VERSION ""

NS_ :

BS_:

BU_: ETH

BO_ 833 VCFRONT1_alertMatrix: 8 Vector__XXX
 SG_ VCFRONT1_matrixIndex M : 0|4@1+ (1,0) [0|0] "" Vector__XXX
 SG_ VCFRONT1_a001_WatchdogReset m0 : 4|1@1+ (1,0) [0|0] "" Vector__XXX
 SG_ VCFRONT1_a061_XCPConnected m1 : 4|1@1+ (1,0) [0|0] "" Vector__XXX
 SG_ VCFRONT1_a002_PowerLossReset m0 : 5|1@1+ (1,0) [0|0] "" Vector__XXX
 SG_ VCFRONT1_a062_XCPWasConnected m1 : 5|1@1+ (1,0) [0|0] "" Vector__XXX
 SG_ VCFRONT1_a122_ICR_MIA m2 : 5|1@1+ (1,0) [0|0] "" Vector__XXX
 SG_ VCFRONT1_a482_lvBridgeEFuseTrip m8 : 5|1@1+ (1,0) [0|0] "" Vector__XXX
 SG_ VCFRONT1_a003_SWAssertion m0 : 6|1@1+ (1,0) [0|0] "" Vector__XXX
 SG_ VCFRONT1_a063_SwitchFault m1 : 6|1@1+ (1,0) [0|0] "" Vector__XXX
 SG_ VCFRONT1_a423_rtosSleepFailed m7 : 6|1@1+ (1,0) [0|0] "" Vector__XXX
 SG_ VCFRONT1_a064_busSleepReqTimeout m1 : 7|1@1+ (1,0) [0|0] "" Vector__XXX
 SG_ VCFRONT1_a124_BB_MIA m2 : 7|1@1+ (1,0) [0|0] "" Vector__XXX
 SG_ VCFRONT1_a484_undervoltageSelfTestStuckOn m8 : 7|1@1+ (1,0) [0|0] "" Vector__XXX
 SG_ VCFRONT1_a005_CANTXError m0 : 8|1@1+ (1,0) [0|0] "" Vector__XXX
 SG_ VCFRONT1_a125_SCCM_MIA m2 : 8|1@1+ (1,0) [0|0] "" Vector__XXX
 SG_ VCFRONT1_a485_uvSelfTestLoadUnattemptedOnDbg m8 : 8|1@1+ (1,0) [0|0] "" Vector__XXX
 SG_ VCFRONT1_a006_CANTX_cyclicError m0 : 9|1@1+ (1,0) [0|0] "" Vector__XXX
 SG_ VCFRONT1_a126_EPAS3P_MIA m2 : 9|1@1+ (1,0) [0|0] "" Vector__XXX
 SG_ VCFRONT1_a486_undervoltageSelfTestBridgeSyncFailure m8 : 9|1@1+ (1,0) [0|0] "" Vector__XXX
 SG_ VCFRONT1_a127_iBoosterEFuseTrip m2 : 10|1@1+ (1,0) [0|0] "" Vector__XXX
 SG_ VCFRONT1_a128_vcrightEFuseTrip m2 : 11|1@1+ (1,0) [0|0] "" Vector__XXX
 SG_ VCFRONT1_a188_sleepFailed m3 : 11|1@1+ (1,0) [0|0] "" Vector__XXX
 SG_ VCFRONT1_a129_pcsEFuseTrip m2 : 12|1@1+ (1,0) [0|0] "" Vector__XXX
 SG_ VCFRONT1_a249_pcsOvClampTripped m4 : 12|1@1+ (1,0) [0|0] "" Vector__XXX
 SG_ VCFRONT1_a489_vnf1248SelfTestDebug m8 : 12|1@1+ (1,0) [0|0] "" Vector__XXX
 SG_ VCFRONT1_a130_autopilot2EFuseTrip m2 : 13|1@1+ (1,0) [0|0] "" Vector__XXX
 SG_ VCFRONT1_a250_pcsOvShutdownTripped m4 : 13|1@1+ (1,0) [0|0] "" Vector__XXX
 SG_ VCFRONT1_a490_vnf1248SelfTestFailure m8 : 13|1@1+ (1,0) [0|0] "" Vector__XXX
 SG_ VCFRONT1_a131_PCSCOMMON_MIA m2 : 14|1@1+ (1,0) [0|0] "" Vector__XXX
 SG_ VCFRONT1_a191_exitDriveDomainDown m3 : 14|1@1+ (1,0) [0|0] "" Vector__XXX
 SG_ VCFRONT1_a251_pcsOvShutdownSelfTestFailure m4 : 14|1@1+ (1,0) [0|0] "" Vector__XXX
 SG_ VCFRONT1_a491_vnf1248ConfigurationMismatch m8 : 14|1@1+ (1,0) [0|0] "" Vector__XXX
 SG_ VCFRONT1_a012_CPUReset m0 : 15|1@1+ (1,0) [0|0] "" Vector__XXX
 SG_ VCFRONT1_a132_epas2EFuseTrip m2 : 15|1@1+ (1,0) [0|0] "" Vector__XXX
 SG_ VCFRONT1_a252_pcsOvShutdownSelfTestStageFailure m4 : 15|1@1+ (1,0) [0|0] "" Vector__XXX
 SG_ VCFRONT1_a013_AlertManagerFault m0 : 16|1@1+ (1,0) [0|0] "" Vector__XXX
 SG_ VCFRONT1_a133_BRAKE_MIA m2 : 16|1@1+ (1,0) [0|0] "" Vector__XXX
 SG_ VCFRONT1_a253_pcsOvShutdownHighSideSelfTestDebug m4 : 16|1@1+ (1,0) [0|0] "" Vector__XXX
 SG_ VCFRONT1_a134_hvContactorsEFuseTrip m2 : 17|1@1+ (1,0) [0|0] "" Vector__XXX
 SG_ VCFRONT1_a015_NVMMError m0 : 18|1@1+ (1,0) [0|0] "" Vector__XXX
 SG_ VCFRONT1_a135_leftHeadlightEFuseTrip m2 : 18|1@1+ (1,0) [0|0] "" Vector__XXX
 SG_ VCFRONT1_a016_NVMMRecordError m0 : 19|1@1+ (1,0) [0|0] "" Vector__XXX
 SG_ VCFRONT1_a496_exitDriveWarningDomainDown m8 : 19|1@1+ (1,0) [0|0] "" Vector__XXX
 SG_ VCFRONT1_a017_NVMMStatusDbg m0 : 20|1@1+ (1,0) [0|0] "" Vector__XXX
 SG_ VCFRONT1_a077_VCBATT0_MIA m1 : 20|1@1+ (1,0) [0|0] "" Vector__XXX
 SG_ VCFRONT1_a617_APP_MIA m10 : 20|1@1+ (1,0) [0|0] "" Vector__XXX
 SG_ VCFRONT1_a018_HardFault m0 : 21|1@1+ (1,0) [0|0] "" Vector__XXX
 SG_ VCFRONT1_a078_VCBATT1_MIA m1 : 21|1@1+ (1,0) [0|0] "" Vector__XXX
 SG_ VCFRONT1_a019_BusFault m0 : 22|1@1+ (1,0) [0|0] "" Vector__XXX
 SG_ VCFRONT1_a079_VCBATT2_MIA m1 : 22|1@1+ (1,0) [0|0] "" Vector__XXX
 SG_ VCFRONT1_a080_VCFRONT0_MIA m1 : 23|1@1+ (1,0) [0|0] "" Vector__XXX
 SG_ VCFRONT1_a021_TaskSchedulerError m0 : 24|1@1+ (1,0) [0|0] "" Vector__XXX
 SG_ VCFRONT1_a081_VCFRONT1_MIA m1 : 24|1@1+ (1,0) [0|0] "" Vector__XXX
 SG_ VCFRONT1_a022_TaskInitError m0 : 25|1@1+ (1,0) [0|0] "" Vector__XXX
 SG_ VCFRONT1_a082_VCFRONT2_MIA m1 : 25|1@1+ (1,0) [0|0] "" Vector__XXX
 SG_ VCFRONT1_a262_vcrightVoltageMismatch m4 : 25|1@1+ (1,0) [0|0] "" Vector__XXX
 SG_ VCFRONT1_a263_pcsVoltageMismatch m4 : 26|1@1+ (1,0) [0|0] "" Vector__XXX
 SG_ VCFRONT1_a144_EPAS3S_MIA m2 : 27|1@1+ (1,0) [0|0] "" Vector__XXX
 SG_ VCFRONT1_a204_undervoltageLoadshedTriggered m3 : 27|1@1+ (1,0) [0|0] "" Vector__XXX
 SG_ VCFRONT1_a264_iBoosterVoltageMismatch m4 : 27|1@1+ (1,0) [0|0] "" Vector__XXX
 SG_ VCFRONT1_a205_overvoltageProtectionTriggered m3 : 28|1@1+ (1,0) [0|0] "" Vector__XXX
 SG_ VCFRONT1_a086_VCBATT_MIA m1 : 29|1@1+ (1,0) [0|0] "" Vector__XXX
 SG_ VCFRONT1_a266_EPAS2VoltageMismatch m4 : 29|1@1+ (1,0) [0|0] "" Vector__XXX
 SG_ VCFRONT1_a028_UsageFault m0 : 31|1@1+ (1,0) [0|0] "" Vector__XXX
 SG_ VCFRONT1_a029_CoreDump m0 : 32|1@1+ (1,0) [0|0] "" Vector__XXX
 SG_ VCFRONT1_a509_eFuseASICManagerStateMismatch m8 : 32|1@1+ (1,0) [0|0] "" Vector__XXX
 SG_ VCFRONT1_a030_ECULogUploadRequest m0 : 33|1@1+ (1,0) [0|0] "" Vector__XXX
 SG_ VCFRONT1_a090_APS_MIA m1 : 33|1@1+ (1,0) [0|0] "" Vector__XXX
 SG_ VCFRONT1_a031_UDSActive m0 : 34|1@1+ (1,0) [0|0] "" Vector__XXX
 SG_ VCFRONT1_a091_CMPD_MIA m1 : 34|1@1+ (1,0) [0|0] "" Vector__XXX
 SG_ VCFRONT1_a214_openCircuitDetected m3 : 37|1@1+ (1,0) [0|0] "" Vector__XXX
 SG_ VCFRONT1_a574_frontDriveInverterEFuseTrip m9 : 37|1@1+ (1,0) [0|0] "" Vector__XXX
 SG_ VCFRONT1_a036_UnknownIrq m0 : 39|1@1+ (1,0) [0|0] "" Vector__XXX
 SG_ VCFRONT1_a096_OCS1P_MIA m1 : 39|1@1+ (1,0) [0|0] "" Vector__XXX
 SG_ VCFRONT1_a216_powerCutoffImminent m3 : 39|1@1+ (1,0) [0|0] "" Vector__XXX
 SG_ VCFRONT1_a037_MemManageFault m0 : 40|1@1+ (1,0) [0|0] "" Vector__XXX
 SG_ VCFRONT1_a038_ProtFaultInfo m0 : 41|1@1+ (1,0) [0|0] "" Vector__XXX
 SG_ VCFRONT1_a098_DIR_MIA m1 : 41|1@1+ (1,0) [0|0] "" Vector__XXX
 SG_ VCFRONT1_a578_vbusFusedLoadShedEFuseTrip m9 : 41|1@1+ (1,0) [0|0] "" Vector__XXX
 SG_ VCFRONT1_a039_ProtFaultAddress m0 : 42|1@1+ (1,0) [0|0] "" Vector__XXX
 SG_ VCFRONT1_a040_Backtrace m0 : 43|1@1+ (1,0) [0|0] "" Vector__XXX
 SG_ VCFRONT1_a100_CANbus_MIA m1 : 43|1@1+ (1,0) [0|0] "" Vector__XXX
 SG_ VCFRONT1_a220_LVUnhealthy m3 : 43|1@1+ (1,0) [0|0] "" Vector__XXX
 SG_ VCFRONT1_a041_HighCPULoad m0 : 44|1@1+ (1,0) [0|0] "" Vector__XXX
 SG_ VCFRONT1_a581_harnessResistanceInfo m9 : 44|1@1+ (1,0) [0|0] "" Vector__XXX
 SG_ VCFRONT1_a042_HighStackUsage m0 : 45|1@1+ (1,0) [0|0] "" Vector__XXX
 SG_ VCFRONT1_a043_Task1msError m0 : 46|1@1+ (1,0) [0|0] "" Vector__XXX
 SG_ VCFRONT1_a103_CP_MIA m1 : 46|1@1+ (1,0) [0|0] "" Vector__XXX
 SG_ VCFRONT1_a223_bridgeOvervoltageSelfTestFailure m3 : 46|1@1+ (1,0) [0|0] "" Vector__XXX
 SG_ VCFRONT1_a044_Task10msError m0 : 47|1@1+ (1,0) [0|0] "" Vector__XXX
 SG_ VCFRONT1_a104_DAS_MIA m1 : 47|1@1+ (1,0) [0|0] "" Vector__XXX
 SG_ VCFRONT1_a164_eFuseLckoutMissing m2 : 47|1@1+ (1,0) [0|0] "" Vector__XXX
 SG_ VCFRONT1_a045_Task100msError m0 : 48|1@1+ (1,0) [0|0] "" Vector__XXX
 SG_ VCFRONT1_a105_TAS_MIA m1 : 48|1@1+ (1,0) [0|0] "" Vector__XXX
 SG_ VCFRONT1_a165_unxpctdEFuseLckout m2 : 48|1@1+ (1,0) [0|0] "" Vector__XXX
 SG_ VCFRONT1_a046_Task1000msError m0 : 49|1@1+ (1,0) [0|0] "" Vector__XXX
 SG_ VCFRONT1_a106_PCS_MIA m1 : 49|1@1+ (1,0) [0|0] "" Vector__XXX
 SG_ VCFRONT1_a107_BMS_MIA m1 : 50|1@1+ (1,0) [0|0] "" Vector__XXX
 SG_ VCFRONT1_a108_DIF_MIA m1 : 51|1@1+ (1,0) [0|0] "" Vector__XXX
 SG_ VCFRONT1_a229_LVHealthCompromised m3 : 52|1@1+ (1,0) [0|0] "" Vector__XXX
 SG_ VCFRONT1_a110_GTW_MIA m1 : 53|1@1+ (1,0) [0|0] "" Vector__XXX
 SG_ VCFRONT1_a590_vcrightPwrRationalityCurve m9 : 53|1@1+ (1,0) [0|0] "" Vector__XXX
 SG_ VCFRONT1_a111_EPBR_MIA m1 : 54|1@1+ (1,0) [0|0] "" Vector__XXX
 SG_ VCFRONT1_a591_vcrightFastBlowDetection m9 : 54|1@1+ (1,0) [0|0] "" Vector__XXX
 SG_ VCFRONT1_a112_EPBL_MIA m1 : 55|1@1+ (1,0) [0|0] "" Vector__XXX
 SG_ VCFRONT1_a113_UI_MIA m1 : 56|1@1+ (1,0) [0|0] "" Vector__XXX
 SG_ VCFRONT1_a114_ESP_MIA m1 : 57|1@1+ (1,0) [0|0] "" Vector__XXX
 SG_ VCFRONT1_a414_undervoltageSelfTestFailure m6 : 57|1@1+ (1,0) [0|0] "" Vector__XXX
 SG_ VCFRONT1_a115_VCSEC_MIA m1 : 58|1@1+ (1,0) [0|0] "" Vector__XXX
 SG_ VCFRONT1_a415_undervoltageSelfTestStuckOff m6 : 58|1@1+ (1,0) [0|0] "" Vector__XXX
 SG_ VCFRONT1_a475_vnf1248Fault m7 : 58|1@1+ (1,0) [0|0] "" Vector__XXX
 SG_ VCFRONT1_a116_VCRIGHT_MIA m1 : 59|1@1+ (1,0) [0|0] "" Vector__XXX
 SG_ VCFRONT1_a596_vcrightCurvePowerCutoff m9 : 59|1@1+ (1,0) [0|0] "" Vector__XXX
 SG_ VCFRONT1_a117_VCLEFT_MIA m1 : 60|1@1+ (1,0) [0|0] "" Vector__XXX
 SG_ VCFRONT1_a177_mcuAudioEFuseTrip m2 : 60|1@1+ (1,0) [0|0] "" Vector__XXX
 SG_ VCFRONT1_a597_vcrightFastBlowPowerCutoff m9 : 60|1@1+ (1,0) [0|0] "" Vector__XXX
 SG_ VCFRONT1_a058_inputRHighSyncDebug m0 : 61|1@1+ (1,0) [0|0] "" Vector__XXX
 SG_ VCFRONT1_a118_VCFRONT_MIA m1 : 61|1@1+ (1,0) [0|0] "" Vector__XXX
 SG_ VCFRONT1_a059_inputResistanceHigh m0 : 62|1@1+ (1,0) [0|0] "" Vector__XXX
 SG_ VCFRONT1_a119_SCCM_MIA m1 : 62|1@1+ (1,0) [0|0] "" Vector__XXX
 SG_ VCFRONT1_a060_engineeringBuild m0 : 63|1@1+ (1,0) [0|0] "" Vector__XXX
 SG_ VCFRONT1_a120_DI_DRIVE_MIA m1 : 63|1@1+ (1,0) [0|0] "" Vector__XXX

BO_ 834 VCFRONT2_alertMatrix: 8 Vector__XXX
 SG_ VCFRONT2_matrixIndex M : 0|4@1+ (1,0) [0|0] "" Vector__XXX
 SG_ VCFRONT2_a001_WatchdogReset m0 : 4|1@1+ (1,0) [0|0] "" Vector__XXX
 SG_ VCFRONT2_a061_XCPConnected m1 : 4|1@1+ (1,0) [0|0] "" Vector__XXX
 SG_ VCFRONT2_a301_wipersFactoryDisabled m5 : 4|1@1+ (1,0) [0|0] "" Vector__XXX
 SG_ VCFRONT2_a421_leftHeadlampUartCondition m7 : 4|1@1+ (1,0) [0|0] "" Vector__XXX
 SG_ VCFRONT2_a601_autopilotAirPurgeLimitReached m10 : 4|1@1+ (1,0) [0|0] "" Vector__XXX
 SG_ VCFRONT2_a661_mculessLeftHeadlampCurrentAlertDbg m11 : 4|1@1+ (1,0) [0|0] "" Vector__XXX
 SG_ VCFRONT2_a002_PowerLossReset m0 : 5|1@1+ (1,0) [0|0] "" Vector__XXX
 SG_ VCFRONT2_a062_XCPWasConnected m1 : 5|1@1+ (1,0) [0|0] "" Vector__XXX
 SG_ VCFRONT2_a122_ICR_MIA m2 : 5|1@1+ (1,0) [0|0] "" Vector__XXX
 SG_ VCFRONT2_a302_wiperCommError m5 : 5|1@1+ (1,0) [0|0] "" Vector__XXX
 SG_ VCFRONT2_a542_refrigerantReclaim m9 : 5|1@1+ (1,0) [0|0] "" Vector__XXX
 SG_ VCFRONT2_a003_SWAssertion m0 : 6|1@1+ (1,0) [0|0] "" Vector__XXX
 SG_ VCFRONT2_a063_SwitchFault m1 : 6|1@1+ (1,0) [0|0] "" Vector__XXX
 SG_ VCFRONT2_a123_VC_SECONDARY_LIGHTING_LEADER_MIA m2 : 6|1@1+ (1,0) [0|0] "" Vector__XXX
 SG_ VCFRONT2_a423_rtosSleepFailed m7 : 6|1@1+ (1,0) [0|0] "" Vector__XXX
 SG_ VCFRONT2_a543_compressorLowFlowDeliveryDetected m9 : 6|1@1+ (1,0) [0|0] "" Vector__XXX
 SG_ VCFRONT2_a663_leftHeadlampUartWaterMarkWarning m11 : 6|1@1+ (1,0) [0|0] "" Vector__XXX
 SG_ VCFRONT2_a064_busSleepReqTimeout m1 : 7|1@1+ (1,0) [0|0] "" Vector__XXX
 SG_ VCFRONT2_a124_BB_MIA m2 : 7|1@1+ (1,0) [0|0] "" Vector__XXX
 SG_ VCFRONT2_a184_cabinCoolingPerformanceAbnormal m3 : 7|1@1+ (1,0) [0|0] "" Vector__XXX
 SG_ VCFRONT2_a005_CANTXError m0 : 8|1@1+ (1,0) [0|0] "" Vector__XXX
 SG_ VCFRONT2_a125_SCCM_MIA m2 : 8|1@1+ (1,0) [0|0] "" Vector__XXX
 SG_ VCFRONT2_a365_burnInRoutineEntered m6 : 8|1@1+ (1,0) [0|0] "" Vector__XXX
 SG_ VCFRONT2_a665_leftHeadlampRetryInfo m11 : 8|1@1+ (1,0) [0|0] "" Vector__XXX
 SG_ VCFRONT2_a006_CANTX_cyclicError m0 : 9|1@1+ (1,0) [0|0] "" Vector__XXX
 SG_ VCFRONT2_a126_EPAS3P_MIA m2 : 9|1@1+ (1,0) [0|0] "" Vector__XXX
 SG_ VCFRONT2_a186_noDriveChgCableCon m3 : 9|1@1+ (1,0) [0|0] "" Vector__XXX
 SG_ VCFRONT2_a366_burnInRoutineExited m6 : 9|1@1+ (1,0) [0|0] "" Vector__XXX
 SG_ VCFRONT2_a546_leftLowOrHighBeamLightCondition m9 : 9|1@1+ (1,0) [0|0] "" Vector__XXX
 SG_ VCFRONT2_a606_chillerBattHeatingExit m10 : 9|1@1+ (1,0) [0|0] "" Vector__XXX
 SG_ VCFRONT2_a187_busesNotSleeping m3 : 10|1@1+ (1,0) [0|0] "" Vector__XXX
 SG_ VCFRONT2_a247_evapSolenoidFault m4 : 10|1@1+ (1,0) [0|0] "" Vector__XXX
 SG_ VCFRONT2_a367_dischargeRoutineEntered m6 : 10|1@1+ (1,0) [0|0] "" Vector__XXX
 SG_ VCFRONT2_a667_leftHeadlampRegionOrSideMismatch m11 : 10|1@1+ (1,0) [0|0] "" Vector__XXX
 SG_ VCFRONT2_a008_adaptiveHeadlightsUnavailableStalk m0 : 11|1@1+ (1,0) [0|0] "" Vector__XXX
 SG_ VCFRONT2_a188_sleepFailed m3 : 11|1@1+ (1,0) [0|0] "" Vector__XXX
 SG_ VCFRONT2_a368_dischargeRoutineExited m6 : 11|1@1+ (1,0) [0|0] "" Vector__XXX
 SG_ VCFRONT2_a009_LCCPurgeAttempted m0 : 12|1@1+ (1,0) [0|0] "" Vector__XXX
 SG_ VCFRONT2_a249_coolantValveBadMode m4 : 12|1@1+ (1,0) [0|0] "" Vector__XXX
 SG_ VCFRONT2_a369_reducedPowerDischarge m6 : 12|1@1+ (1,0) [0|0] "" Vector__XXX
 SG_ VCFRONT2_a489_ValveStuckFlagged m8 : 12|1@1+ (1,0) [0|0] "" Vector__XXX
 SG_ VCFRONT2_a669_thermalHVPowerBudgetActive m11 : 12|1@1+ (1,0) [0|0] "" Vector__XXX
 SG_ VCFRONT2_a250_headlampsNotAimed m4 : 13|1@1+ (1,0) [0|0] "" Vector__XXX
 SG_ VCFRONT2_a490_coolantPumpsNotIdentified m8 : 13|1@1+ (1,0) [0|0] "" Vector__XXX
 SG_ VCFRONT2_a610_driveEntryDelayed m10 : 13|1@1+ (1,0) [0|0] "" Vector__XXX
 SG_ VCFRONT2_a131_PCSCOMMON_MIA m2 : 14|1@1+ (1,0) [0|0] "" Vector__XXX
 SG_ VCFRONT2_a251_UIWakeupTrigger m4 : 14|1@1+ (1,0) [0|0] "" Vector__XXX
 SG_ VCFRONT2_a611_poorRadiatorHeatRejection m10 : 14|1@1+ (1,0) [0|0] "" Vector__XXX
 SG_ VCFRONT2_a012_CPUReset m0 : 15|1@1+ (1,0) [0|0] "" Vector__XXX
 SG_ VCFRONT2_a612_selfTestsBlockingDrive m10 : 15|1@1+ (1,0) [0|0] "" Vector__XXX
 SG_ VCFRONT2_a013_AlertManagerFault m0 : 16|1@1+ (1,0) [0|0] "" Vector__XXX
 SG_ VCFRONT2_a133_BRAKE_MIA m2 : 16|1@1+ (1,0) [0|0] "" Vector__XXX
 SG_ VCFRONT2_a254_pumpBatStopped m4 : 17|1@1+ (1,0) [0|0] "" Vector__XXX
 SG_ VCFRONT2_a374_lccInletSolenoidFault m6 : 17|1@1+ (1,0) [0|0] "" Vector__XXX
 SG_ VCFRONT2_a015_NVMMError m0 : 18|1@1+ (1,0) [0|0] "" Vector__XXX
 SG_ VCFRONT2_a135_coolantLevelLow m2 : 18|1@1+ (1,0) [0|0] "" Vector__XXX
 SG_ VCFRONT2_a195_drveBlckdVltgeTooHgh m3 : 18|1@1+ (1,0) [0|0] "" Vector__XXX
 SG_ VCFRONT2_a016_NVMMRecordError m0 : 19|1@1+ (1,0) [0|0] "" Vector__XXX
 SG_ VCFRONT2_a136_refrigDischTempSns m2 : 19|1@1+ (1,0) [0|0] "" Vector__XXX
 SG_ VCFRONT2_a017_NVMMStatusDbg m0 : 20|1@1+ (1,0) [0|0] "" Vector__XXX
 SG_ VCFRONT2_a077_VCBATT0_MIA m1 : 20|1@1+ (1,0) [0|0] "" Vector__XXX
 SG_ VCFRONT2_a137_refrigDischPresSns m2 : 20|1@1+ (1,0) [0|0] "" Vector__XXX
 SG_ VCFRONT2_a377_wiperParkFault m6 : 20|1@1+ (1,0) [0|0] "" Vector__XXX
 SG_ VCFRONT2_a617_APP_MIA m10 : 20|1@1+ (1,0) [0|0] "" Vector__XXX
 SG_ VCFRONT2_a018_HardFault m0 : 21|1@1+ (1,0) [0|0] "" Vector__XXX
 SG_ VCFRONT2_a078_VCBATT1_MIA m1 : 21|1@1+ (1,0) [0|0] "" Vector__XXX
 SG_ VCFRONT2_a138_refrigSuctTempSns m2 : 21|1@1+ (1,0) [0|0] "" Vector__XXX
 SG_ VCFRONT2_a378_wiperECUDebug m6 : 21|1@1+ (1,0) [0|0] "" Vector__XXX
 SG_ VCFRONT2_a618_cabinCoolingCapacityLimited m10 : 21|1@1+ (1,0) [0|0] "" Vector__XXX
 SG_ VCFRONT2_a019_BusFault m0 : 22|1@1+ (1,0) [0|0] "" Vector__XXX
 SG_ VCFRONT2_a079_VCBATT2_MIA m1 : 22|1@1+ (1,0) [0|0] "" Vector__XXX
 SG_ VCFRONT2_a139_refrigSuctPresSns m2 : 22|1@1+ (1,0) [0|0] "" Vector__XXX
 SG_ VCFRONT2_a499_loadShedPumpFlowRequest m8 : 22|1@1+ (1,0) [0|0] "" Vector__XXX
 SG_ VCFRONT2_a080_VCFRONT0_MIA m1 : 23|1@1+ (1,0) [0|0] "" Vector__XXX
 SG_ VCFRONT2_a140_coolantTempPtSns m2 : 23|1@1+ (1,0) [0|0] "" Vector__XXX
 SG_ VCFRONT2_a380_chillerExvWarning m6 : 23|1@1+ (1,0) [0|0] "" Vector__XXX
 SG_ VCFRONT2_a560_compressorHighSuperheat m9 : 23|1@1+ (1,0) [0|0] "" Vector__XXX
 SG_ VCFRONT2_a620_pumpAirLock m10 : 23|1@1+ (1,0) [0|0] "" Vector__XXX
 SG_ VCFRONT2_a021_TaskSchedulerError m0 : 24|1@1+ (1,0) [0|0] "" Vector__XXX
 SG_ VCFRONT2_a081_VCFRONT1_MIA m1 : 24|1@1+ (1,0) [0|0] "" Vector__XXX
 SG_ VCFRONT2_a141_coolantTempBatSns m2 : 24|1@1+ (1,0) [0|0] "" Vector__XXX
 SG_ VCFRONT2_a381_evaporatorExvWarning m6 : 24|1@1+ (1,0) [0|0] "" Vector__XXX
 SG_ VCFRONT2_a621_coolantAirPurgeIncomplete m10 : 24|1@1+ (1,0) [0|0] "" Vector__XXX
 SG_ VCFRONT2_a022_TaskInitError m0 : 25|1@1+ (1,0) [0|0] "" Vector__XXX
 SG_ VCFRONT2_a082_VCFRONT2_MIA m1 : 25|1@1+ (1,0) [0|0] "" Vector__XXX
 SG_ VCFRONT2_a142_exvMotorFault m2 : 25|1@1+ (1,0) [0|0] "" Vector__XXX
 SG_ VCFRONT2_a382_recircExvWarning m6 : 25|1@1+ (1,0) [0|0] "" Vector__XXX
 SG_ VCFRONT2_a622_pumpDetectsLowCoolantFlow m10 : 25|1@1+ (1,0) [0|0] "" Vector__XXX
 SG_ VCFRONT2_a143_powerLossDuringSleep m2 : 26|1@1+ (1,0) [0|0] "" Vector__XXX
 SG_ VCFRONT2_a383_lccExvWarning m6 : 26|1@1+ (1,0) [0|0] "" Vector__XXX
 SG_ VCFRONT2_a563_chargePortDoorOpenBlockedByBrake m9 : 26|1@1+ (1,0) [0|0] "" Vector__XXX
 SG_ VCFRONT2_a144_EPAS3S_MIA m2 : 27|1@1+ (1,0) [0|0] "" Vector__XXX
 SG_ VCFRONT2_a384_ccLeftExvWarning m6 : 27|1@1+ (1,0) [0|0] "" Vector__XXX
 SG_ VCFRONT2_a504_airInRefrigerantDetected m8 : 27|1@1+ (1,0) [0|0] "" Vector__XXX
 SG_ VCFRONT2_a564_leftHeadlampAimingDebug m9 : 27|1@1+ (1,0) [0|0] "" Vector__XXX
 SG_ VCFRONT2_a385_ccRightExvWarning m6 : 28|1@1+ (1,0) [0|0] "" Vector__XXX
 SG_ VCFRONT2_a565_userPresenceDisplayStateMismatch m9 : 28|1@1+ (1,0) [0|0] "" Vector__XXX
 SG_ VCFRONT2_a086_VCBATT_MIA m1 : 29|1@1+ (1,0) [0|0] "" Vector__XXX
 SG_ VCFRONT2_a386_exvMotorWarning m6 : 29|1@1+ (1,0) [0|0] "" Vector__XXX
 SG_ VCFRONT2_a446_cabinHVACUnavailableContext m7 : 29|1@1+ (1,0) [0|0] "" Vector__XXX
 SG_ VCFRONT2_a506_invalidRefrigerantSystemConfig m8 : 29|1@1+ (1,0) [0|0] "" Vector__XXX
 SG_ VCFRONT2_a566_leftFrontTurnLightFault m9 : 29|1@1+ (1,0) [0|0] "" Vector__XXX
 SG_ VCFRONT2_a447_cabinHVACUnavailable m7 : 30|1@1+ (1,0) [0|0] "" Vector__XXX
 SG_ VCFRONT2_a507_leftHeadlampAimingFault m8 : 30|1@1+ (1,0) [0|0] "" Vector__XXX
 SG_ VCFRONT2_a028_UsageFault m0 : 31|1@1+ (1,0) [0|0] "" Vector__XXX
 SG_ VCFRONT2_a568_leftDaytimeRunningLightFault m9 : 31|1@1+ (1,0) [0|0] "" Vector__XXX
 SG_ VCFRONT2_a029_CoreDump m0 : 32|1@1+ (1,0) [0|0] "" Vector__XXX
 SG_ VCFRONT2_a030_ECULogUploadRequest m0 : 33|1@1+ (1,0) [0|0] "" Vector__XXX
 SG_ VCFRONT2_a090_APS_MIA m1 : 33|1@1+ (1,0) [0|0] "" Vector__XXX
 SG_ VCFRONT2_a150_pumpBatLowRPMCBang m2 : 33|1@1+ (1,0) [0|0] "" Vector__XXX
 SG_ VCFRONT2_a210_coolantValveCalib m3 : 33|1@1+ (1,0) [0|0] "" Vector__XXX
 SG_ VCFRONT2_a570_headlampsAdaptedToLeftHandTraffic m9 : 33|1@1+ (1,0) [0|0] "" Vector__XXX
 SG_ VCFRONT2_a630_leftHeadlampFactoryFault m10 : 33|1@1+ (1,0) [0|0] "" Vector__XXX
 SG_ VCFRONT2_a031_UDSActive m0 : 34|1@1+ (1,0) [0|0] "" Vector__XXX
 SG_ VCFRONT2_a091_CMPD_MIA m1 : 34|1@1+ (1,0) [0|0] "" Vector__XXX
 SG_ VCFRONT2_a451_refrigerantNotCommissioned m7 : 34|1@1+ (1,0) [0|0] "" Vector__XXX
 SG_ VCFRONT2_a511_DCDCSaturationLoadShed m8 : 34|1@1+ (1,0) [0|0] "" Vector__XXX
 SG_ VCFRONT2_a571_headlampsAdaptedToRightHandTraffic m9 : 34|1@1+ (1,0) [0|0] "" Vector__XXX
 SG_ VCFRONT2_a452_dischargePresSensIntermittent m7 : 35|1@1+ (1,0) [0|0] "" Vector__XXX
 SG_ VCFRONT2_a572_hvacCompressorEFuseTrip m9 : 35|1@1+ (1,0) [0|0] "" Vector__XXX
 SG_ VCFRONT2_a153_userPresenceDisplayMismatchClrd m2 : 36|1@1+ (1,0) [0|0] "" Vector__XXX
 SG_ VCFRONT2_a273_wiperFrictionModelFault m4 : 36|1@1+ (1,0) [0|0] "" Vector__XXX
 SG_ VCFRONT2_a393_ambientTempNetworkSna m6 : 36|1@1+ (1,0) [0|0] "" Vector__XXX
 SG_ VCFRONT2_a453_dischargeTempSensIntermittent m7 : 36|1@1+ (1,0) [0|0] "" Vector__XXX
 SG_ VCFRONT2_a214_ptPumpCompromised m3 : 37|1@1+ (1,0) [0|0] "" Vector__XXX
 SG_ VCFRONT2_a394_pressureSensorCheckFault m6 : 37|1@1+ (1,0) [0|0] "" Vector__XXX
 SG_ VCFRONT2_a454_suctionPresSensIntermittent m7 : 37|1@1+ (1,0) [0|0] "" Vector__XXX
 SG_ VCFRONT2_a155_autopilotDriveNotAuthed m2 : 38|1@1+ (1,0) [0|0] "" Vector__XXX
 SG_ VCFRONT2_a215_ptPumpMIA m3 : 38|1@1+ (1,0) [0|0] "" Vector__XXX
 SG_ VCFRONT2_a395_pressureSensorCheckInconclusive m6 : 38|1@1+ (1,0) [0|0] "" Vector__XXX
 SG_ VCFRONT2_a455_suctionTempSensIntermittent m7 : 38|1@1+ (1,0) [0|0] "" Vector__XXX
 SG_ VCFRONT2_a036_UnknownIrq m0 : 39|1@1+ (1,0) [0|0] "" Vector__XXX
 SG_ VCFRONT2_a096_OCS1P_MIA m1 : 39|1@1+ (1,0) [0|0] "" Vector__XXX
 SG_ VCFRONT2_a396_coolantLevelLowUserFacing m6 : 39|1@1+ (1,0) [0|0] "" Vector__XXX
 SG_ VCFRONT2_a456_liquidPresSensIntermittent m7 : 39|1@1+ (1,0) [0|0] "" Vector__XXX
 SG_ VCFRONT2_a037_MemManageFault m0 : 40|1@1+ (1,0) [0|0] "" Vector__XXX
 SG_ VCFRONT2_a217_battPumpCompromised m3 : 40|1@1+ (1,0) [0|0] "" Vector__XXX
 SG_ VCFRONT2_a397_temperatureSensorCheckFault m6 : 40|1@1+ (1,0) [0|0] "" Vector__XXX
 SG_ VCFRONT2_a457_liquidTempSensIntermittent m7 : 40|1@1+ (1,0) [0|0] "" Vector__XXX
 SG_ VCFRONT2_a697_leftHeadlampNotAimed m11 : 40|1@1+ (1,0) [0|0] "" Vector__XXX
 SG_ VCFRONT2_a038_ProtFaultInfo m0 : 41|1@1+ (1,0) [0|0] "" Vector__XXX
 SG_ VCFRONT2_a098_DIR_MIA m1 : 41|1@1+ (1,0) [0|0] "" Vector__XXX
 SG_ VCFRONT2_a218_socMonitorDetectedThresholdSoc m3 : 41|1@1+ (1,0) [0|0] "" Vector__XXX
 SG_ VCFRONT2_a398_tempSensorCheckInconclusive m6 : 41|1@1+ (1,0) [0|0] "" Vector__XXX
 SG_ VCFRONT2_a458_grosslyLowRefrigerant m7 : 41|1@1+ (1,0) [0|0] "" Vector__XXX
 SG_ VCFRONT2_a578_vbusFusedLowCurrentFeedEFuseTrip m9 : 41|1@1+ (1,0) [0|0] "" Vector__XXX
 SG_ VCFRONT2_a039_ProtFaultAddress m0 : 42|1@1+ (1,0) [0|0] "" Vector__XXX
 SG_ VCFRONT2_a159_coolantValveFault m2 : 42|1@1+ (1,0) [0|0] "" Vector__XXX
 SG_ VCFRONT2_a279_refrigLiquidTempSns m4 : 42|1@1+ (1,0) [0|0] "" Vector__XXX
 SG_ VCFRONT2_a459_thermalFillAndDrive m7 : 42|1@1+ (1,0) [0|0] "" Vector__XXX
 SG_ VCFRONT2_a040_Backtrace m0 : 43|1@1+ (1,0) [0|0] "" Vector__XXX
 SG_ VCFRONT2_a100_CANbus_MIA m1 : 43|1@1+ (1,0) [0|0] "" Vector__XXX
 SG_ VCFRONT2_a160_compressorInhibited m2 : 43|1@1+ (1,0) [0|0] "" Vector__XXX
 SG_ VCFRONT2_a280_refrigLiquidPresSns m4 : 43|1@1+ (1,0) [0|0] "" Vector__XXX
 SG_ VCFRONT2_a460_hardIsentropicTdFailed m7 : 43|1@1+ (1,0) [0|0] "" Vector__XXX
 SG_ VCFRONT2_a041_HighCPULoad m0 : 44|1@1+ (1,0) [0|0] "" Vector__XXX
 SG_ VCFRONT2_a161_compressorSelfFault m2 : 44|1@1+ (1,0) [0|0] "" Vector__XXX
 SG_ VCFRONT2_a281_alcoholInterlockBlockingDrive m4 : 44|1@1+ (1,0) [0|0] "" Vector__XXX
 SG_ VCFRONT2_a042_HighStackUsage m0 : 45|1@1+ (1,0) [0|0] "" Vector__XXX
 SG_ VCFRONT2_a162_compressorInhibitedContext m2 : 45|1@1+ (1,0) [0|0] "" Vector__XXX
 SG_ VCFRONT2_a282_coolantLevelSensorFault m4 : 45|1@1+ (1,0) [0|0] "" Vector__XXX
 SG_ VCFRONT2_a043_Task1msError m0 : 46|1@1+ (1,0) [0|0] "" Vector__XXX
 SG_ VCFRONT2_a103_CP_MIA m1 : 46|1@1+ (1,0) [0|0] "" Vector__XXX
 SG_ VCFRONT2_a163_compressorDisabledFSR m2 : 46|1@1+ (1,0) [0|0] "" Vector__XXX
 SG_ VCFRONT2_a283_thmlFanLimitedByCurrent m4 : 46|1@1+ (1,0) [0|0] "" Vector__XXX
 SG_ VCFRONT2_a044_Task10msError m0 : 47|1@1+ (1,0) [0|0] "" Vector__XXX
 SG_ VCFRONT2_a104_DAS_MIA m1 : 47|1@1+ (1,0) [0|0] "" Vector__XXX
 SG_ VCFRONT2_a284_chillerExvFault m4 : 47|1@1+ (1,0) [0|0] "" Vector__XXX
 SG_ VCFRONT2_a464_highFlowIndexHighSubcoolFlagged m7 : 47|1@1+ (1,0) [0|0] "" Vector__XXX
 SG_ VCFRONT2_a045_Task100msError m0 : 48|1@1+ (1,0) [0|0] "" Vector__XXX
 SG_ VCFRONT2_a105_TAS_MIA m1 : 48|1@1+ (1,0) [0|0] "" Vector__XXX
 SG_ VCFRONT2_a225_driveBlckdByShowroom m3 : 48|1@1+ (1,0) [0|0] "" Vector__XXX
 SG_ VCFRONT2_a285_evaporatorExvFault m4 : 48|1@1+ (1,0) [0|0] "" Vector__XXX
 SG_ VCFRONT2_a465_lowFlowIndexHighSubcoolFlagged m7 : 48|1@1+ (1,0) [0|0] "" Vector__XXX
 SG_ VCFRONT2_a585_bothHeadlampsInternalError m9 : 48|1@1+ (1,0) [0|0] "" Vector__XXX
 SG_ VCFRONT2_a046_Task1000msError m0 : 49|1@1+ (1,0) [0|0] "" Vector__XXX
 SG_ VCFRONT2_a106_PCS_MIA m1 : 49|1@1+ (1,0) [0|0] "" Vector__XXX
 SG_ VCFRONT2_a226_battPumpMIA m3 : 49|1@1+ (1,0) [0|0] "" Vector__XXX
 SG_ VCFRONT2_a286_recircExvFault m4 : 49|1@1+ (1,0) [0|0] "" Vector__XXX
 SG_ VCFRONT2_a466_highFlowIndexLowSubcoolFlagged m7 : 49|1@1+ (1,0) [0|0] "" Vector__XXX
 SG_ VCFRONT2_a107_BMS_MIA m1 : 50|1@1+ (1,0) [0|0] "" Vector__XXX
 SG_ VCFRONT2_a167_leftHCMMIA m2 : 50|1@1+ (1,0) [0|0] "" Vector__XXX
 SG_ VCFRONT2_a287_lccExvFault m4 : 50|1@1+ (1,0) [0|0] "" Vector__XXX
 SG_ VCFRONT2_a467_lowPowerIndexFlagged m7 : 50|1@1+ (1,0) [0|0] "" Vector__XXX
 SG_ VCFRONT2_a108_DIF_MIA m1 : 51|1@1+ (1,0) [0|0] "" Vector__XXX
 SG_ VCFRONT2_a288_ccLeftExvFault m4 : 51|1@1+ (1,0) [0|0] "" Vector__XXX
 SG_ VCFRONT2_a468_highPowerIndexFlagged m7 : 51|1@1+ (1,0) [0|0] "" Vector__XXX
 SG_ VCFRONT2_a289_ccRightExvFault m4 : 52|1@1+ (1,0) [0|0] "" Vector__XXX
 SG_ VCFRONT2_a409_invalidConfiguration m6 : 52|1@1+ (1,0) [0|0] "" Vector__XXX
 SG_ VCFRONT2_a469_prvPopDetected m7 : 52|1@1+ (1,0) [0|0] "" Vector__XXX
 SG_ VCFRONT2_a110_GTW_MIA m1 : 53|1@1+ (1,0) [0|0] "" Vector__XXX
 SG_ VCFRONT2_a470_implausiblePdPlDetected m7 : 53|1@1+ (1,0) [0|0] "" Vector__XXX
 SG_ VCFRONT2_a111_EPBR_MIA m1 : 54|1@1+ (1,0) [0|0] "" Vector__XXX
 SG_ VCFRONT2_a171_driveBlckdByMsmtch m2 : 54|1@1+ (1,0) [0|0] "" Vector__XXX
 SG_ VCFRONT2_a471_hcm5Debug m7 : 54|1@1+ (1,0) [0|0] "" Vector__XXX
 SG_ VCFRONT2_a531_lowPowerIndexFlaggedUserFacing m8 : 54|1@1+ (1,0) [0|0] "" Vector__XXX
 SG_ VCFRONT2_a112_EPBL_MIA m1 : 55|1@1+ (1,0) [0|0] "" Vector__XXX
 SG_ VCFRONT2_a172_wsteHtBlckdByMsmtch m2 : 55|1@1+ (1,0) [0|0] "" Vector__XXX
 SG_ VCFRONT2_a232_lowSideControllerHighFdbk m3 : 55|1@1+ (1,0) [0|0] "" Vector__XXX
 SG_ VCFRONT2_a053_wiperCommErrorUser m0 : 56|1@1+ (1,0) [0|0] "" Vector__XXX
 SG_ VCFRONT2_a113_UI_MIA m1 : 56|1@1+ (1,0) [0|0] "" Vector__XXX
 SG_ VCFRONT2_a173_HVBlckdByMsmtch m2 : 56|1@1+ (1,0) [0|0] "" Vector__XXX
 SG_ VCFRONT2_a054_compressorLowFlowUserFacing m0 : 57|1@1+ (1,0) [0|0] "" Vector__XXX
 SG_ VCFRONT2_a114_ESP_MIA m1 : 57|1@1+ (1,0) [0|0] "" Vector__XXX
 SG_ VCFRONT2_a174_driveNotAuthed m2 : 57|1@1+ (1,0) [0|0] "" Vector__XXX
 SG_ VCFRONT2_a294_leftSideRepeaterLightFault m4 : 57|1@1+ (1,0) [0|0] "" Vector__XXX
 SG_ VCFRONT2_a474_leftHeadlampInternalError m7 : 57|1@1+ (1,0) [0|0] "" Vector__XXX
 SG_ VCFRONT2_a534_chillerExvCalibInitDebug m8 : 57|1@1+ (1,0) [0|0] "" Vector__XXX
 SG_ VCFRONT2_a115_VCSEC_MIA m1 : 58|1@1+ (1,0) [0|0] "" Vector__XXX
 SG_ VCFRONT2_a235_ptTempSnsIrrational m3 : 58|1@1+ (1,0) [0|0] "" Vector__XXX
 SG_ VCFRONT2_a355_coolantSysLockout m5 : 58|1@1+ (1,0) [0|0] "" Vector__XXX
 SG_ VCFRONT2_a535_evapExvCalibInitDebug m8 : 58|1@1+ (1,0) [0|0] "" Vector__XXX
 SG_ VCFRONT2_a116_VCRIGHT_MIA m1 : 59|1@1+ (1,0) [0|0] "" Vector__XXX
 SG_ VCFRONT2_a176_vehicleInSelfTest m2 : 59|1@1+ (1,0) [0|0] "" Vector__XXX
 SG_ VCFRONT2_a236_batTempSnsIrrational m3 : 59|1@1+ (1,0) [0|0] "" Vector__XXX
 SG_ VCFRONT2_a356_refrigSysLockout m5 : 59|1@1+ (1,0) [0|0] "" Vector__XXX
 SG_ VCFRONT2_a536_recircExvCalibInitDebug m8 : 59|1@1+ (1,0) [0|0] "" Vector__XXX
 SG_ VCFRONT2_a117_VCLEFT_MIA m1 : 60|1@1+ (1,0) [0|0] "" Vector__XXX
 SG_ VCFRONT2_a537_lccExvCalibInitDebug m8 : 60|1@1+ (1,0) [0|0] "" Vector__XXX
 SG_ VCFRONT2_a058_inputRHighSyncDebug m0 : 61|1@1+ (1,0) [0|0] "" Vector__XXX
 SG_ VCFRONT2_a118_VCFRONT_MIA m1 : 61|1@1+ (1,0) [0|0] "" Vector__XXX
 SG_ VCFRONT2_a178_compLiquidPumpOut m2 : 61|1@1+ (1,0) [0|0] "" Vector__XXX
 SG_ VCFRONT2_a298_radiatorLowAirFlowDetected m4 : 61|1@1+ (1,0) [0|0] "" Vector__XXX
 SG_ VCFRONT2_a538_cclExvCalibInitDebug m8 : 61|1@1+ (1,0) [0|0] "" Vector__XXX
 SG_ VCFRONT2_a059_inputResistanceHigh m0 : 62|1@1+ (1,0) [0|0] "" Vector__XXX
 SG_ VCFRONT2_a119_SCCM_MIA m1 : 62|1@1+ (1,0) [0|0] "" Vector__XXX
 SG_ VCFRONT2_a539_ccrExvCalibInitDebug m8 : 62|1@1+ (1,0) [0|0] "" Vector__XXX
 SG_ VCFRONT2_a060_engineeringBuild m0 : 63|1@1+ (1,0) [0|0] "" Vector__XXX
 SG_ VCFRONT2_a120_DI_DRIVE_MIA m1 : 63|1@1+ (1,0) [0|0] "" Vector__XXX
 SG_ VCFRONT2_a240_lowSideCompromised m3 : 63|1@1+ (1,0) [0|0] "" Vector__XXX
 SG_ VCFRONT2_a360_ungracefulAccPlusExit m5 : 63|1@1+ (1,0) [0|0] "" Vector__XXX
 SG_ VCFRONT2_a420_holidayParty m6 : 63|1@1+ (1,0) [0|0] "" Vector__XXX
 SG_ VCFRONT2_a540_radiatorSteamDetected m8 : 63|1@1+ (1,0) [0|0] "" Vector__XXX

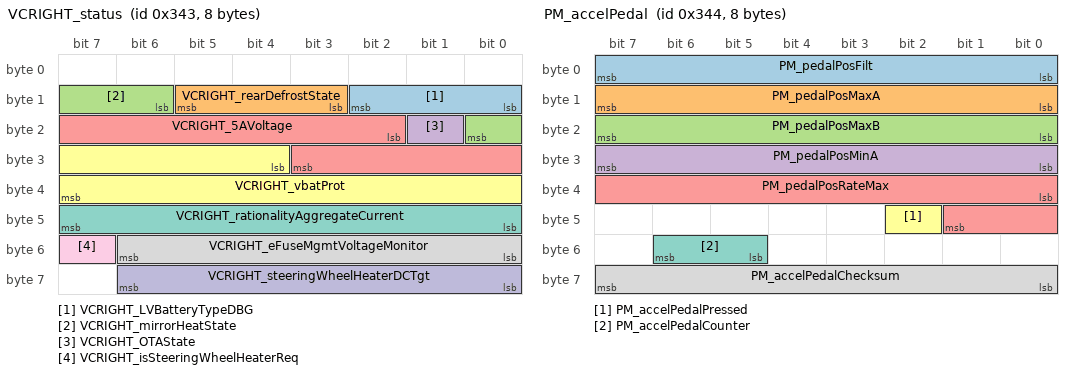
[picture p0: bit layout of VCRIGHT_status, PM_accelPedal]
BO_ 835 VCRIGHT_status: 8 Vector__XXX
 SG_ VCRIGHT_LVBatteryTypeDBG : 8|3@1+ (1,0) [0|0] "" Vector__XXX
 SG_ VCRIGHT_rearDefrostState : 11|3@1+ (1,0) [0|0] "" Vector__XXX
 SG_ VCRIGHT_mirrorHeatState : 14|3@1+ (1,0) [0|0] "" Vector__XXX
 SG_ VCRIGHT_OTAState : 17|1@1+ (1,0) [0|0] "" Vector__XXX
 SG_ VCRIGHT_5AVoltage : 18|10@1+ (0.005443676098,0) [0|0] "" Vector__XXX
 SG_ VCRIGHT_vbatProt : 28|12@1+ (0.005443676098,0) [0|0] "" Vector__XXX
 SG_ VCRIGHT_rationalityAggregateCurrent : 40|8@1+ (0.5,0) [0|0] "" Vector__XXX
 SG_ VCRIGHT_eFuseMgmtVoltageMonitor : 48|7@1+ (0.125,0) [0|0] "" Vector__XXX
 SG_ VCRIGHT_isSteeringWheelHeaterReq : 55|1@1+ (1,0) [0|0] "" Vector__XXX
 SG_ VCRIGHT_steeringWheelHeaterDCTgt : 56|7@1+ (0.01,0) [0|0] "" Vector__XXX

BO_ 836 PM_accelPedal: 8 Vector__XXX
 SG_ PM_pedalPosFilt : 0|8@1+ (0.4,0) [0|0] "" Vector__XXX
 SG_ PM_pedalPosMaxA : 8|8@1+ (0.4,0) [0|0] "" Vector__XXX
 SG_ PM_pedalPosMaxB : 16|8@1+ (0.4,0) [0|0] "" Vector__XXX
 SG_ PM_pedalPosMinA : 24|8@1+ (0.4,0) [0|0] "" Vector__XXX
 SG_ PM_pedalPosRateMax : 32|10@1+ (3,0) [0|0] "" Vector__XXX
 SG_ PM_accelPedalPressed : 42|1@1+ (1,0) [0|0] "" Vector__XXX
 SG_ PM_accelPedalCounter : 53|2@1+ (1,0) [0|0] "" Vector__XXX
 SG_ PM_accelPedalChecksum : 56|8@1+ (1,0) [0|0] "" Vector__XXX

BO_ 837 PTC_info: 8 Vector__XXX
 SG_ PTC_infoIndex M : 0|8@1+ (1,0) [0|0] "" Vector__XXX
 SG_ PTC_infoAppGitHash m17 : 8|56@1+ (1,0) [0|0] "" Vector__XXX
 SG_ PTC_infoBootGitHash m18 : 8|56@1+ (1,0) [0|0] "" Vector__XXX
 SG_ PTC_infoBootSvnRev m14 : 8|24@1+ (1,0) [0|0] "" Vector__XXX
 SG_ PTC_infoBootUdsProtoVersion m20 : 8|8@1+ (1,0) [0|0] "" Vector__XXX
 SG_ PTC_infoBuildType m10 : 8|3@1+ (1,0) [0|0] "" Vector__XXX
 SG_ PTC_infoPlatformType m13 : 8|8@1+ (1,0) [0|0] "" Vector__XXX
 SG_ PTC_infoBuildConfigId m10 : 16|16@1+ (1,0) [0|0] "" Vector__XXX
 SG_ PTC_infoPcbaId m11 : 16|8@1+ (1,0) [0|0] "" Vector__XXX
 SG_ PTC_infoAssemblyId m11 : 24|8@1+ (1,0) [0|0] "" Vector__XXX
 SG_ PTC_infoAppCrc m13 : 32|32@1+ (1,0) [0|0] "" Vector__XXX
 SG_ PTC_infoBootCrc m20 : 32|32@1+ (1,0) [0|0] "" Vector__XXX
 SG_ PTC_infoBootSvnUrlHash m14 : 32|32@1+ (1,0) [0|0] "" Vector__XXX
 SG_ PTC_infoHardwareId m10 : 32|16@1+ (1,0) [0|0] "" Vector__XXX
 SG_ PTC_infoUsageId m11 : 32|16@1+ (1,0) [0|0] "" Vector__XXX
 SG_ PTC_infoComponentId m10 : 48|16@1+ (1,0) [0|0] "" Vector__XXX
 SG_ PTC_infoSubUsageId m11 : 48|16@1+ (1,0) [0|0] "" Vector__XXX

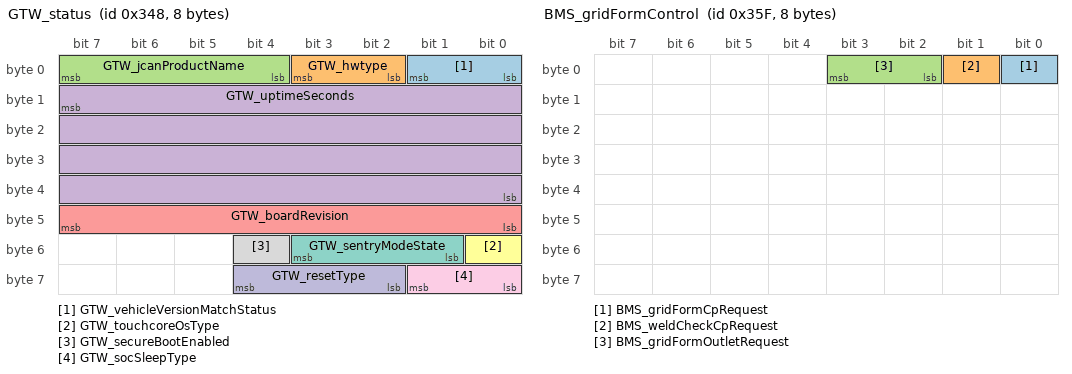
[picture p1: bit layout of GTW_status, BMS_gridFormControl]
BO_ 840 GTW_status: 8 Vector__XXX
 SG_ GTW_vehicleVersionMatchStatus : 0|2@1+ (1,0) [0|0] "" Vector__XXX
 SG_ GTW_hwtype : 2|2@1+ (1,0) [0|0] "" Vector__XXX
 SG_ GTW_jcanProductName : 4|4@1+ (1,0) [0|0] "" Vector__XXX
 SG_ GTW_uptimeSeconds : 15|32@0+ (1,0) [0|0] "" Vector__XXX
 SG_ GTW_boardRevision : 40|8@1+ (1,0) [0|0] "" Vector__XXX
 SG_ GTW_touchcoreOsType : 48|1@1+ (1,0) [0|0] "" Vector__XXX
 SG_ GTW_sentryModeState : 49|3@1+ (1,0) [0|0] "" Vector__XXX
 SG_ GTW_secureBootEnabled : 52|1@1+ (1,0) [0|0] "" Vector__XXX
 SG_ GTW_socSleepType : 56|2@1+ (1,0) [0|0] "" Vector__XXX
 SG_ GTW_resetType : 58|3@1+ (1,0) [0|0] "" Vector__XXX

BO_ 842 VCSEC_NFCDebug: 8 Vector__XXX
 SG_ VCSEC_NFCReaderIndexDebug M : 0|2@1+ (1,0) [0|0] "" Vector__XXX
 SG_ VCSEC_BPillarNFCCardCollisionL m0 : 3|1@1+ (1,0) [0|0] "" Vector__XXX
 SG_ VCSEC_BPillarNFCCardCollisionR m1 : 3|1@1+ (1,0) [0|0] "" Vector__XXX
 SG_ VCSEC_BPillarNFCPhaseL m3 : 3|8@1+ (1,0) [0|0] "" Vector__XXX
 SG_ VCSEC_CenterNFCCardCollision m2 : 3|1@1+ (1,0) [0|0] "" Vector__XXX
 SG_ VCSEC_BPillarNFCCardUIDSizeL m0 : 4|4@1+ (1,0) [0|0] "" Vector__XXX
 SG_ VCSEC_BPillarNFCCardUIDSizeR m1 : 4|4@1+ (1,0) [0|0] "" Vector__XXX
 SG_ VCSEC_CenterNFCCardUIDSize m2 : 4|4@1+ (1,0) [0|0] "" Vector__XXX
 SG_ VCSEC_BPillarNFCTrimSettingL m0 : 8|4@1+ (1,0) [0|0] "" Vector__XXX
 SG_ VCSEC_BPillarNFCTrimSettingR m1 : 8|4@1+ (1,0) [0|0] "" Vector__XXX
 SG_ VCSEC_CenterNFCTrimSetting m2 : 8|4@1+ (1,0) [0|0] "" Vector__XXX
 SG_ VCSEC_BPillarNFCPhaseR m3 : 11|8@1+ (1,0) [0|0] "" Vector__XXX
 SG_ VCSEC_BPillarNFCWakeUpCounterL m0 : 12|16@1+ (1,0) [0|0] "" Vector__XXX
 SG_ VCSEC_BPillarNFCWakeUpCounterR m1 : 12|16@1+ (1,0) [0|0] "" Vector__XXX
 SG_ VCSEC_CenterNFCCardATQa m2 : 12|16@1+ (1,0) [0|0] "" Vector__XXX
 SG_ VCSEC_CenterNFCPhase m3 : 19|8@1+ (1,0) [0|0] "" Vector__XXX
 SG_ VCSEC_BPillarNFCReaderStateL m0 : 28|2@1+ (1,0) [0|0] "" Vector__XXX
 SG_ VCSEC_BPillarNFCReaderStateR m1 : 28|2@1+ (1,0) [0|0] "" Vector__XXX
 SG_ VCSEC_CenterNFCReaderState m2 : 28|2@1+ (1,0) [0|0] "" Vector__XXX
 SG_ VCSEC_BPillarNFCAmplitudeL m0 : 36|8@1+ (1,0) [0|0] "" Vector__XXX
 SG_ VCSEC_BPillarNFCAmplitudeR m1 : 36|8@1+ (1,0) [0|0] "" Vector__XXX
 SG_ VCSEC_CenterNFCAmplitude m2 : 36|8@1+ (1,0) [0|0] "" Vector__XXX
 SG_ VCSEC_BPillarNFCDevLayerStateL m0 : 44|8@1+ (1,0) [0|0] "" Vector__XXX
 SG_ VCSEC_BPillarNFCDevLayerStateR m1 : 44|8@1+ (1,0) [0|0] "" Vector__XXX
 SG_ VCSEC_CenterNFCDevLayerState m2 : 44|8@1+ (1,0) [0|0] "" Vector__XXX
 SG_ VCSEC_BPillarNFCAntennaCalResultL m0 : 52|8@1+ (1,0) [0|0] "" Vector__XXX
 SG_ VCSEC_BPillarNFCAntennaCalResultR m1 : 52|8@1+ (1,0) [0|0] "" Vector__XXX
 SG_ VCSEC_CenterNFCAntennaCalResult m2 : 52|8@1+ (1,0) [0|0] "" Vector__XXX
 SG_ VCSEC_BPillarNFCStateReasonL m0 : 60|3@1+ (1,0) [0|0] "" Vector__XXX
 SG_ VCSEC_BPillarNFCStateReasonR m1 : 60|3@1+ (1,0) [0|0] "" Vector__XXX
 SG_ VCSEC_CenterNFCStateReason m2 : 60|4@1+ (1,0) [0|0] "" Vector__XXX

BO_ 850 BMS_energyStatus: 8 Vector__XXX
 SG_ BMS_energyStatusMultiplexer M : 0|2@1+ (1,0) [0|0] "" Vector__XXX
 SG_ BMS_energyRemainingDisplay m2 : 8|16@1+ (0.02,0) [0|0] "" Vector__XXX
 SG_ BMS_fullChargeComplete m1 : 15|1@1+ (1,0) [0|0] "" Vector__XXX
 SG_ BMS_energyBuffer m1 : 16|16@1+ (0.01,0) [0|0] "" Vector__XXX
 SG_ BMS_nominalFullPackEnergy m0 : 16|16@1+ (0.02,0) [0|0] "" Vector__XXX
 SG_ BMS_energyRemainingTDisplay m2 : 24|16@1+ (0.02,0) [0|0] "" Vector__XXX
 SG_ BMS_expectedEnergyRemaining m1 : 32|16@1+ (0.02,0) [0|0] "" Vector__XXX
 SG_ BMS_nominalEnergyRemaining m0 : 32|16@1+ (0.02,0) [0|0] "" Vector__XXX
 SG_ BMS_energyDisplayErrorBlendRate m2 : 40|12@1+ (0.01562881562881563,0) [0|0] "" Vector__XXX
 SG_ BMS_energyToChargeComplete m1 : 48|16@1+ (0.02,0) [0|0] "" Vector__XXX
 SG_ BMS_idealEnergyRemaining m0 : 48|16@1+ (0.02,0) [0|0] "" Vector__XXX
 SG_ BMS_userFacingSoe m2 : 52|11@1+ (0.05,0) [0|0] "" Vector__XXX

BO_ 851 UI_status: 8 Vector__XXX
 SG_ UI_touchActive : 0|1@1+ (1,0) [0|0] "" Vector__XXX
 SG_ UI_audioActive : 1|1@1+ (1,0) [0|0] "" Vector__XXX
 SG_ UI_bluetoothActive : 2|1@1+ (1,0) [0|0] "" Vector__XXX
 SG_ UI_cellActive : 3|1@1+ (1,0) [0|0] "" Vector__XXX
 SG_ UI_displayReady : 4|1@1+ (1,0) [0|0] "" Vector__XXX
 SG_ UI_displayOn : 5|1@1+ (1,0) [0|0] "" Vector__XXX
 SG_ UI_wifiActive : 6|1@1+ (1,0) [0|0] "" Vector__XXX
 SG_ UI_wifiConnected : 7|1@1+ (1,0) [0|0] "" Vector__XXX
 SG_ UI_systemActive : 8|1@1+ (1,0) [0|0] "" Vector__XXX
 SG_ UI_readyForDrive : 9|1@1+ (1,0) [0|0] "" Vector__XXX
 SG_ UI_cellConnected : 10|1@1+ (1,0) [0|0] "" Vector__XXX
 SG_ UI_vpnActive : 11|1@1+ (1,0) [0|0] "" Vector__XXX
 SG_ UI_autopilotTrial : 12|2@1+ (1,0) [0|0] "" Vector__XXX
 SG_ UI_factoryReset : 14|2@1+ (1,0) [0|0] "" Vector__XXX
 SG_ UI_gpsActive : 16|1@1+ (1,0) [0|0] "" Vector__XXX
 SG_ UI_screenshotActive : 17|1@1+ (1,0) [0|0] "" Vector__XXX
 SG_ UI_radioActive : 18|1@1+ (1,0) [0|0] "" Vector__XXX
 SG_ UI_cellNetworkTechnology : 19|4@1+ (1,0) [0|0] "" Vector__XXX
 SG_ UI_cellReceiverPower : 24|8@1+ (1,-128) [0|0] "" Vector__XXX
 SG_ UI_falseTouchCounter : 32|8@1+ (1,0) [0|0] "" Vector__XXX
 SG_ UI_developmentCar : 40|1@1+ (1,0) [0|0] "" Vector__XXX
 SG_ UI_cameraActive : 41|1@1+ (1,0) [0|0] "" Vector__XXX
 SG_ UI_cellSignalBars : 42|3@1+ (1,0) [0|0] "" Vector__XXX
 SG_ UI_trailerModeTelltale : 45|2@1+ (1,0) [0|0] "" Vector__XXX
 SG_ UI_pcbTemperature : 48|8@1- (1,40) [0|0] "" Vector__XXX
 SG_ UI_cpuTemperature : 56|8@1- (1,40) [0|0] "" Vector__XXX

BO_ 853 UI_vehicleControlThermal: 8 Vector__XXX
 SG_ UI_coolantFlowRequest : 0|5@1+ (1,0) [0|0] "" Vector__XXX
 SG_ UI_inletActiveCoolTarget : 5|7@1+ (1,0) [0|0] "" Vector__XXX
 SG_ UI_disableHVPTThermalLoads : 12|1@1+ (1,0) [0|0] "" Vector__XXX
 SG_ UI_enableCompLiquidPumpOut : 13|1@1+ (1,0) [0|0] "" Vector__XXX
 SG_ UI_enableCOP1HighSHOperation : 14|1@1+ (1,0) [0|0] "" Vector__XXX
 SG_ UI_enableIncreasedEvapRampRate : 15|1@1+ (1,0) [0|0] "" Vector__XXX
 SG_ UI_enableCOP1BatteryHeating : 16|1@1+ (1,0) [0|0] "" Vector__XXX
 SG_ UI_enableCOP1CabinHeatingBatteryHeating : 17|1@1+ (1,0) [0|0] "" Vector__XXX
 SG_ UI_enableLouverAutoDetection : 18|1@1+ (1,0) [0|0] "" Vector__XXX
 SG_ UI_enableUserFacingLowFlowDeliveryAlert : 19|1@1+ (1,0) [0|0] "" Vector__XXX
 SG_ UI_disableHvacCameraOnlyDefog : 20|1@1+ (1,0) [0|0] "" Vector__XXX
 SG_ UI_enableEXVFastCalibration : 21|1@1+ (1,0) [0|0] "" Vector__XXX
 SG_ UI_enableThermalDriverlessSelfTest : 22|1@1+ (1,0) [0|0] "" Vector__XXX
 SG_ UI_enableCoolantDasTarget : 23|1@1+ (1,0) [0|0] "" Vector__XXX
 SG_ UI_geofencedLiftgateHeight : 24|8@1+ (1,0) [0|0] "" Vector__XXX
 SG_ UI_convenienceFeatureLimit : 33|6@1+ (1,0) [0|0] "" Vector__XXX
 SG_ UI_allowConvenienceFeatures : 39|1@1+ (1,0) [0|0] "" Vector__XXX
 SG_ UI_enableConservativeBatteryHeating : 40|1@1+ (1,0) [0|0] "" Vector__XXX
 SG_ UI_enableDefaultApTempTarget : 41|1@1+ (1,0) [0|0] "" Vector__XXX
 SG_ UI_enableHVACCompressorWasteHeat : 42|1@1+ (1,0) [0|0] "" Vector__XXX
 SG_ UI_disablePhoneChargingPads : 43|1@1+ (1,0) [0|0] "" Vector__XXX
 SG_ UI_isAtTeslaFacility : 44|1@1+ (1,0) [0|0] "" Vector__XXX
 SG_ UI_enableThermalPowerBudget : 45|1@1+ (1,0) [0|0] "" Vector__XXX
 SG_ UI_enableAutopilotAirPurge : 47|1@1+ (1,0) [0|0] "" Vector__XXX

BO_ 854 DIF_alertMatrix1: 8 Vector__XXX
 SG_ DIF_a001_hwPhaseAgateDrive : 0|1@1+ (1,0) [0|0] "" Vector__XXX
 SG_ DIF_a002_hwPhaseBgateDrive : 1|1@1+ (1,0) [0|0] "" Vector__XXX
 SG_ DIF_a003_hwPhaseCgateDrive : 2|1@1+ (1,0) [0|0] "" Vector__XXX
 SG_ DIF_a004_hwPhaseApeak : 3|1@1+ (1,0) [0|0] "" Vector__XXX
 SG_ DIF_a005_hwPhaseBpeak : 4|1@1+ (1,0) [0|0] "" Vector__XXX
 SG_ DIF_a006_hwPhaseCpeak : 5|1@1+ (1,0) [0|0] "" Vector__XXX
 SG_ DIF_a007_statorAnomalyDetected : 6|1@1+ (1,0) [0|0] "" Vector__XXX
 SG_ DIF_a008_hwEncoderA : 7|1@1+ (1,0) [0|0] "" Vector__XXX
 SG_ DIF_a009_hwEncoderB : 8|1@1+ (1,0) [0|0] "" Vector__XXX
 SG_ DIF_a010_unintendedReset : 9|1@1+ (1,0) [0|0] "" Vector__XXX
 SG_ DIF_a011_swPowerStageNotReady : 10|1@1+ (1,0) [0|0] "" Vector__XXX
 SG_ DIF_a013_eccError : 12|1@1+ (1,0) [0|0] "" Vector__XXX
 SG_ DIF_a014_activeDamping : 13|1@1+ (1,0) [0|0] "" Vector__XXX
 SG_ DIF_a015_mechSafeStateAnomaly : 14|1@1+ (1,0) [0|0] "" Vector__XXX
 SG_ DIF_a016_safeStateApplied : 15|1@1+ (1,0) [0|0] "" Vector__XXX
 SG_ DIF_a017_hwPedalMonitor : 16|1@1+ (1,0) [0|0] "" Vector__XXX
 SG_ DIF_a018_hwLVSupplyUV : 17|1@1+ (1,0) [0|0] "" Vector__XXX
 SG_ DIF_a020_hwMotorEncoder : 19|1@1+ (1,0) [0|0] "" Vector__XXX
 SG_ DIF_a021_hwBusOV : 20|1@1+ (1,0) [0|0] "" Vector__XXX
 SG_ DIF_a022_hw5vSupplyUV : 21|1@1+ (1,0) [0|0] "" Vector__XXX
 SG_ DIF_a024_selfTest : 23|1@1+ (1,0) [0|0] "" Vector__XXX
 SG_ DIF_a025_phaseApeak : 24|1@1+ (1,0) [0|0] "" Vector__XXX
 SG_ DIF_a026_phaseBpeak : 25|1@1+ (1,0) [0|0] "" Vector__XXX
 SG_ DIF_a027_phaseCpeak : 26|1@1+ (1,0) [0|0] "" Vector__XXX
 SG_ DIF_a028_phaseArms : 27|1@1+ (1,0) [0|0] "" Vector__XXX
 SG_ DIF_a029_phaseBrms : 28|1@1+ (1,0) [0|0] "" Vector__XXX
 SG_ DIF_a030_phaseCrms : 29|1@1+ (1,0) [0|0] "" Vector__XXX
 SG_ DIF_a031_phaseAcurrentOffset : 30|1@1+ (1,0) [0|0] "" Vector__XXX
 SG_ DIF_a032_phaseBcurrentOffset : 31|1@1+ (1,0) [0|0] "" Vector__XXX
 SG_ DIF_a033_phaseAcurrentSensor : 32|1@1+ (1,0) [0|0] "" Vector__XXX
 SG_ DIF_a034_phaseBcurrentSensor : 33|1@1+ (1,0) [0|0] "" Vector__XXX
 SG_ DIF_a035_phaseCurrentBalance : 34|1@1+ (1,0) [0|0] "" Vector__XXX
 SG_ DIF_a036_busOV : 35|1@1+ (1,0) [0|0] "" Vector__XXX
 SG_ DIF_a037_busUV : 36|1@1+ (1,0) [0|0] "" Vector__XXX
 SG_ DIF_a038_busVsensor : 37|1@1+ (1,0) [0|0] "" Vector__XXX
 SG_ DIF_a040_difMIA : 39|1@1+ (1,0) [0|0] "" Vector__XXX
 SG_ DIF_a041_sdcMIA : 40|1@1+ (1,0) [0|0] "" Vector__XXX
 SG_ DIF_a042_inletSensor : 41|1@1+ (1,0) [0|0] "" Vector__XXX
 SG_ DIF_a043_outletOT : 42|1@1+ (1,0) [0|0] "" Vector__XXX
 SG_ DIF_a044_outletUT : 43|1@1+ (1,0) [0|0] "" Vector__XXX
 SG_ DIF_a045_outletSensor : 44|1@1+ (1,0) [0|0] "" Vector__XXX
 SG_ DIF_a046_statorOT : 45|1@1+ (1,0) [0|0] "" Vector__XXX
 SG_ DIF_a047_statorSensor1 : 46|1@1+ (1,0) [0|0] "" Vector__XXX
 SG_ DIF_a048_statorSensor2 : 47|1@1+ (1,0) [0|0] "" Vector__XXX
 SG_ DIF_a049_statorSensorDiff : 48|1@1+ (1,0) [0|0] "" Vector__XXX
 SG_ DIF_a050_noStatorSensor : 49|1@1+ (1,0) [0|0] "" Vector__XXX
 SG_ DIF_a052_dirMIA : 51|1@1+ (1,0) [0|0] "" Vector__XXX
 SG_ DIF_a053_unexpectedLatchState : 52|1@1+ (1,0) [0|0] "" Vector__XXX
 SG_ DIF_a054_driveInverterOT : 53|1@1+ (1,0) [0|0] "" Vector__XXX
 SG_ DIF_a055_trqCrossCheck : 54|1@1+ (1,0) [0|0] "" Vector__XXX
 SG_ DIF_a056_ambientOT : 55|1@1+ (1,0) [0|0] "" Vector__XXX
 SG_ DIF_a057_ambientUT : 56|1@1+ (1,0) [0|0] "" Vector__XXX
 SG_ DIF_a058_ambientSensor : 57|1@1+ (1,0) [0|0] "" Vector__XXX
 SG_ DIF_a059_heatsinkOT : 58|1@1+ (1,0) [0|0] "" Vector__XXX
 SG_ DIF_a060_heatsinkUT : 59|1@1+ (1,0) [0|0] "" Vector__XXX
 SG_ DIF_a061_heatsinkSensor : 60|1@1+ (1,0) [0|0] "" Vector__XXX
 SG_ DIF_a062_systemLimpMode : 61|1@1+ (1,0) [0|0] "" Vector__XXX
 SG_ DIF_a064_torqueIntervention : 63|1@1+ (1,0) [0|0] "" Vector__XXX

BO_ 855 DIF_alertMatrix2: 8 Vector__XXX
 SG_ DIF_a065_canHardwareBusB : 0|1@1+ (1,0) [0|0] "" Vector__XXX
 SG_ DIF_a066_canDataBusB : 1|1@1+ (1,0) [0|0] "" Vector__XXX
 SG_ DIF_a067_canOverrunBusB : 2|1@1+ (1,0) [0|0] "" Vector__XXX
 SG_ DIF_a069_rotorTempLimit : 4|1@1+ (1,0) [0|0] "" Vector__XXX
 SG_ DIF_a070_udsTransactionInitiated : 5|1@1+ (1,0) [0|0] "" Vector__XXX
 SG_ DIF_a071_busDisconnected : 6|1@1+ (1,0) [0|0] "" Vector__XXX
 SG_ DIF_a072_gateDriveFaultCounter : 7|1@1+ (1,0) [0|0] "" Vector__XXX
 SG_ DIF_a073_motorSpeed : 8|1@1+ (1,0) [0|0] "" Vector__XXX
 SG_ DIF_a074_motorEncoder : 9|1@1+ (1,0) [0|0] "" Vector__XXX
 SG_ DIF_a075_motorSpeedMismatch : 10|1@1+ (1,0) [0|0] "" Vector__XXX
 SG_ DIF_a076_lvSupplyOV : 11|1@1+ (1,0) [0|0] "" Vector__XXX
 SG_ DIF_a077_lvSupplyUV : 12|1@1+ (1,0) [0|0] "" Vector__XXX
 SG_ DIF_a078_adcRefLow : 13|1@1+ (1,0) [0|0] "" Vector__XXX
 SG_ DIF_a079_adcRefHigh : 14|1@1+ (1,0) [0|0] "" Vector__XXX
 SG_ DIF_a084_eccTestData0 : 19|1@1+ (1,0) [0|0] "" Vector__XXX
 SG_ DIF_a086_activeDischargeOn : 21|1@1+ (1,0) [0|0] "" Vector__XXX
 SG_ DIF_a087_gtwMIA : 22|1@1+ (1,0) [0|0] "" Vector__XXX
 SG_ DIF_a088_uiMIA : 23|1@1+ (1,0) [0|0] "" Vector__XXX
 SG_ DIF_a090_pmMIA : 25|1@1+ (1,0) [0|0] "" Vector__XXX
 SG_ DIF_a091_espMIA : 26|1@1+ (1,0) [0|0] "" Vector__XXX
 SG_ DIF_a092_bmsMIA : 27|1@1+ (1,0) [0|0] "" Vector__XXX
 SG_ DIF_a093_canHardwareBusA : 28|1@1+ (1,0) [0|0] "" Vector__XXX
 SG_ DIF_a094_canDataBusA : 29|1@1+ (1,0) [0|0] "" Vector__XXX
 SG_ DIF_a095_canOverrunBusA : 30|1@1+ (1,0) [0|0] "" Vector__XXX
 SG_ DIF_a096_memoryError : 31|1@1+ (1,0) [0|0] "" Vector__XXX
 SG_ DIF_a097_eepromError : 32|1@1+ (1,0) [0|0] "" Vector__XXX
 SG_ DIF_a098_intTimeTooLong : 33|1@1+ (1,0) [0|0] "" Vector__XXX
 SG_ DIF_a099_threadOverrun : 34|1@1+ (1,0) [0|0] "" Vector__XXX
 SG_ DIF_a100_assertion : 35|1@1+ (1,0) [0|0] "" Vector__XXX
 SG_ DIF_a101_eccTestData1 : 36|1@1+ (1,0) [0|0] "" Vector__XXX
 SG_ DIF_a103_lowFlow : 38|1@1+ (1,0) [0|0] "" Vector__XXX
 SG_ DIF_a107_fpgaError : 42|1@1+ (1,0) [0|0] "" Vector__XXX
 SG_ DIF_a108_stateTrans : 43|1@1+ (1,0) [0|0] "" Vector__XXX
 SG_ DIF_a110_brakeMIA : 45|1@1+ (1,0) [0|0] "" Vector__XXX
 SG_ DIF_a111_badPhaseSensorCalib : 46|1@1+ (1,0) [0|0] "" Vector__XXX
 SG_ DIF_a112_noPhaseCurrent : 47|1@1+ (1,0) [0|0] "" Vector__XXX
 SG_ DIF_a113_noFuncHeatsinkSensor : 48|1@1+ (1,0) [0|0] "" Vector__XXX
 SG_ DIF_a117_diMIA : 52|1@1+ (1,0) [0|0] "" Vector__XXX
 SG_ DIF_a119_hvpMIA : 54|1@1+ (1,0) [0|0] "" Vector__XXX
 SG_ DIF_a120_hvlinkMIA : 55|1@1+ (1,0) [0|0] "" Vector__XXX
 SG_ DIF_a121_motorControlRegulation : 56|1@1+ (1,0) [0|0] "" Vector__XXX
 SG_ DIF_a122_highStackUsage : 57|1@1+ (1,0) [0|0] "" Vector__XXX
 SG_ DIF_a123_lossMotorControl : 58|1@1+ (1,0) [0|0] "" Vector__XXX
 SG_ DIF_a126_limpMode : 61|1@1+ (1,0) [0|0] "" Vector__XXX
 SG_ DIF_a127_gracefulPowerOff : 62|1@1+ (1,0) [0|0] "" Vector__XXX
 SG_ DIF_a128_fpgaVersionMismatch : 63|1@1+ (1,0) [0|0] "" Vector__XXX

BO_ 857 VCSEC_DeviceStatus: 8 Vector__XXX
 SG_ VCSEC_DeviceStatusIndex M : 0|7@1+ (1,0) [0|0] "" Vector__XXX
 SG_ VCSEC_Device0AuthResponseTime m0 : 7|7@1+ (50,0) [0|0] "" Vector__XXX
 SG_ VCSEC_Device0AwakeTime m1 : 7|27@1+ (1,0) [0|0] "" Vector__XXX
 SG_ VCSEC_Device10AuthResponseTime m60 : 7|7@1+ (50,0) [0|0] "" Vector__XXX
 SG_ VCSEC_Device10AwakeTime m61 : 7|27@1+ (1,0) [0|0] "" Vector__XXX
 SG_ VCSEC_Device11AuthResponseTime m66 : 7|7@1+ (50,0) [0|0] "" Vector__XXX
 SG_ VCSEC_Device11AwakeTime m67 : 7|27@1+ (1,0) [0|0] "" Vector__XXX
 SG_ VCSEC_Device12AuthResponseTime m72 : 7|7@1+ (50,0) [0|0] "" Vector__XXX
 SG_ VCSEC_Device12AwakeTime m73 : 7|27@1+ (1,0) [0|0] "" Vector__XXX
 SG_ VCSEC_Device13AuthResponseTime m78 : 7|7@1+ (50,0) [0|0] "" Vector__XXX
 SG_ VCSEC_Device13AwakeTime m79 : 7|27@1+ (1,0) [0|0] "" Vector__XXX
 SG_ VCSEC_Device14AuthResponseTime m84 : 7|7@1+ (50,0) [0|0] "" Vector__XXX
 SG_ VCSEC_Device14AwakeTime m85 : 7|27@1+ (1,0) [0|0] "" Vector__XXX
 SG_ VCSEC_Device15AuthResponseTime m90 : 7|7@1+ (50,0) [0|0] "" Vector__XXX
 SG_ VCSEC_Device15AwakeTime m91 : 7|27@1+ (1,0) [0|0] "" Vector__XXX
 SG_ VCSEC_Device16AuthResponseTime m96 : 7|7@1+ (50,0) [0|0] "" Vector__XXX
 SG_ VCSEC_Device16AwakeTime m97 : 7|27@1+ (1,0) [0|0] "" Vector__XXX
 SG_ VCSEC_Device17AuthResponseTime m102 : 7|7@1+ (50,0) [0|0] "" Vector__XXX
 SG_ VCSEC_Device17AwakeTime m103 : 7|27@1+ (1,0) [0|0] "" Vector__XXX
 SG_ VCSEC_Device18AuthResponseTime m108 : 7|7@1+ (50,0) [0|0] "" Vector__XXX
 SG_ VCSEC_Device18AwakeTime m109 : 7|27@1+ (1,0) [0|0] "" Vector__XXX
 SG_ VCSEC_Device19AuthResponseTime m114 : 7|7@1+ (50,0) [0|0] "" Vector__XXX
 SG_ VCSEC_Device19AwakeTime m115 : 7|27@1+ (1,0) [0|0] "" Vector__XXX
 SG_ VCSEC_Device1AuthResponseTime m6 : 7|7@1+ (50,0) [0|0] "" Vector__XXX
 SG_ VCSEC_Device1AwakeTime m7 : 7|27@1+ (1,0) [0|0] "" Vector__XXX
 SG_ VCSEC_Device2AuthResponseTime m12 : 7|7@1+ (50,0) [0|0] "" Vector__XXX
 SG_ VCSEC_Device2AwakeTime m13 : 7|27@1+ (1,0) [0|0] "" Vector__XXX
 SG_ VCSEC_Device3AuthResponseTime m18 : 7|7@1+ (50,0) [0|0] "" Vector__XXX
 SG_ VCSEC_Device3AwakeTime m19 : 7|27@1+ (1,0) [0|0] "" Vector__XXX
 SG_ VCSEC_Device4AuthResponseTime m24 : 7|7@1+ (50,0) [0|0] "" Vector__XXX
 SG_ VCSEC_Device4AwakeTime m25 : 7|27@1+ (1,0) [0|0] "" Vector__XXX
 SG_ VCSEC_Device5AuthResponseTime m30 : 7|7@1+ (50,0) [0|0] "" Vector__XXX
 SG_ VCSEC_Device5AwakeTime m31 : 7|27@1+ (1,0) [0|0] "" Vector__XXX
 SG_ VCSEC_Device6AuthResponseTime m36 : 7|7@1+ (50,0) [0|0] "" Vector__XXX
 SG_ VCSEC_Device6AwakeTime m37 : 7|27@1+ (1,0) [0|0] "" Vector__XXX
 SG_ VCSEC_Device7AuthResponseTime m42 : 7|7@1+ (50,0) [0|0] "" Vector__XXX
 SG_ VCSEC_Device7AwakeTime m43 : 7|27@1+ (1,0) [0|0] "" Vector__XXX
 SG_ VCSEC_Device8AuthResponseTime m48 : 7|7@1+ (50,0) [0|0] "" Vector__XXX
 SG_ VCSEC_Device8AwakeTime m49 : 7|27@1+ (1,0) [0|0] "" Vector__XXX
 SG_ VCSEC_Device9AuthResponseTime m54 : 7|7@1+ (50,0) [0|0] "" Vector__XXX
 SG_ VCSEC_Device9AwakeTime m55 : 7|27@1+ (1,0) [0|0] "" Vector__XXX
 SG_ VCSEC_Device0Bonded m2 : 8|1@1+ (1,0) [0|0] "" Vector__XXX
 SG_ VCSEC_Device0ManufacturerHashBits m5 : 8|24@1+ (1,0) [0|0] "" Vector__XXX
 SG_ VCSEC_Device0ModelHash m4 : 8|56@1+ (1,0) [0|0] "" Vector__XXX
 SG_ VCSEC_Device10Bonded m62 : 8|1@1+ (1,0) [0|0] "" Vector__XXX
 SG_ VCSEC_Device10ManufacturerHashBits m65 : 8|24@1+ (1,0) [0|0] "" Vector__XXX
 SG_ VCSEC_Device10ModelHash m64 : 8|56@1+ (1,0) [0|0] "" Vector__XXX
 SG_ VCSEC_Device11Bonded m68 : 8|1@1+ (1,0) [0|0] "" Vector__XXX
 SG_ VCSEC_Device11ManufacturerHashBits m71 : 8|24@1+ (1,0) [0|0] "" Vector__XXX
 SG_ VCSEC_Device11ModelHash m70 : 8|56@1+ (1,0) [0|0] "" Vector__XXX
 SG_ VCSEC_Device12Bonded m74 : 8|1@1+ (1,0) [0|0] "" Vector__XXX
 SG_ VCSEC_Device12ManufacturerHashBits m77 : 8|24@1+ (1,0) [0|0] "" Vector__XXX
 SG_ VCSEC_Device12ModelHash m76 : 8|56@1+ (1,0) [0|0] "" Vector__XXX
 SG_ VCSEC_Device13Bonded m80 : 8|1@1+ (1,0) [0|0] "" Vector__XXX
 SG_ VCSEC_Device13ManufacturerHashBits m83 : 8|24@1+ (1,0) [0|0] "" Vector__XXX
 SG_ VCSEC_Device13ModelHash m82 : 8|56@1+ (1,0) [0|0] "" Vector__XXX
 SG_ VCSEC_Device14Bonded m86 : 8|1@1+ (1,0) [0|0] "" Vector__XXX
 SG_ VCSEC_Device14ManufacturerHashBits m89 : 8|24@1+ (1,0) [0|0] "" Vector__XXX
 SG_ VCSEC_Device14ModelHash m88 : 8|56@1+ (1,0) [0|0] "" Vector__XXX
 SG_ VCSEC_Device15Bonded m92 : 8|1@1+ (1,0) [0|0] "" Vector__XXX
 SG_ VCSEC_Device15ManufacturerHashBits m95 : 8|24@1+ (1,0) [0|0] "" Vector__XXX
 SG_ VCSEC_Device15ModelHash m94 : 8|56@1+ (1,0) [0|0] "" Vector__XXX
 SG_ VCSEC_Device16Bonded m98 : 8|1@1+ (1,0) [0|0] "" Vector__XXX
 SG_ VCSEC_Device16ManufacturerHashBits m101 : 8|24@1+ (1,0) [0|0] "" Vector__XXX
 SG_ VCSEC_Device16ModelHash m100 : 8|56@1+ (1,0) [0|0] "" Vector__XXX
 SG_ VCSEC_Device17Bonded m104 : 8|1@1+ (1,0) [0|0] "" Vector__XXX
 SG_ VCSEC_Device17ManufacturerHashBits m107 : 8|24@1+ (1,0) [0|0] "" Vector__XXX
 SG_ VCSEC_Device17ModelHash m106 : 8|56@1+ (1,0) [0|0] "" Vector__XXX
 SG_ VCSEC_Device18Bonded m110 : 8|1@1+ (1,0) [0|0] "" Vector__XXX
 SG_ VCSEC_Device18ManufacturerHashBits m113 : 8|24@1+ (1,0) [0|0] "" Vector__XXX
 SG_ VCSEC_Device18ModelHash m112 : 8|56@1+ (1,0) [0|0] "" Vector__XXX
 SG_ VCSEC_Device19Bonded m116 : 8|1@1+ (1,0) [0|0] "" Vector__XXX
 SG_ VCSEC_Device19ManufacturerHashBits m119 : 8|24@1+ (1,0) [0|0] "" Vector__XXX
 SG_ VCSEC_Device19ModelHash m118 : 8|56@1+ (1,0) [0|0] "" Vector__XXX
 SG_ VCSEC_Device1Bonded m8 : 8|1@1+ (1,0) [0|0] "" Vector__XXX
 SG_ VCSEC_Device1ManufacturerHashBits m11 : 8|24@1+ (1,0) [0|0] "" Vector__XXX
 SG_ VCSEC_Device1ModelHash m10 : 8|56@1+ (1,0) [0|0] "" Vector__XXX
 SG_ VCSEC_Device2Bonded m14 : 8|1@1+ (1,0) [0|0] "" Vector__XXX
 SG_ VCSEC_Device2ManufacturerHashBits m17 : 8|24@1+ (1,0) [0|0] "" Vector__XXX
 SG_ VCSEC_Device2ModelHash m16 : 8|56@1+ (1,0) [0|0] "" Vector__XXX
 SG_ VCSEC_Device3Bonded m20 : 8|1@1+ (1,0) [0|0] "" Vector__XXX
 SG_ VCSEC_Device3ManufacturerHashBits m23 : 8|24@1+ (1,0) [0|0] "" Vector__XXX
 SG_ VCSEC_Device3ModelHash m22 : 8|56@1+ (1,0) [0|0] "" Vector__XXX
 SG_ VCSEC_Device4Bonded m26 : 8|1@1+ (1,0) [0|0] "" Vector__XXX
 SG_ VCSEC_Device4ManufacturerHashBits m29 : 8|24@1+ (1,0) [0|0] "" Vector__XXX
 SG_ VCSEC_Device4ModelHash m28 : 8|56@1+ (1,0) [0|0] "" Vector__XXX
 SG_ VCSEC_Device5Bonded m32 : 8|1@1+ (1,0) [0|0] "" Vector__XXX
 SG_ VCSEC_Device5ManufacturerHashBits m35 : 8|24@1+ (1,0) [0|0] "" Vector__XXX
 SG_ VCSEC_Device5ModelHash m34 : 8|56@1+ (1,0) [0|0] "" Vector__XXX
 SG_ VCSEC_Device6Bonded m38 : 8|1@1+ (1,0) [0|0] "" Vector__XXX
 SG_ VCSEC_Device6ManufacturerHashBits m41 : 8|24@1+ (1,0) [0|0] "" Vector__XXX
 SG_ VCSEC_Device6ModelHash m40 : 8|56@1+ (1,0) [0|0] "" Vector__XXX
 SG_ VCSEC_Device7Bonded m44 : 8|1@1+ (1,0) [0|0] "" Vector__XXX
 SG_ VCSEC_Device7ManufacturerHashBits m47 : 8|24@1+ (1,0) [0|0] "" Vector__XXX
 SG_ VCSEC_Device7ModelHash m46 : 8|56@1+ (1,0) [0|0] "" Vector__XXX
 SG_ VCSEC_Device8Bonded m50 : 8|1@1+ (1,0) [0|0] "" Vector__XXX
 SG_ VCSEC_Device8ManufacturerHashBits m53 : 8|24@1+ (1,0) [0|0] "" Vector__XXX
 SG_ VCSEC_Device8ModelHash m52 : 8|56@1+ (1,0) [0|0] "" Vector__XXX
 SG_ VCSEC_Device9Bonded m56 : 8|1@1+ (1,0) [0|0] "" Vector__XXX
 SG_ VCSEC_Device9ManufacturerHashBits m59 : 8|24@1+ (1,0) [0|0] "" Vector__XXX
 SG_ VCSEC_Device9ModelHash m58 : 8|56@1+ (1,0) [0|0] "" Vector__XXX
 SG_ VCSEC_Device0Role m2 : 9|4@1+ (1,0) [0|0] "" Vector__XXX
 SG_ VCSEC_Device10Role m62 : 9|4@1+ (1,0) [0|0] "" Vector__XXX
 SG_ VCSEC_Device11Role m68 : 9|4@1+ (1,0) [0|0] "" Vector__XXX
 SG_ VCSEC_Device12Role m74 : 9|4@1+ (1,0) [0|0] "" Vector__XXX
 SG_ VCSEC_Device13Role m80 : 9|4@1+ (1,0) [0|0] "" Vector__XXX
 SG_ VCSEC_Device14Role m86 : 9|4@1+ (1,0) [0|0] "" Vector__XXX
 SG_ VCSEC_Device15Role m92 : 9|4@1+ (1,0) [0|0] "" Vector__XXX
 SG_ VCSEC_Device16Role m98 : 9|4@1+ (1,0) [0|0] "" Vector__XXX
 SG_ VCSEC_Device17Role m104 : 9|4@1+ (1,0) [0|0] "" Vector__XXX
 SG_ VCSEC_Device18Role m110 : 9|4@1+ (1,0) [0|0] "" Vector__XXX
 SG_ VCSEC_Device19Role m116 : 9|4@1+ (1,0) [0|0] "" Vector__XXX
 SG_ VCSEC_Device1Role m8 : 9|4@1+ (1,0) [0|0] "" Vector__XXX
 SG_ VCSEC_Device2Role m14 : 9|4@1+ (1,0) [0|0] "" Vector__XXX
 SG_ VCSEC_Device3Role m20 : 9|4@1+ (1,0) [0|0] "" Vector__XXX
 SG_ VCSEC_Device4Role m26 : 9|4@1+ (1,0) [0|0] "" Vector__XXX
 SG_ VCSEC_Device5Role m32 : 9|4@1+ (1,0) [0|0] "" Vector__XXX
 SG_ VCSEC_Device6Role m38 : 9|4@1+ (1,0) [0|0] "" Vector__XXX
 SG_ VCSEC_Device7Role m44 : 9|4@1+ (1,0) [0|0] "" Vector__XXX
 SG_ VCSEC_Device8Role m50 : 9|4@1+ (1,0) [0|0] "" Vector__XXX
 SG_ VCSEC_Device9Role m56 : 9|4@1+ (1,0) [0|0] "" Vector__XXX
 SG_ VCSEC_Device0Impermanent m0 : 14|1@1+ (1,0) [0|0] "" Vector__XXX
 SG_ VCSEC_Device10Impermanent m60 : 14|1@1+ (1,0) [0|0] "" Vector__XXX
 SG_ VCSEC_Device11Impermanent m66 : 14|1@1+ (1,0) [0|0] "" Vector__XXX
 SG_ VCSEC_Device12Impermanent m72 : 14|1@1+ (1,0) [0|0] "" Vector__XXX
 SG_ VCSEC_Device13Impermanent m78 : 14|1@1+ (1,0) [0|0] "" Vector__XXX
 SG_ VCSEC_Device14Impermanent m84 : 14|1@1+ (1,0) [0|0] "" Vector__XXX
 SG_ VCSEC_Device15Impermanent m90 : 14|1@1+ (1,0) [0|0] "" Vector__XXX
 SG_ VCSEC_Device16Impermanent m96 : 14|1@1+ (1,0) [0|0] "" Vector__XXX
 SG_ VCSEC_Device17Impermanent m102 : 14|1@1+ (1,0) [0|0] "" Vector__XXX
 SG_ VCSEC_Device18Impermanent m108 : 14|1@1+ (1,0) [0|0] "" Vector__XXX
 SG_ VCSEC_Device19Impermanent m114 : 14|1@1+ (1,0) [0|0] "" Vector__XXX
 SG_ VCSEC_Device1Impermanent m6 : 14|1@1+ (1,0) [0|0] "" Vector__XXX
 SG_ VCSEC_Device2Impermanent m12 : 14|1@1+ (1,0) [0|0] "" Vector__XXX
 SG_ VCSEC_Device3Impermanent m18 : 14|1@1+ (1,0) [0|0] "" Vector__XXX
 SG_ VCSEC_Device4Impermanent m24 : 14|1@1+ (1,0) [0|0] "" Vector__XXX
 SG_ VCSEC_Device5Impermanent m30 : 14|1@1+ (1,0) [0|0] "" Vector__XXX
 SG_ VCSEC_Device6Impermanent m36 : 14|1@1+ (1,0) [0|0] "" Vector__XXX
 SG_ VCSEC_Device7Impermanent m42 : 14|1@1+ (1,0) [0|0] "" Vector__XXX
 SG_ VCSEC_Device8Impermanent m48 : 14|1@1+ (1,0) [0|0] "" Vector__XXX
 SG_ VCSEC_Device9Impermanent m54 : 14|1@1+ (1,0) [0|0] "" Vector__XXX
 SG_ VCSEC_Device0SELockedDown m0 : 15|1@1+ (1,0) [0|0] "" Vector__XXX
 SG_ VCSEC_Device10SELockedDown m60 : 15|1@1+ (1,0) [0|0] "" Vector__XXX
 SG_ VCSEC_Device11SELockedDown m66 : 15|1@1+ (1,0) [0|0] "" Vector__XXX
 SG_ VCSEC_Device12SELockedDown m72 : 15|1@1+ (1,0) [0|0] "" Vector__XXX
 SG_ VCSEC_Device13SELockedDown m78 : 15|1@1+ (1,0) [0|0] "" Vector__XXX
 SG_ VCSEC_Device14SELockedDown m84 : 15|1@1+ (1,0) [0|0] "" Vector__XXX
 SG_ VCSEC_Device15SELockedDown m90 : 15|1@1+ (1,0) [0|0] "" Vector__XXX
 SG_ VCSEC_Device16SELockedDown m96 : 15|1@1+ (1,0) [0|0] "" Vector__XXX
 SG_ VCSEC_Device17SELockedDown m102 : 15|1@1+ (1,0) [0|0] "" Vector__XXX
 SG_ VCSEC_Device18SELockedDown m108 : 15|1@1+ (1,0) [0|0] "" Vector__XXX
 SG_ VCSEC_Device19SELockedDown m114 : 15|1@1+ (1,0) [0|0] "" Vector__XXX
 SG_ VCSEC_Device1SELockedDown m6 : 15|1@1+ (1,0) [0|0] "" Vector__XXX
 SG_ VCSEC_Device2SELockedDown m12 : 15|1@1+ (1,0) [0|0] "" Vector__XXX
 SG_ VCSEC_Device3SELockedDown m18 : 15|1@1+ (1,0) [0|0] "" Vector__XXX
 SG_ VCSEC_Device4SELockedDown m24 : 15|1@1+ (1,0) [0|0] "" Vector__XXX
 SG_ VCSEC_Device5SELockedDown m30 : 15|1@1+ (1,0) [0|0] "" Vector__XXX
 SG_ VCSEC_Device6SELockedDown m36 : 15|1@1+ (1,0) [0|0] "" Vector__XXX
 SG_ VCSEC_Device7SELockedDown m42 : 15|1@1+ (1,0) [0|0] "" Vector__XXX
 SG_ VCSEC_Device8SELockedDown m48 : 15|1@1+ (1,0) [0|0] "" Vector__XXX
 SG_ VCSEC_Device9SELockedDown m54 : 15|1@1+ (1,0) [0|0] "" Vector__XXX
 SG_ VCSEC_Device0Version m0 : 16|16@1+ (1,0) [0|0] "" Vector__XXX
 SG_ VCSEC_Device0WhitelistActiveTime m2 : 16|16@1+ (1,0) [0|0] "" Vector__XXX
 SG_ VCSEC_Device10Version m60 : 16|16@1+ (1,0) [0|0] "" Vector__XXX
 SG_ VCSEC_Device10WhitelistActiveTime m62 : 16|16@1+ (1,0) [0|0] "" Vector__XXX
 SG_ VCSEC_Device11Version m66 : 16|16@1+ (1,0) [0|0] "" Vector__XXX
 SG_ VCSEC_Device11WhitelistActiveTime m68 : 16|16@1+ (1,0) [0|0] "" Vector__XXX
 SG_ VCSEC_Device12Version m72 : 16|16@1+ (1,0) [0|0] "" Vector__XXX
 SG_ VCSEC_Device12WhitelistActiveTime m74 : 16|16@1+ (1,0) [0|0] "" Vector__XXX
 SG_ VCSEC_Device13Version m78 : 16|16@1+ (1,0) [0|0] "" Vector__XXX
 SG_ VCSEC_Device13WhitelistActiveTime m80 : 16|16@1+ (1,0) [0|0] "" Vector__XXX
 SG_ VCSEC_Device14Version m84 : 16|16@1+ (1,0) [0|0] "" Vector__XXX
 SG_ VCSEC_Device14WhitelistActiveTime m86 : 16|16@1+ (1,0) [0|0] "" Vector__XXX
 SG_ VCSEC_Device15Version m90 : 16|16@1+ (1,0) [0|0] "" Vector__XXX
 SG_ VCSEC_Device15WhitelistActiveTime m92 : 16|16@1+ (1,0) [0|0] "" Vector__XXX
 SG_ VCSEC_Device16Version m96 : 16|16@1+ (1,0) [0|0] "" Vector__XXX
 SG_ VCSEC_Device16WhitelistActiveTime m98 : 16|16@1+ (1,0) [0|0] "" Vector__XXX
 SG_ VCSEC_Device17Version m102 : 16|16@1+ (1,0) [0|0] "" Vector__XXX
 SG_ VCSEC_Device17WhitelistActiveTime m104 : 16|16@1+ (1,0) [0|0] "" Vector__XXX
 SG_ VCSEC_Device18Version m108 : 16|16@1+ (1,0) [0|0] "" Vector__XXX
 SG_ VCSEC_Device18WhitelistActiveTime m110 : 16|16@1+ (1,0) [0|0] "" Vector__XXX
 SG_ VCSEC_Device19Version m114 : 16|16@1+ (1,0) [0|0] "" Vector__XXX
 SG_ VCSEC_Device19WhitelistActiveTime m116 : 16|16@1+ (1,0) [0|0] "" Vector__XXX
 SG_ VCSEC_Device1Version m6 : 16|16@1+ (1,0) [0|0] "" Vector__XXX
 SG_ VCSEC_Device1WhitelistActiveTime m8 : 16|16@1+ (1,0) [0|0] "" Vector__XXX
 SG_ VCSEC_Device2Version m12 : 16|16@1+ (1,0) [0|0] "" Vector__XXX
 SG_ VCSEC_Device2WhitelistActiveTime m14 : 16|16@1+ (1,0) [0|0] "" Vector__XXX
 SG_ VCSEC_Device3Version m18 : 16|16@1+ (1,0) [0|0] "" Vector__XXX
 SG_ VCSEC_Device3WhitelistActiveTime m20 : 16|16@1+ (1,0) [0|0] "" Vector__XXX
 SG_ VCSEC_Device4Version m24 : 16|16@1+ (1,0) [0|0] "" Vector__XXX
 SG_ VCSEC_Device4WhitelistActiveTime m26 : 16|16@1+ (1,0) [0|0] "" Vector__XXX
 SG_ VCSEC_Device5Version m30 : 16|16@1+ (1,0) [0|0] "" Vector__XXX
 SG_ VCSEC_Device5WhitelistActiveTime m32 : 16|16@1+ (1,0) [0|0] "" Vector__XXX
 SG_ VCSEC_Device6Version m36 : 16|16@1+ (1,0) [0|0] "" Vector__XXX
 SG_ VCSEC_Device6WhitelistActiveTime m38 : 16|16@1+ (1,0) [0|0] "" Vector__XXX
 SG_ VCSEC_Device7Version m42 : 16|16@1+ (1,0) [0|0] "" Vector__XXX
 SG_ VCSEC_Device7WhitelistActiveTime m44 : 16|16@1+ (1,0) [0|0] "" Vector__XXX
 SG_ VCSEC_Device8Version m48 : 16|16@1+ (1,0) [0|0] "" Vector__XXX
 SG_ VCSEC_Device8WhitelistActiveTime m50 : 16|16@1+ (1,0) [0|0] "" Vector__XXX
 SG_ VCSEC_Device9Version m54 : 16|16@1+ (1,0) [0|0] "" Vector__XXX
 SG_ VCSEC_Device9WhitelistActiveTime m56 : 16|16@1+ (1,0) [0|0] "" Vector__XXX
 SG_ VCSEC_Device0BuildNumberHashBits m5 : 32|32@1+ (1,0) [0|0] "" Vector__XXX
 SG_ VCSEC_Device0Permissions m3 : 32|32@1+ (1,0) [0|0] "" Vector__XXX
 SG_ VCSEC_Device0SHA1 m2 : 32|32@1+ (1,0) [0|0] "" Vector__XXX
 SG_ VCSEC_Device0WLEntry m0 : 32|5@1+ (1,0) [0|0] "" Vector__XXX
 SG_ VCSEC_Device10BuildNumberHashBits m65 : 32|32@1+ (1,0) [0|0] "" Vector__XXX
 SG_ VCSEC_Device10Permissions m63 : 32|32@1+ (1,0) [0|0] "" Vector__XXX
 SG_ VCSEC_Device10SHA1 m62 : 32|32@1+ (1,0) [0|0] "" Vector__XXX
 SG_ VCSEC_Device10WLEntry m60 : 32|5@1+ (1,0) [0|0] "" Vector__XXX
 SG_ VCSEC_Device11BuildNumberHashBits m71 : 32|32@1+ (1,0) [0|0] "" Vector__XXX
 SG_ VCSEC_Device11Permissions m69 : 32|32@1+ (1,0) [0|0] "" Vector__XXX
 SG_ VCSEC_Device11SHA1 m68 : 32|32@1+ (1,0) [0|0] "" Vector__XXX
 SG_ VCSEC_Device11WLEntry m66 : 32|5@1+ (1,0) [0|0] "" Vector__XXX
 SG_ VCSEC_Device12BuildNumberHashBits m77 : 32|32@1+ (1,0) [0|0] "" Vector__XXX
 SG_ VCSEC_Device12Permissions m75 : 32|32@1+ (1,0) [0|0] "" Vector__XXX
 SG_ VCSEC_Device12SHA1 m74 : 32|32@1+ (1,0) [0|0] "" Vector__XXX
 SG_ VCSEC_Device12WLEntry m72 : 32|5@1+ (1,0) [0|0] "" Vector__XXX
 SG_ VCSEC_Device13BuildNumberHashBits m83 : 32|32@1+ (1,0) [0|0] "" Vector__XXX
 SG_ VCSEC_Device13Permissions m81 : 32|32@1+ (1,0) [0|0] "" Vector__XXX
 SG_ VCSEC_Device13SHA1 m80 : 32|32@1+ (1,0) [0|0] "" Vector__XXX
 SG_ VCSEC_Device13WLEntry m78 : 32|5@1+ (1,0) [0|0] "" Vector__XXX
 SG_ VCSEC_Device14BuildNumberHashBits m89 : 32|32@1+ (1,0) [0|0] "" Vector__XXX
 SG_ VCSEC_Device14Permissions m87 : 32|32@1+ (1,0) [0|0] "" Vector__XXX
 SG_ VCSEC_Device14SHA1 m86 : 32|32@1+ (1,0) [0|0] "" Vector__XXX
 SG_ VCSEC_Device14WLEntry m84 : 32|5@1+ (1,0) [0|0] "" Vector__XXX
 SG_ VCSEC_Device15BuildNumberHashBits m95 : 32|32@1+ (1,0) [0|0] "" Vector__XXX
 SG_ VCSEC_Device15Permissions m93 : 32|32@1+ (1,0) [0|0] "" Vector__XXX
 SG_ VCSEC_Device15SHA1 m92 : 32|32@1+ (1,0) [0|0] "" Vector__XXX
 SG_ VCSEC_Device15WLEntry m90 : 32|5@1+ (1,0) [0|0] "" Vector__XXX
 SG_ VCSEC_Device16BuildNumberHashBits m101 : 32|32@1+ (1,0) [0|0] "" Vector__XXX
 SG_ VCSEC_Device16Permissions m99 : 32|32@1+ (1,0) [0|0] "" Vector__XXX
 SG_ VCSEC_Device16SHA1 m98 : 32|32@1+ (1,0) [0|0] "" Vector__XXX
 SG_ VCSEC_Device16WLEntry m96 : 32|5@1+ (1,0) [0|0] "" Vector__XXX
 SG_ VCSEC_Device17BuildNumberHashBits m107 : 32|32@1+ (1,0) [0|0] "" Vector__XXX
 SG_ VCSEC_Device17Permissions m105 : 32|32@1+ (1,0) [0|0] "" Vector__XXX
 SG_ VCSEC_Device17SHA1 m104 : 32|32@1+ (1,0) [0|0] "" Vector__XXX
 SG_ VCSEC_Device17WLEntry m102 : 32|5@1+ (1,0) [0|0] "" Vector__XXX
 SG_ VCSEC_Device18BuildNumberHashBits m113 : 32|32@1+ (1,0) [0|0] "" Vector__XXX
 SG_ VCSEC_Device18Permissions m111 : 32|32@1+ (1,0) [0|0] "" Vector__XXX
 SG_ VCSEC_Device18SHA1 m110 : 32|32@1+ (1,0) [0|0] "" Vector__XXX
 SG_ VCSEC_Device18WLEntry m108 : 32|5@1+ (1,0) [0|0] "" Vector__XXX
 SG_ VCSEC_Device19BuildNumberHashBits m119 : 32|32@1+ (1,0) [0|0] "" Vector__XXX
 SG_ VCSEC_Device19Permissions m117 : 32|32@1+ (1,0) [0|0] "" Vector__XXX
 SG_ VCSEC_Device19SHA1 m116 : 32|32@1+ (1,0) [0|0] "" Vector__XXX
 SG_ VCSEC_Device19WLEntry m114 : 32|5@1+ (1,0) [0|0] "" Vector__XXX
 SG_ VCSEC_Device1BuildNumberHashBits m11 : 32|32@1+ (1,0) [0|0] "" Vector__XXX
 SG_ VCSEC_Device1Permissions m9 : 32|32@1+ (1,0) [0|0] "" Vector__XXX
 SG_ VCSEC_Device1SHA1 m8 : 32|32@1+ (1,0) [0|0] "" Vector__XXX
 SG_ VCSEC_Device1WLEntry m6 : 32|5@1+ (1,0) [0|0] "" Vector__XXX
 SG_ VCSEC_Device2BuildNumberHashBits m17 : 32|32@1+ (1,0) [0|0] "" Vector__XXX
 SG_ VCSEC_Device2Permissions m15 : 32|32@1+ (1,0) [0|0] "" Vector__XXX
 SG_ VCSEC_Device2SHA1 m14 : 32|32@1+ (1,0) [0|0] "" Vector__XXX
 SG_ VCSEC_Device2WLEntry m12 : 32|5@1+ (1,0) [0|0] "" Vector__XXX
 SG_ VCSEC_Device3BuildNumberHashBits m23 : 32|32@1+ (1,0) [0|0] "" Vector__XXX
 SG_ VCSEC_Device3Permissions m21 : 32|32@1+ (1,0) [0|0] "" Vector__XXX
 SG_ VCSEC_Device3SHA1 m20 : 32|32@1+ (1,0) [0|0] "" Vector__XXX
 SG_ VCSEC_Device3WLEntry m18 : 32|5@1+ (1,0) [0|0] "" Vector__XXX
 SG_ VCSEC_Device4BuildNumberHashBits m29 : 32|32@1+ (1,0) [0|0] "" Vector__XXX
 SG_ VCSEC_Device4Permissions m27 : 32|32@1+ (1,0) [0|0] "" Vector__XXX
 SG_ VCSEC_Device4SHA1 m26 : 32|32@1+ (1,0) [0|0] "" Vector__XXX
 SG_ VCSEC_Device4WLEntry m24 : 32|5@1+ (1,0) [0|0] "" Vector__XXX
 SG_ VCSEC_Device5BuildNumberHashBits m35 : 32|32@1+ (1,0) [0|0] "" Vector__XXX
 SG_ VCSEC_Device5Permissions m33 : 32|32@1+ (1,0) [0|0] "" Vector__XXX
 SG_ VCSEC_Device5SHA1 m32 : 32|32@1+ (1,0) [0|0] "" Vector__XXX
 SG_ VCSEC_Device5WLEntry m30 : 32|5@1+ (1,0) [0|0] "" Vector__XXX
 SG_ VCSEC_Device6BuildNumberHashBits m41 : 32|32@1+ (1,0) [0|0] "" Vector__XXX
 SG_ VCSEC_Device6Permissions m39 : 32|32@1+ (1,0) [0|0] "" Vector__XXX
 SG_ VCSEC_Device6SHA1 m38 : 32|32@1+ (1,0) [0|0] "" Vector__XXX
 SG_ VCSEC_Device6WLEntry m36 : 32|5@1+ (1,0) [0|0] "" Vector__XXX
 SG_ VCSEC_Device7BuildNumberHashBits m47 : 32|32@1+ (1,0) [0|0] "" Vector__XXX
 SG_ VCSEC_Device7Permissions m45 : 32|32@1+ (1,0) [0|0] "" Vector__XXX
 SG_ VCSEC_Device7SHA1 m44 : 32|32@1+ (1,0) [0|0] "" Vector__XXX
 SG_ VCSEC_Device7WLEntry m42 : 32|5@1+ (1,0) [0|0] "" Vector__XXX
 SG_ VCSEC_Device8BuildNumberHashBits m53 : 32|32@1+ (1,0) [0|0] "" Vector__XXX
 SG_ VCSEC_Device8Permissions m51 : 32|32@1+ (1,0) [0|0] "" Vector__XXX
 SG_ VCSEC_Device8SHA1 m50 : 32|32@1+ (1,0) [0|0] "" Vector__XXX
 SG_ VCSEC_Device8WLEntry m48 : 32|5@1+ (1,0) [0|0] "" Vector__XXX
 SG_ VCSEC_Device9BuildNumberHashBits m59 : 32|32@1+ (1,0) [0|0] "" Vector__XXX
 SG_ VCSEC_Device9Permissions m57 : 32|32@1+ (1,0) [0|0] "" Vector__XXX
 SG_ VCSEC_Device9SHA1 m56 : 32|32@1+ (1,0) [0|0] "" Vector__XXX
 SG_ VCSEC_Device9WLEntry m54 : 32|5@1+ (1,0) [0|0] "" Vector__XXX
 SG_ VCSEC_Device0CpuTime m1 : 34|30@1+ (1,0) [0|0] "" Vector__XXX
 SG_ VCSEC_Device10CpuTime m61 : 34|30@1+ (1,0) [0|0] "" Vector__XXX
 SG_ VCSEC_Device11CpuTime m67 : 34|30@1+ (1,0) [0|0] "" Vector__XXX
 SG_ VCSEC_Device12CpuTime m73 : 34|30@1+ (1,0) [0|0] "" Vector__XXX
 SG_ VCSEC_Device13CpuTime m79 : 34|30@1+ (1,0) [0|0] "" Vector__XXX
 SG_ VCSEC_Device14CpuTime m85 : 34|30@1+ (1,0) [0|0] "" Vector__XXX
 SG_ VCSEC_Device15CpuTime m91 : 34|30@1+ (1,0) [0|0] "" Vector__XXX
 SG_ VCSEC_Device16CpuTime m97 : 34|30@1+ (1,0) [0|0] "" Vector__XXX
 SG_ VCSEC_Device17CpuTime m103 : 34|30@1+ (1,0) [0|0] "" Vector__XXX
 SG_ VCSEC_Device18CpuTime m109 : 34|30@1+ (1,0) [0|0] "" Vector__XXX
 SG_ VCSEC_Device19CpuTime m115 : 34|30@1+ (1,0) [0|0] "" Vector__XXX
 SG_ VCSEC_Device1CpuTime m7 : 34|30@1+ (1,0) [0|0] "" Vector__XXX
 SG_ VCSEC_Device2CpuTime m13 : 34|30@1+ (1,0) [0|0] "" Vector__XXX
 SG_ VCSEC_Device3CpuTime m19 : 34|30@1+ (1,0) [0|0] "" Vector__XXX
 SG_ VCSEC_Device4CpuTime m25 : 34|30@1+ (1,0) [0|0] "" Vector__XXX
 SG_ VCSEC_Device5CpuTime m31 : 34|30@1+ (1,0) [0|0] "" Vector__XXX
 SG_ VCSEC_Device6CpuTime m37 : 34|30@1+ (1,0) [0|0] "" Vector__XXX
 SG_ VCSEC_Device7CpuTime m43 : 34|30@1+ (1,0) [0|0] "" Vector__XXX
 SG_ VCSEC_Device8CpuTime m49 : 34|30@1+ (1,0) [0|0] "" Vector__XXX
 SG_ VCSEC_Device9CpuTime m55 : 34|30@1+ (1,0) [0|0] "" Vector__XXX
 SG_ VCSEC_Device0OSVersion m0 : 37|12@1+ (1,0) [0|0] "" Vector__XXX
 SG_ VCSEC_Device10OSVersion m60 : 37|12@1+ (1,0) [0|0] "" Vector__XXX
 SG_ VCSEC_Device11OSVersion m66 : 37|12@1+ (1,0) [0|0] "" Vector__XXX
 SG_ VCSEC_Device12OSVersion m72 : 37|12@1+ (1,0) [0|0] "" Vector__XXX
 SG_ VCSEC_Device13OSVersion m78 : 37|12@1+ (1,0) [0|0] "" Vector__XXX
 SG_ VCSEC_Device14OSVersion m84 : 37|12@1+ (1,0) [0|0] "" Vector__XXX
 SG_ VCSEC_Device15OSVersion m90 : 37|12@1+ (1,0) [0|0] "" Vector__XXX
 SG_ VCSEC_Device16OSVersion m96 : 37|12@1+ (1,0) [0|0] "" Vector__XXX
 SG_ VCSEC_Device17OSVersion m102 : 37|12@1+ (1,0) [0|0] "" Vector__XXX
 SG_ VCSEC_Device18OSVersion m108 : 37|12@1+ (1,0) [0|0] "" Vector__XXX
 SG_ VCSEC_Device19OSVersion m114 : 37|12@1+ (1,0) [0|0] "" Vector__XXX
 SG_ VCSEC_Device1OSVersion m6 : 37|12@1+ (1,0) [0|0] "" Vector__XXX
 SG_ VCSEC_Device2OSVersion m12 : 37|12@1+ (1,0) [0|0] "" Vector__XXX
 SG_ VCSEC_Device3OSVersion m18 : 37|12@1+ (1,0) [0|0] "" Vector__XXX
 SG_ VCSEC_Device4OSVersion m24 : 37|12@1+ (1,0) [0|0] "" Vector__XXX
 SG_ VCSEC_Device5OSVersion m30 : 37|12@1+ (1,0) [0|0] "" Vector__XXX
 SG_ VCSEC_Device6OSVersion m36 : 37|12@1+ (1,0) [0|0] "" Vector__XXX
 SG_ VCSEC_Device7OSVersion m42 : 37|12@1+ (1,0) [0|0] "" Vector__XXX
 SG_ VCSEC_Device8OSVersion m48 : 37|12@1+ (1,0) [0|0] "" Vector__XXX
 SG_ VCSEC_Device9OSVersion m54 : 37|12@1+ (1,0) [0|0] "" Vector__XXX
 SG_ VCSEC_Device0BatteryLevel m0 : 49|8@1+ (0.015625,0) [0|0] "" Vector__XXX
 SG_ VCSEC_Device10BatteryLevel m60 : 49|8@1+ (0.015625,0) [0|0] "" Vector__XXX
 SG_ VCSEC_Device11BatteryLevel m66 : 49|8@1+ (0.015625,0) [0|0] "" Vector__XXX
 SG_ VCSEC_Device12BatteryLevel m72 : 49|8@1+ (0.015625,0) [0|0] "" Vector__XXX
 SG_ VCSEC_Device13BatteryLevel m78 : 49|8@1+ (0.015625,0) [0|0] "" Vector__XXX
 SG_ VCSEC_Device14BatteryLevel m84 : 49|8@1+ (0.015625,0) [0|0] "" Vector__XXX
 SG_ VCSEC_Device15BatteryLevel m90 : 49|8@1+ (0.015625,0) [0|0] "" Vector__XXX
 SG_ VCSEC_Device16BatteryLevel m96 : 49|8@1+ (0.015625,0) [0|0] "" Vector__XXX
 SG_ VCSEC_Device17BatteryLevel m102 : 49|8@1+ (0.015625,0) [0|0] "" Vector__XXX
 SG_ VCSEC_Device18BatteryLevel m108 : 49|8@1+ (0.015625,0) [0|0] "" Vector__XXX
 SG_ VCSEC_Device19BatteryLevel m114 : 49|8@1+ (0.015625,0) [0|0] "" Vector__XXX
 SG_ VCSEC_Device1BatteryLevel m6 : 49|8@1+ (0.015625,0) [0|0] "" Vector__XXX
 SG_ VCSEC_Device2BatteryLevel m12 : 49|8@1+ (0.015625,0) [0|0] "" Vector__XXX
 SG_ VCSEC_Device3BatteryLevel m18 : 49|8@1+ (0.015625,0) [0|0] "" Vector__XXX
 SG_ VCSEC_Device4BatteryLevel m24 : 49|8@1+ (0.015625,0) [0|0] "" Vector__XXX
 SG_ VCSEC_Device5BatteryLevel m30 : 49|8@1+ (0.015625,0) [0|0] "" Vector__XXX
 SG_ VCSEC_Device6BatteryLevel m36 : 49|8@1+ (0.015625,0) [0|0] "" Vector__XXX
 SG_ VCSEC_Device7BatteryLevel m42 : 49|8@1+ (0.015625,0) [0|0] "" Vector__XXX
 SG_ VCSEC_Device8BatteryLevel m48 : 49|8@1+ (0.015625,0) [0|0] "" Vector__XXX
 SG_ VCSEC_Device9BatteryLevel m54 : 49|8@1+ (0.015625,0) [0|0] "" Vector__XXX
 SG_ VCSEC_Device0Formfactor m0 : 57|5@1+ (1,0) [0|0] "" Vector__XXX
 SG_ VCSEC_Device10Formfactor m60 : 57|5@1+ (1,0) [0|0] "" Vector__XXX
 SG_ VCSEC_Device11Formfactor m66 : 57|5@1+ (1,0) [0|0] "" Vector__XXX
 SG_ VCSEC_Device12Formfactor m72 : 57|5@1+ (1,0) [0|0] "" Vector__XXX
 SG_ VCSEC_Device13Formfactor m78 : 57|5@1+ (1,0) [0|0] "" Vector__XXX
 SG_ VCSEC_Device14Formfactor m84 : 57|5@1+ (1,0) [0|0] "" Vector__XXX
 SG_ VCSEC_Device15Formfactor m90 : 57|5@1+ (1,0) [0|0] "" Vector__XXX
 SG_ VCSEC_Device16Formfactor m96 : 57|5@1+ (1,0) [0|0] "" Vector__XXX
 SG_ VCSEC_Device17Formfactor m102 : 57|5@1+ (1,0) [0|0] "" Vector__XXX
 SG_ VCSEC_Device18Formfactor m108 : 57|5@1+ (1,0) [0|0] "" Vector__XXX
 SG_ VCSEC_Device19Formfactor m114 : 57|5@1+ (1,0) [0|0] "" Vector__XXX
 SG_ VCSEC_Device1Formfactor m6 : 57|5@1+ (1,0) [0|0] "" Vector__XXX
 SG_ VCSEC_Device2Formfactor m12 : 57|5@1+ (1,0) [0|0] "" Vector__XXX
 SG_ VCSEC_Device3Formfactor m18 : 57|5@1+ (1,0) [0|0] "" Vector__XXX
 SG_ VCSEC_Device4Formfactor m24 : 57|5@1+ (1,0) [0|0] "" Vector__XXX
 SG_ VCSEC_Device5Formfactor m30 : 57|5@1+ (1,0) [0|0] "" Vector__XXX
 SG_ VCSEC_Device6Formfactor m36 : 57|5@1+ (1,0) [0|0] "" Vector__XXX
 SG_ VCSEC_Device7Formfactor m42 : 57|5@1+ (1,0) [0|0] "" Vector__XXX
 SG_ VCSEC_Device8Formfactor m48 : 57|5@1+ (1,0) [0|0] "" Vector__XXX
 SG_ VCSEC_Device9Formfactor m54 : 57|5@1+ (1,0) [0|0] "" Vector__XXX
 SG_ VCSEC_Device0BlacklistStatus m0 : 62|1@1+ (1,0) [0|0] "" Vector__XXX
 SG_ VCSEC_Device10BlacklistStatus m60 : 62|1@1+ (1,0) [0|0] "" Vector__XXX
 SG_ VCSEC_Device11BlacklistStatus m66 : 62|1@1+ (1,0) [0|0] "" Vector__XXX
 SG_ VCSEC_Device12BlacklistStatus m72 : 62|1@1+ (1,0) [0|0] "" Vector__XXX
 SG_ VCSEC_Device13BlacklistStatus m78 : 62|1@1+ (1,0) [0|0] "" Vector__XXX
 SG_ VCSEC_Device14BlacklistStatus m84 : 62|1@1+ (1,0) [0|0] "" Vector__XXX
 SG_ VCSEC_Device15BlacklistStatus m90 : 62|1@1+ (1,0) [0|0] "" Vector__XXX
 SG_ VCSEC_Device16BlacklistStatus m96 : 62|1@1+ (1,0) [0|0] "" Vector__XXX
 SG_ VCSEC_Device17BlacklistStatus m102 : 62|1@1+ (1,0) [0|0] "" Vector__XXX
 SG_ VCSEC_Device18BlacklistStatus m108 : 62|1@1+ (1,0) [0|0] "" Vector__XXX
 SG_ VCSEC_Device19BlacklistStatus m114 : 62|1@1+ (1,0) [0|0] "" Vector__XXX
 SG_ VCSEC_Device1BlacklistStatus m6 : 62|1@1+ (1,0) [0|0] "" Vector__XXX
 SG_ VCSEC_Device2BlacklistStatus m12 : 62|1@1+ (1,0) [0|0] "" Vector__XXX
 SG_ VCSEC_Device3BlacklistStatus m18 : 62|1@1+ (1,0) [0|0] "" Vector__XXX
 SG_ VCSEC_Device4BlacklistStatus m24 : 62|1@1+ (1,0) [0|0] "" Vector__XXX
 SG_ VCSEC_Device5BlacklistStatus m30 : 62|1@1+ (1,0) [0|0] "" Vector__XXX
 SG_ VCSEC_Device6BlacklistStatus m36 : 62|1@1+ (1,0) [0|0] "" Vector__XXX
 SG_ VCSEC_Device7BlacklistStatus m42 : 62|1@1+ (1,0) [0|0] "" Vector__XXX
 SG_ VCSEC_Device8BlacklistStatus m48 : 62|1@1+ (1,0) [0|0] "" Vector__XXX
 SG_ VCSEC_Device9BlacklistStatus m54 : 62|1@1+ (1,0) [0|0] "" Vector__XXX
 SG_ VCSEC_Device0Stationary m0 : 63|1@1+ (1,0) [0|0] "" Vector__XXX
 SG_ VCSEC_Device10Stationary m60 : 63|1@1+ (1,0) [0|0] "" Vector__XXX
 SG_ VCSEC_Device11Stationary m66 : 63|1@1+ (1,0) [0|0] "" Vector__XXX
 SG_ VCSEC_Device12Stationary m72 : 63|1@1+ (1,0) [0|0] "" Vector__XXX
 SG_ VCSEC_Device13Stationary m78 : 63|1@1+ (1,0) [0|0] "" Vector__XXX
 SG_ VCSEC_Device14Stationary m84 : 63|1@1+ (1,0) [0|0] "" Vector__XXX
 SG_ VCSEC_Device15Stationary m90 : 63|1@1+ (1,0) [0|0] "" Vector__XXX
 SG_ VCSEC_Device16Stationary m96 : 63|1@1+ (1,0) [0|0] "" Vector__XXX
 SG_ VCSEC_Device17Stationary m102 : 63|1@1+ (1,0) [0|0] "" Vector__XXX
 SG_ VCSEC_Device18Stationary m108 : 63|1@1+ (1,0) [0|0] "" Vector__XXX
 SG_ VCSEC_Device19Stationary m114 : 63|1@1+ (1,0) [0|0] "" Vector__XXX
 SG_ VCSEC_Device1Stationary m6 : 63|1@1+ (1,0) [0|0] "" Vector__XXX
 SG_ VCSEC_Device2Stationary m12 : 63|1@1+ (1,0) [0|0] "" Vector__XXX
 SG_ VCSEC_Device3Stationary m18 : 63|1@1+ (1,0) [0|0] "" Vector__XXX
 SG_ VCSEC_Device4Stationary m24 : 63|1@1+ (1,0) [0|0] "" Vector__XXX
 SG_ VCSEC_Device5Stationary m30 : 63|1@1+ (1,0) [0|0] "" Vector__XXX
 SG_ VCSEC_Device6Stationary m36 : 63|1@1+ (1,0) [0|0] "" Vector__XXX
 SG_ VCSEC_Device7Stationary m42 : 63|1@1+ (1,0) [0|0] "" Vector__XXX
 SG_ VCSEC_Device8Stationary m48 : 63|1@1+ (1,0) [0|0] "" Vector__XXX
 SG_ VCSEC_Device9Stationary m54 : 63|1@1+ (1,0) [0|0] "" Vector__XXX

BO_ 858 DIF_alertMatrix3: 8 Vector__XXX
 SG_ DIF_a133_capacitorOT : 4|1@1+ (1,0) [0|0] "" Vector__XXX
 SG_ DIF_a134_wheelSpeedIrrational : 5|1@1+ (1,0) [0|0] "" Vector__XXX
 SG_ DIF_a136_spiError : 7|1@1+ (1,0) [0|0] "" Vector__XXX
 SG_ DIF_a142_highLashAngle : 13|1@1+ (1,0) [0|0] "" Vector__XXX
 SG_ DIF_a144_configMismatch : 15|1@1+ (1,0) [0|0] "" Vector__XXX
 SG_ DIF_a147_highTorqueWearLimit : 18|1@1+ (1,0) [0|0] "" Vector__XXX
 SG_ DIF_a148_burnInCycleEnded : 19|1@1+ (1,0) [0|0] "" Vector__XXX
 SG_ DIF_a149_oilPumpFailure : 20|1@1+ (1,0) [0|0] "" Vector__XXX
 SG_ DIF_a150_busVD : 21|1@1+ (1,0) [0|0] "" Vector__XXX
 SG_ DIF_a151_shockTorqueLimiter : 22|1@1+ (1,0) [0|0] "" Vector__XXX
 SG_ DIF_a152_linError : 23|1@1+ (1,0) [0|0] "" Vector__XXX
 SG_ DIF_a153_oilPumpDiagnostics : 24|1@1+ (1,0) [0|0] "" Vector__XXX
 SG_ DIF_a154_resolver : 25|1@1+ (1,0) [0|0] "" Vector__XXX
 SG_ DIF_a155_vcfrontMIA : 26|1@1+ (1,0) [0|0] "" Vector__XXX
 SG_ DIF_a156_currentObserver : 27|1@1+ (1,0) [0|0] "" Vector__XXX
 SG_ DIF_a157_rcmMIA : 28|1@1+ (1,0) [0|0] "" Vector__XXX
 SG_ DIF_a158_ibstMIA : 29|1@1+ (1,0) [0|0] "" Vector__XXX
 SG_ DIF_a160_busVoltageAnomaly : 31|1@1+ (1,0) [0|0] "" Vector__XXX
 SG_ DIF_a161_epas3pMIA : 32|1@1+ (1,0) [0|0] "" Vector__XXX
 SG_ DIF_a162_endOfLifetimeBurnIn : 33|1@1+ (1,0) [0|0] "" Vector__XXX
 SG_ DIF_a172_statorOilTempOT : 43|1@1+ (1,0) [0|0] "" Vector__XXX
 SG_ DIF_a173_ascFdbkDiagnostic : 44|1@1+ (1,0) [0|0] "" Vector__XXX
 SG_ DIF_a174_unitMayNotRestart : 45|1@1+ (1,0) [0|0] "" Vector__XXX
 SG_ DIF_a176_safetyICFault : 47|1@1+ (1,0) [0|0] "" Vector__XXX
 SG_ DIF_a177_fluxReferenceCorrected : 48|1@1+ (1,0) [0|0] "" Vector__XXX

BO_ 859 DIF_alertMatrix4: 8 Vector__XXX
 SG_ DIF_a202_excessHeatUnavailable : 9|1@1+ (1,0) [0|0] "" Vector__XXX
 SG_ DIF_a225_tmpEstPlausibility : 32|1@1+ (1,0) [0|0] "" Vector__XXX
 SG_ DIF_a229_busVsensorOverCAN : 36|1@1+ (1,0) [0|0] "" Vector__XXX
 SG_ DIF_a233_diMsgMissed : 40|1@1+ (1,0) [0|0] "" Vector__XXX
 SG_ DIF_a234_pcsMIA : 41|1@1+ (1,0) [0|0] "" Vector__XXX
 SG_ DIF_a236_tasMIA : 43|1@1+ (1,0) [0|0] "" Vector__XXX
 SG_ DIF_a240_clearFusesRoutine : 47|1@1+ (1,0) [0|0] "" Vector__XXX
 SG_ DIF_a241_systemThermallyLimited : 48|1@1+ (1,0) [0|0] "" Vector__XXX
 SG_ DIF_a242_spinDownLearning : 49|1@1+ (1,0) [0|0] "" Vector__XXX
 SG_ DIF_a243_ecuLogAvailable : 50|1@1+ (1,0) [0|0] "" Vector__XXX
 SG_ DIF_a244_mechSafeStateApplied : 51|1@1+ (1,0) [0|0] "" Vector__XXX
 SG_ DIF_a245_mechSafeStatePreWarn : 52|1@1+ (1,0) [0|0] "" Vector__XXX
 SG_ DIF_a246_recoveryAtSpeedError : 53|1@1+ (1,0) [0|0] "" Vector__XXX
 SG_ DIF_a247_rotorOffsetError : 54|1@1+ (1,0) [0|0] "" Vector__XXX
 SG_ DIF_a249_highStatorTempFromResist : 56|1@1+ (1,0) [0|0] "" Vector__XXX
 SG_ DIF_a250_preregulatorRail : 57|1@1+ (1,0) [0|0] "" Vector__XXX
 SG_ DIF_a251_oilPumpService : 58|1@1+ (1,0) [0|0] "" Vector__XXX
 SG_ DIF_a252_currentCoreFallback : 59|1@1+ (1,0) [0|0] "" Vector__XXX
 SG_ DIF_a253_lvBoostedRail : 60|1@1+ (1,0) [0|0] "" Vector__XXX
 SG_ DIF_a254_activeDischargeRail : 61|1@1+ (1,0) [0|0] "" Vector__XXX
 SG_ DIF_a255_currentGainFallback : 62|1@1+ (1,0) [0|0] "" Vector__XXX

BO_ 863 BMS_gridFormControl: 8 Vector__XXX
 SG_ BMS_gridFormCpRequest : 0|1@1+ (1,0) [0|0] "" Vector__XXX
 SG_ BMS_weldCheckCpRequest : 1|1@1+ (1,0) [0|0] "" Vector__XXX
 SG_ BMS_gridFormOutletRequest : 2|2@1+ (1,0) [0|0] "" Vector__XXX

BO_ 864 VCLEFT_alertMatrix: 8 Vector__XXX
 SG_ VCLEFT_matrixIndex M : 0|4@1+ (1,0) [0|0] "" Vector__XXX
 SG_ VCLEFT_a001_WatchdogReset m0 : 4|1@1+ (1,0) [0|0] "" Vector__XXX
 SG_ VCLEFT_a061_XCPConnected m1 : 4|1@1+ (1,0) [0|0] "" Vector__XXX
 SG_ VCLEFT_a181_rearDoorLatchRehome m3 : 4|1@1+ (1,0) [0|0] "" Vector__XXX
 SG_ VCLEFT_a241_seatHeatMIAFront m4 : 4|1@1+ (1,0) [0|0] "" Vector__XXX
 SG_ VCLEFT_a301_swcOverVoltage m5 : 4|1@1+ (1,0) [0|0] "" Vector__XXX
 SG_ VCLEFT_a361_stationaryThresholdsIncorrect m6 : 4|1@1+ (1,0) [0|0] "" Vector__XXX
 SG_ VCLEFT_a481_vnf1048SelfTestFailure m8 : 4|1@1+ (1,0) [0|0] "" Vector__XXX
 SG_ VCLEFT_a002_PowerLossReset m0 : 5|1@1+ (1,0) [0|0] "" Vector__XXX
 SG_ VCLEFT_a062_XCPWasConnected m1 : 5|1@1+ (1,0) [0|0] "" Vector__XXX
 SG_ VCLEFT_a122_ICR_MIA m2 : 5|1@1+ (1,0) [0|0] "" Vector__XXX
 SG_ VCLEFT_a182_emergencyLatchRel m3 : 5|1@1+ (1,0) [0|0] "" Vector__XXX
 SG_ VCLEFT_a242_seatHeatIRearL m4 : 5|1@1+ (1,0) [0|0] "" Vector__XXX
 SG_ VCLEFT_a302_blowerGeneralFault m5 : 5|1@1+ (1,0) [0|0] "" Vector__XXX
 SG_ VCLEFT_a362_movingThresholdsIncorrect m6 : 5|1@1+ (1,0) [0|0] "" Vector__XXX
 SG_ VCLEFT_a482_NCV77XXFault m8 : 5|1@1+ (1,0) [0|0] "" Vector__XXX
 SG_ VCLEFT_a003_SWAssertion m0 : 6|1@1+ (1,0) [0|0] "" Vector__XXX
 SG_ VCLEFT_a063_SwitchFault m1 : 6|1@1+ (1,0) [0|0] "" Vector__XXX
 SG_ VCLEFT_a123_AID_MIA m2 : 6|1@1+ (1,0) [0|0] "" Vector__XXX
 SG_ VCLEFT_a183_doorStateFactoryTest m3 : 6|1@1+ (1,0) [0|0] "" Vector__XXX
 SG_ VCLEFT_a243_seatHeatShortRearL m4 : 6|1@1+ (1,0) [0|0] "" Vector__XXX
 SG_ VCLEFT_a303_eFuseMgmtWindowLift m5 : 6|1@1+ (1,0) [0|0] "" Vector__XXX
 SG_ VCLEFT_a363_liftgateOpenAngleSetReq m6 : 6|1@1+ (1,0) [0|0] "" Vector__XXX
 SG_ VCLEFT_a483_leftTurnLightFaultUser m8 : 6|1@1+ (1,0) [0|0] "" Vector__XXX
 SG_ VCLEFT_a064_busSleepReqTimeout m1 : 7|1@1+ (1,0) [0|0] "" Vector__XXX
 SG_ VCLEFT_a244_seatHeatMIARearL m4 : 7|1@1+ (1,0) [0|0] "" Vector__XXX
 SG_ VCLEFT_a304_frontIntHandleUnexpectedVoltage m5 : 7|1@1+ (1,0) [0|0] "" Vector__XXX
 SG_ VCLEFT_a484_leftBrakeLightFaultUser m8 : 7|1@1+ (1,0) [0|0] "" Vector__XXX
 SG_ VCLEFT_a005_CANTXError m0 : 8|1@1+ (1,0) [0|0] "" Vector__XXX
 SG_ VCLEFT_a065_emiosIsrRateLimitedDbg m1 : 8|1@1+ (1,0) [0|0] "" Vector__XXX
 SG_ VCLEFT_a185_summonAborted m3 : 8|1@1+ (1,0) [0|0] "" Vector__XXX
 SG_ VCLEFT_a245_seatHeatIRearC m4 : 8|1@1+ (1,0) [0|0] "" Vector__XXX
 SG_ VCLEFT_a305_rearIntHandleUnexpectedVoltage m5 : 8|1@1+ (1,0) [0|0] "" Vector__XXX
 SG_ VCLEFT_a365_pitchUnlatchDisabled m6 : 8|1@1+ (1,0) [0|0] "" Vector__XXX
 SG_ VCLEFT_a545_LVBatteryTypeUnknown m9 : 8|1@1+ (1,0) [0|0] "" Vector__XXX
 SG_ VCLEFT_a006_CANTX_cyclicError m0 : 9|1@1+ (1,0) [0|0] "" Vector__XXX
 SG_ VCLEFT_a066_emiosIsrShortPeriodDetectedDbg m1 : 9|1@1+ (1,0) [0|0] "" Vector__XXX
 SG_ VCLEFT_a186_latchReleaseFailedF m3 : 9|1@1+ (1,0) [0|0] "" Vector__XXX
 SG_ VCLEFT_a246_seatHeatShortRearC m4 : 9|1@1+ (1,0) [0|0] "" Vector__XXX
 SG_ VCLEFT_a306_handleDisconnectedF m5 : 9|1@1+ (1,0) [0|0] "" Vector__XXX
 SG_ VCLEFT_a426_seatAbuseMotorWarn m7 : 9|1@1+ (1,0) [0|0] "" Vector__XXX
 SG_ VCLEFT_a546_mirrorFoldTypeChanged m9 : 9|1@1+ (1,0) [0|0] "" Vector__XXX
 SG_ VCLEFT_a187_latchReleaseFailedR m3 : 10|1@1+ (1,0) [0|0] "" Vector__XXX
 SG_ VCLEFT_a247_seatHeatMIARearC m4 : 10|1@1+ (1,0) [0|0] "" Vector__XXX
 SG_ VCLEFT_a307_handleDisconnectedR m5 : 10|1@1+ (1,0) [0|0] "" Vector__XXX
 SG_ VCLEFT_a427_seatAbuseMotorStop m7 : 10|1@1+ (1,0) [0|0] "" Vector__XXX
 SG_ VCLEFT_a188_latchUnableToRearmF m3 : 11|1@1+ (1,0) [0|0] "" Vector__XXX
 SG_ VCLEFT_a248_seatHeatIRearR m4 : 11|1@1+ (1,0) [0|0] "" Vector__XXX
 SG_ VCLEFT_a308_sirenMIA m5 : 11|1@1+ (1,0) [0|0] "" Vector__XXX
 SG_ VCLEFT_a428_seatAbuseBufferWarn m7 : 11|1@1+ (1,0) [0|0] "" Vector__XXX
 SG_ VCLEFT_a129_blowerICLatchFault m2 : 12|1@1+ (1,0) [0|0] "" Vector__XXX
 SG_ VCLEFT_a189_latchUnableToRearmR m3 : 12|1@1+ (1,0) [0|0] "" Vector__XXX
 SG_ VCLEFT_a249_seatHeatShortRearR m4 : 12|1@1+ (1,0) [0|0] "" Vector__XXX
 SG_ VCLEFT_a309_brakeSwitchFaulted m5 : 12|1@1+ (1,0) [0|0] "" Vector__XXX
 SG_ VCLEFT_a429_seatAbuseBufferFull m7 : 12|1@1+ (1,0) [0|0] "" Vector__XXX
 SG_ VCLEFT_a010_ExtSupplyVoltError m0 : 13|1@1+ (1,0) [0|0] "" Vector__XXX
 SG_ VCLEFT_a130_blowerICWarning m2 : 13|1@1+ (1,0) [0|0] "" Vector__XXX
 SG_ VCLEFT_a190_eFuseMgmtVbatFused m3 : 13|1@1+ (1,0) [0|0] "" Vector__XXX
 SG_ VCLEFT_a250_seatHeatMIARearR m4 : 13|1@1+ (1,0) [0|0] "" Vector__XXX
 SG_ VCLEFT_a310_mirrorFoldStall m5 : 13|1@1+ (1,0) [0|0] "" Vector__XXX
 SG_ VCLEFT_a370_seat2RowPitchUnlatched m6 : 13|1@1+ (1,0) [0|0] "" Vector__XXX
 SG_ VCLEFT_a490_vehicleOccupiedOnOTAStart m8 : 13|1@1+ (1,0) [0|0] "" Vector__XXX
 SG_ VCLEFT_a550_ambientTempDelta m9 : 13|1@1+ (1,0) [0|0] "" Vector__XXX
 SG_ VCLEFT_a131_blowerICTransFault m2 : 14|1@1+ (1,0) [0|0] "" Vector__XXX
 SG_ VCLEFT_a191_TLCOvercurrent m3 : 14|1@1+ (1,0) [0|0] "" Vector__XXX
 SG_ VCLEFT_a251_seatUncalTrack m4 : 14|1@1+ (1,0) [0|0] "" Vector__XXX
 SG_ VCLEFT_a311_leftBrakeLightFault m5 : 14|1@1+ (1,0) [0|0] "" Vector__XXX
 SG_ VCLEFT_a371_seat2RowTrackUnlatched m6 : 14|1@1+ (1,0) [0|0] "" Vector__XXX
 SG_ VCLEFT_a551_interiorDoorRequestInhibited m9 : 14|1@1+ (1,0) [0|0] "" Vector__XXX
 SG_ VCLEFT_a012_CPUReset m0 : 15|1@1+ (1,0) [0|0] "" Vector__XXX
 SG_ VCLEFT_a132_blowerSoftStall m2 : 15|1@1+ (1,0) [0|0] "" Vector__XXX
 SG_ VCLEFT_a192_blowerGeneralFault m3 : 15|1@1+ (1,0) [0|0] "" Vector__XXX
 SG_ VCLEFT_a252_seatUncalBack m4 : 15|1@1+ (1,0) [0|0] "" Vector__XXX
 SG_ VCLEFT_a312_leftTailLightFault m5 : 15|1@1+ (1,0) [0|0] "" Vector__XXX
 SG_ VCLEFT_a372_seat2RowBackrestUnlatched m6 : 15|1@1+ (1,0) [0|0] "" Vector__XXX
 SG_ VCLEFT_a013_AlertManagerFault m0 : 16|1@1+ (1,0) [0|0] "" Vector__XXX
 SG_ VCLEFT_a133_blowerLowRPMCBang m2 : 16|1@1+ (1,0) [0|0] "" Vector__XXX
 SG_ VCLEFT_a193_blowerMIA m3 : 16|1@1+ (1,0) [0|0] "" Vector__XXX
 SG_ VCLEFT_a253_seatUncalTilt m4 : 16|1@1+ (1,0) [0|0] "" Vector__XXX
 SG_ VCLEFT_a313_leftFootwellLightFault m5 : 16|1@1+ (1,0) [0|0] "" Vector__XXX
 SG_ VCLEFT_a373_windowSwOpenReqInDogMode m6 : 16|1@1+ (1,0) [0|0] "" Vector__XXX
 SG_ VCLEFT_a134_SteerColUpDownUnCal m2 : 17|1@1+ (1,0) [0|0] "" Vector__XXX
 SG_ VCLEFT_a254_seatUncalLift m4 : 17|1@1+ (1,0) [0|0] "" Vector__XXX
 SG_ VCLEFT_a314_leftMapPocketLightFault m5 : 17|1@1+ (1,0) [0|0] "" Vector__XXX
 SG_ VCLEFT_a374_trailerLightFaultModelY m6 : 17|1@1+ (1,0) [0|0] "" Vector__XXX
 SG_ VCLEFT_a015_NVMMError m0 : 18|1@1+ (1,0) [0|0] "" Vector__XXX
 SG_ VCLEFT_a135_SteerColInOutUnCal m2 : 18|1@1+ (1,0) [0|0] "" Vector__XXX
 SG_ VCLEFT_a315_leftInteriorTrunkLightFault m5 : 18|1@1+ (1,0) [0|0] "" Vector__XXX
 SG_ VCLEFT_a375_windowPinchOverrideNudge m6 : 18|1@1+ (1,0) [0|0] "" Vector__XXX
 SG_ VCLEFT_a016_NVMMRecordError m0 : 19|1@1+ (1,0) [0|0] "" Vector__XXX
 SG_ VCLEFT_a136_brakeSwitchMismatch m2 : 19|1@1+ (1,0) [0|0] "" Vector__XXX
 SG_ VCLEFT_a196_VEHCANOverterminate m3 : 19|1@1+ (1,0) [0|0] "" Vector__XXX
 SG_ VCLEFT_a316_mirrorPrematureFoldStall m5 : 19|1@1+ (1,0) [0|0] "" Vector__XXX
 SG_ VCLEFT_a376_seat2RowBridgeCurrentExceeded m6 : 19|1@1+ (1,0) [0|0] "" Vector__XXX
 SG_ VCLEFT_a017_NVMMStatusDbg m0 : 20|1@1+ (1,0) [0|0] "" Vector__XXX
 SG_ VCLEFT_a137_VCSECPowerCycled m2 : 20|1@1+ (1,0) [0|0] "" Vector__XXX
 SG_ VCLEFT_a197_VEHCANUndertrminate m3 : 20|1@1+ (1,0) [0|0] "" Vector__XXX
 SG_ VCLEFT_a317_epbmLimpModeEnabled m5 : 20|1@1+ (1,0) [0|0] "" Vector__XXX
 SG_ VCLEFT_a617_APP_MIA m10 : 20|1@1+ (1,0) [0|0] "" Vector__XXX
 SG_ VCLEFT_a138_consoleDoorAssist m2 : 21|1@1+ (1,0) [0|0] "" Vector__XXX
 SG_ VCLEFT_a318_trailerIncorrectConfig m5 : 21|1@1+ (1,0) [0|0] "" Vector__XXX
 SG_ VCLEFT_a139_BLERearPowerCycled m2 : 22|1@1+ (1,0) [0|0] "" Vector__XXX
 SG_ VCLEFT_a259_latchDisarmDelayF m4 : 22|1@1+ (1,0) [0|0] "" Vector__XXX
 SG_ VCLEFT_a499_epbmInvalidateCdp m8 : 22|1@1+ (1,0) [0|0] "" Vector__XXX
 SG_ VCLEFT_a140_BLELeftPowerCycled m2 : 23|1@1+ (1,0) [0|0] "" Vector__XXX
 SG_ VCLEFT_a200_motorPhantomEncoder m3 : 23|1@1+ (1,0) [0|0] "" Vector__XXX
 SG_ VCLEFT_a260_latchDisarmDelayR m4 : 23|1@1+ (1,0) [0|0] "" Vector__XXX
 SG_ VCLEFT_a320_windowReportCrackedAtTrimClear m5 : 23|1@1+ (1,0) [0|0] "" Vector__XXX
 SG_ VCLEFT_a380_steerColThermalLimited m6 : 23|1@1+ (1,0) [0|0] "" Vector__XXX
 SG_ VCLEFT_a500_eFuseASICStateMismatch m8 : 23|1@1+ (1,0) [0|0] "" Vector__XXX
 SG_ VCLEFT_a021_TaskSchedulerError m0 : 24|1@1+ (1,0) [0|0] "" Vector__XXX
 SG_ VCLEFT_a141_12VAuxPowerTrip m2 : 24|1@1+ (1,0) [0|0] "" Vector__XXX
 SG_ VCLEFT_a201_motorDutyEncDisabl m3 : 24|1@1+ (1,0) [0|0] "" Vector__XXX
 SG_ VCLEFT_a261_emergencyLatchRelRear m4 : 24|1@1+ (1,0) [0|0] "" Vector__XXX
 SG_ VCLEFT_a321_windowRezeroedDebugF m5 : 24|1@1+ (1,0) [0|0] "" Vector__XXX
 SG_ VCLEFT_a381_pitchEstimation1 m6 : 24|1@1+ (1,0) [0|0] "" Vector__XXX
 SG_ VCLEFT_a501_vnf1048ConfigurationMismatch m8 : 24|1@1+ (1,0) [0|0] "" Vector__XXX
 SG_ VCLEFT_a022_TaskInitError m0 : 25|1@1+ (1,0) [0|0] "" Vector__XXX
 SG_ VCLEFT_a082_VCRIGHT_IPC_MIA m1 : 25|1@1+ (1,0) [0|0] "" Vector__XXX
 SG_ VCLEFT_a202_epbmUnderIStatic m3 : 25|1@1+ (1,0) [0|0] "" Vector__XXX
 SG_ VCLEFT_a322_windowRezeroedDebugR m5 : 25|1@1+ (1,0) [0|0] "" Vector__XXX
 SG_ VCLEFT_a382_pitchEstimation2 m6 : 25|1@1+ (1,0) [0|0] "" Vector__XXX
 SG_ VCLEFT_a083_VCLEFT_IPC_MIA m1 : 26|1@1+ (1,0) [0|0] "" Vector__XXX
 SG_ VCLEFT_a143_mirrorManuallyFolded m2 : 26|1@1+ (1,0) [0|0] "" Vector__XXX
 SG_ VCLEFT_a203_epbmOverIStatic m3 : 26|1@1+ (1,0) [0|0] "" Vector__XXX
 SG_ VCLEFT_a263_seatTrackStallDebug m4 : 26|1@1+ (1,0) [0|0] "" Vector__XXX
 SG_ VCLEFT_a323_mirrorCalibrated m5 : 26|1@1+ (1,0) [0|0] "" Vector__XXX
 SG_ VCLEFT_a383_steerColInOutMotorStallCurrent m6 : 26|1@1+ (1,0) [0|0] "" Vector__XXX
 SG_ VCLEFT_a084_TPMS_MIA m1 : 27|1@1+ (1,0) [0|0] "" Vector__XXX
 SG_ VCLEFT_a204_epbmUnderIDyn m3 : 27|1@1+ (1,0) [0|0] "" Vector__XXX
 SG_ VCLEFT_a264_seatBackStallDebug m4 : 27|1@1+ (1,0) [0|0] "" Vector__XXX
 SG_ VCLEFT_a324_mirrorHeatFault m5 : 27|1@1+ (1,0) [0|0] "" Vector__XXX
 SG_ VCLEFT_a384_steerColUpDownMotorStallCurrent m6 : 27|1@1+ (1,0) [0|0] "" Vector__XXX
 SG_ VCLEFT_a444_drv8703Fault m7 : 27|1@1+ (1,0) [0|0] "" Vector__XXX
 SG_ VCLEFT_a085_CCCM_MIA m1 : 28|1@1+ (1,0) [0|0] "" Vector__XXX
 SG_ VCLEFT_a145_brakeSwitchStuck m2 : 28|1@1+ (1,0) [0|0] "" Vector__XXX
 SG_ VCLEFT_a205_epbmOverIDyn m3 : 28|1@1+ (1,0) [0|0] "" Vector__XXX
 SG_ VCLEFT_a265_seatTiltStallDebug m4 : 28|1@1+ (1,0) [0|0] "" Vector__XXX
 SG_ VCLEFT_a325_hghtSnsrUnplgdFL m5 : 28|1@1+ (1,0) [0|0] "" Vector__XXX
 SG_ VCLEFT_a385_steerColInOutMotorUnderCurrent m6 : 28|1@1+ (1,0) [0|0] "" Vector__XXX
 SG_ VCLEFT_a445_drv8703SpiFaultDBG m7 : 28|1@1+ (1,0) [0|0] "" Vector__XXX
 SG_ VCLEFT_a086_VCBATT_MIA m1 : 29|1@1+ (1,0) [0|0] "" Vector__XXX
 SG_ VCLEFT_a206_epbWrongDirection m3 : 29|1@1+ (1,0) [0|0] "" Vector__XXX
 SG_ VCLEFT_a266_seatLiftStallDebug m4 : 29|1@1+ (1,0) [0|0] "" Vector__XXX
 SG_ VCLEFT_a326_hghtSnsrUnplgdRL m5 : 29|1@1+ (1,0) [0|0] "" Vector__XXX
 SG_ VCLEFT_a386_steerColUpDownMotorUnderCurrent m6 : 29|1@1+ (1,0) [0|0] "" Vector__XXX
 SG_ VCLEFT_a446_trailerAuxReversePower m7 : 29|1@1+ (1,0) [0|0] "" Vector__XXX
 SG_ VCLEFT_a087_DIREL_MIA m1 : 30|1@1+ (1,0) [0|0] "" Vector__XXX
 SG_ VCLEFT_a207_epbmEnableWrong m3 : 30|1@1+ (1,0) [0|0] "" Vector__XXX
 SG_ VCLEFT_a267_seatTrackHCEncStlDbg m4 : 30|1@1+ (1,0) [0|0] "" Vector__XXX
 SG_ VCLEFT_a327_hghtSnsrFaultFL m5 : 30|1@1+ (1,0) [0|0] "" Vector__XXX
 SG_ VCLEFT_a387_steerColInOutMotorEncoderStalled m6 : 30|1@1+ (1,0) [0|0] "" Vector__XXX
 SG_ VCLEFT_a447_steeringColInOutEndstopCal m7 : 30|1@1+ (1,0) [0|0] "" Vector__XXX
 SG_ VCLEFT_a088_DIRER_MIA m1 : 31|1@1+ (1,0) [0|0] "" Vector__XXX
 SG_ VCLEFT_a208_epbFaulted m3 : 31|1@1+ (1,0) [0|0] "" Vector__XXX
 SG_ VCLEFT_a268_seatBackHCEncStlDbg m4 : 31|1@1+ (1,0) [0|0] "" Vector__XXX
 SG_ VCLEFT_a328_hghtSnsrFaultRL m5 : 31|1@1+ (1,0) [0|0] "" Vector__XXX
 SG_ VCLEFT_a388_steerColUpDownMotorEncoderStalled m6 : 31|1@1+ (1,0) [0|0] "" Vector__XXX
 SG_ VCLEFT_a448_steeringColUpDownEndstopCal m7 : 31|1@1+ (1,0) [0|0] "" Vector__XXX
 SG_ VCLEFT_a029_CoreDump m0 : 32|1@1+ (1,0) [0|0] "" Vector__XXX
 SG_ VCLEFT_a089_IBST_MIA m1 : 32|1@1+ (1,0) [0|0] "" Vector__XXX
 SG_ VCLEFT_a209_epbStateMisTime m3 : 32|1@1+ (1,0) [0|0] "" Vector__XXX
 SG_ VCLEFT_a269_seatTiltHCEncStlDbg m4 : 32|1@1+ (1,0) [0|0] "" Vector__XXX
 SG_ VCLEFT_a329_noRideHeightCalib m5 : 32|1@1+ (1,0) [0|0] "" Vector__XXX
 SG_ VCLEFT_a389_steerColInOutEncoderOutOfRange m6 : 32|1@1+ (1,0) [0|0] "" Vector__XXX
 SG_ VCLEFT_a030_ECULogUploadRequest m0 : 33|1@1+ (1,0) [0|0] "" Vector__XXX
 SG_ VCLEFT_a090_APS_MIA m1 : 33|1@1+ (1,0) [0|0] "" Vector__XXX
 SG_ VCLEFT_a150_windowPinchFront m2 : 33|1@1+ (1,0) [0|0] "" Vector__XXX
 SG_ VCLEFT_a210_epbStateTime m3 : 33|1@1+ (1,0) [0|0] "" Vector__XXX
 SG_ VCLEFT_a270_seatLiftHCEncStlDbg m4 : 33|1@1+ (1,0) [0|0] "" Vector__XXX
 SG_ VCLEFT_a330_shortDropFailedF m5 : 33|1@1+ (1,0) [0|0] "" Vector__XXX
 SG_ VCLEFT_a390_steerColUpDownEncoderOutOfRange m6 : 33|1@1+ (1,0) [0|0] "" Vector__XXX
 SG_ VCLEFT_a570_seatHeatDisabledF m9 : 33|1@1+ (1,0) [0|0] "" Vector__XXX
 SG_ VCLEFT_a031_UDSActive m0 : 34|1@1+ (1,0) [0|0] "" Vector__XXX
 SG_ VCLEFT_a091_CMPD_MIA m1 : 34|1@1+ (1,0) [0|0] "" Vector__XXX
 SG_ VCLEFT_a151_windowPinchRear m2 : 34|1@1+ (1,0) [0|0] "" Vector__XXX
 SG_ VCLEFT_a211_epbmUnderIStaticNew m3 : 34|1@1+ (1,0) [0|0] "" Vector__XXX
 SG_ VCLEFT_a331_shortDropFailedR m5 : 34|1@1+ (1,0) [0|0] "" Vector__XXX
 SG_ VCLEFT_a391_pitchEstimationImplausible m6 : 34|1@1+ (1,0) [0|0] "" Vector__XXX
 SG_ VCLEFT_a451_wirelessChargerMIA m7 : 34|1@1+ (1,0) [0|0] "" Vector__XXX
 SG_ VCLEFT_a571_seatHeatDisabledRearL m9 : 34|1@1+ (1,0) [0|0] "" Vector__XXX
 SG_ VCLEFT_a092_VCSEATD_MIA m1 : 35|1@1+ (1,0) [0|0] "" Vector__XXX
 SG_ VCLEFT_a152_windowUncalFront m2 : 35|1@1+ (1,0) [0|0] "" Vector__XXX
 SG_ VCLEFT_a212_epbmOverIStaticNew m3 : 35|1@1+ (1,0) [0|0] "" Vector__XXX
 SG_ VCLEFT_a272_vhclPwrStateMsmtch m4 : 35|1@1+ (1,0) [0|0] "" Vector__XXX
 SG_ VCLEFT_a332_intrusionSensorMIA m5 : 35|1@1+ (1,0) [0|0] "" Vector__XXX
 SG_ VCLEFT_a392_pitchEstimationGPSImprovedReinit m6 : 35|1@1+ (1,0) [0|0] "" Vector__XXX
 SG_ VCLEFT_a572_seatHeatDisabledRearC m9 : 35|1@1+ (1,0) [0|0] "" Vector__XXX
 SG_ VCLEFT_a093_VCSEATP_MIA m1 : 36|1@1+ (1,0) [0|0] "" Vector__XXX
 SG_ VCLEFT_a153_windowUncalRear m2 : 36|1@1+ (1,0) [0|0] "" Vector__XXX
 SG_ VCLEFT_a213_epbmUnderIDynNew m3 : 36|1@1+ (1,0) [0|0] "" Vector__XXX
 SG_ VCLEFT_a273_handleStuckActiveF m4 : 36|1@1+ (1,0) [0|0] "" Vector__XXX
 SG_ VCLEFT_a333_overheadConsoleMIA m5 : 36|1@1+ (1,0) [0|0] "" Vector__XXX
 SG_ VCLEFT_a393_pitchEstimationNoGPSFusion m6 : 36|1@1+ (1,0) [0|0] "" Vector__XXX
 SG_ VCLEFT_a453_liftgatePinchDetected m7 : 36|1@1+ (1,0) [0|0] "" Vector__XXX
 SG_ VCLEFT_a573_seatHeatDisabledRearR m9 : 36|1@1+ (1,0) [0|0] "" Vector__XXX
 SG_ VCLEFT_a094_EPAS3P_MIA m1 : 37|1@1+ (1,0) [0|0] "" Vector__XXX
 SG_ VCLEFT_a154_windowThermalFront m2 : 37|1@1+ (1,0) [0|0] "" Vector__XXX
 SG_ VCLEFT_a214_epbmOverIDynNew m3 : 37|1@1+ (1,0) [0|0] "" Vector__XXX
 SG_ VCLEFT_a274_handleStuckActiveR m4 : 37|1@1+ (1,0) [0|0] "" Vector__XXX
 SG_ VCLEFT_a334_overheadConsoleInternalFault m5 : 37|1@1+ (1,0) [0|0] "" Vector__XXX
 SG_ VCLEFT_a454_wirelessChargerFault m7 : 37|1@1+ (1,0) [0|0] "" Vector__XXX
 SG_ VCLEFT_a095_CHG_MIA m1 : 38|1@1+ (1,0) [0|0] "" Vector__XXX
 SG_ VCLEFT_a155_windowThermalRear m2 : 38|1@1+ (1,0) [0|0] "" Vector__XXX
 SG_ VCLEFT_a215_currentDesyncWarning m3 : 38|1@1+ (1,0) [0|0] "" Vector__XXX
 SG_ VCLEFT_a275_leftTurnLightFault m4 : 38|1@1+ (1,0) [0|0] "" Vector__XXX
 SG_ VCLEFT_a335_intrusionSensorInternalFault m5 : 38|1@1+ (1,0) [0|0] "" Vector__XXX
 SG_ VCLEFT_a455_liftgateUnexpectedShutfaceSwPressed m7 : 38|1@1+ (1,0) [0|0] "" Vector__XXX
 SG_ VCLEFT_a096_OCS1P_MIA m1 : 39|1@1+ (1,0) [0|0] "" Vector__XXX
 SG_ VCLEFT_a156_windowNoInputFront m2 : 39|1@1+ (1,0) [0|0] "" Vector__XXX
 SG_ VCLEFT_a216_SPI_MIA_debugData1 m3 : 39|1@1+ (1,0) [0|0] "" Vector__XXX
 SG_ VCLEFT_a276_mirrorDebug m4 : 39|1@1+ (1,0) [0|0] "" Vector__XXX
 SG_ VCLEFT_a336_windowDropRevThermalF m5 : 39|1@1+ (1,0) [0|0] "" Vector__XXX
 SG_ VCLEFT_a097_CMP_MIA m1 : 40|1@1+ (1,0) [0|0] "" Vector__XXX
 SG_ VCLEFT_a157_windowNoInputRear m2 : 40|1@1+ (1,0) [0|0] "" Vector__XXX
 SG_ VCLEFT_a217_SPI_MIA_debugData2 m3 : 40|1@1+ (1,0) [0|0] "" Vector__XXX
 SG_ VCLEFT_a277_BLELeftUnderVoltage m4 : 40|1@1+ (1,0) [0|0] "" Vector__XXX
 SG_ VCLEFT_a337_windowDropRevThermalR m5 : 40|1@1+ (1,0) [0|0] "" Vector__XXX
 SG_ VCLEFT_a098_DIR_MIA m1 : 41|1@1+ (1,0) [0|0] "" Vector__XXX
 SG_ VCLEFT_a158_windowPinchOverideF m2 : 41|1@1+ (1,0) [0|0] "" Vector__XXX
 SG_ VCLEFT_a218_motorDriverFault m3 : 41|1@1+ (1,0) [0|0] "" Vector__XXX
 SG_ VCLEFT_a278_BLERearUnderVoltage m4 : 41|1@1+ (1,0) [0|0] "" Vector__XXX
 SG_ VCLEFT_a338_trailerLightControllerMIA m5 : 41|1@1+ (1,0) [0|0] "" Vector__XXX
 SG_ VCLEFT_a578_RGBLightFault m9 : 41|1@1+ (1,0) [0|0] "" Vector__XXX
 SG_ VCLEFT_a099_PARK_MIA m1 : 42|1@1+ (1,0) [0|0] "" Vector__XXX
 SG_ VCLEFT_a159_windowPinchOverideR m2 : 42|1@1+ (1,0) [0|0] "" Vector__XXX
 SG_ VCLEFT_a219_motorCurrentDropout m3 : 42|1@1+ (1,0) [0|0] "" Vector__XXX
 SG_ VCLEFT_a279_VCSECUnderVoltage m4 : 42|1@1+ (1,0) [0|0] "" Vector__XXX
 SG_ VCLEFT_a339_trailerLeftTurnLightNotDetected m5 : 42|1@1+ (1,0) [0|0] "" Vector__XXX
 SG_ VCLEFT_a100_CANbus_MIA m1 : 43|1@1+ (1,0) [0|0] "" Vector__XXX
 SG_ VCLEFT_a160_windowUndercurrentF m2 : 43|1@1+ (1,0) [0|0] "" Vector__XXX
 SG_ VCLEFT_a280_latchDidNotDisarmF m4 : 43|1@1+ (1,0) [0|0] "" Vector__XXX
 SG_ VCLEFT_a340_trailerRightTurnLightNotDetected m5 : 43|1@1+ (1,0) [0|0] "" Vector__XXX
 SG_ VCLEFT_a520_configMismatch m8 : 43|1@1+ (1,0) [0|0] "" Vector__XXX
 SG_ VCLEFT_a041_HighCPULoad m0 : 44|1@1+ (1,0) [0|0] "" Vector__XXX
 SG_ VCLEFT_a101_PM_MIA m1 : 44|1@1+ (1,0) [0|0] "" Vector__XXX
 SG_ VCLEFT_a161_windowUndercurrentR m2 : 44|1@1+ (1,0) [0|0] "" Vector__XXX
 SG_ VCLEFT_a281_latchDidNotDisarmR m4 : 44|1@1+ (1,0) [0|0] "" Vector__XXX
 SG_ VCLEFT_a341_trailerLightFault m5 : 44|1@1+ (1,0) [0|0] "" Vector__XXX
 SG_ VCLEFT_a521_seatHeatPadUnexpectedVoltage m8 : 44|1@1+ (1,0) [0|0] "" Vector__XXX
 SG_ VCLEFT_a042_HighStackUsage m0 : 45|1@1+ (1,0) [0|0] "" Vector__XXX
 SG_ VCLEFT_a102_PTC_MIA m1 : 45|1@1+ (1,0) [0|0] "" Vector__XXX
 SG_ VCLEFT_a162_windowEncoderStallF m2 : 45|1@1+ (1,0) [0|0] "" Vector__XXX
 SG_ VCLEFT_a282_latchUnexpectedArmF m4 : 45|1@1+ (1,0) [0|0] "" Vector__XXX
 SG_ VCLEFT_a342_trailerLightControllerFault m5 : 45|1@1+ (1,0) [0|0] "" Vector__XXX
 SG_ VCLEFT_a522_trailerLightUnexpectedVoltage m8 : 45|1@1+ (1,0) [0|0] "" Vector__XXX
 SG_ VCLEFT_a043_Task1msError m0 : 46|1@1+ (1,0) [0|0] "" Vector__XXX
 SG_ VCLEFT_a103_CP_MIA m1 : 46|1@1+ (1,0) [0|0] "" Vector__XXX
 SG_ VCLEFT_a163_windowEncoderStallR m2 : 46|1@1+ (1,0) [0|0] "" Vector__XXX
 SG_ VCLEFT_a283_latchUnexpectedArmR m4 : 46|1@1+ (1,0) [0|0] "" Vector__XXX
 SG_ VCLEFT_a523_eFuseThresholdsIncorrect m8 : 46|1@1+ (1,0) [0|0] "" Vector__XXX
 SG_ VCLEFT_a583_doorRemoteUnlatchedFront m9 : 46|1@1+ (1,0) [0|0] "" Vector__XXX
 SG_ VCLEFT_a044_Task10msError m0 : 47|1@1+ (1,0) [0|0] "" Vector__XXX
 SG_ VCLEFT_a104_DAS_MIA m1 : 47|1@1+ (1,0) [0|0] "" Vector__XXX
 SG_ VCLEFT_a164_windowFactoryTest m2 : 47|1@1+ (1,0) [0|0] "" Vector__XXX
 SG_ VCLEFT_a224_seatEncStallTrack m3 : 47|1@1+ (1,0) [0|0] "" Vector__XXX
 SG_ VCLEFT_a284_blowerFbkSanity m4 : 47|1@1+ (1,0) [0|0] "" Vector__XXX
 SG_ VCLEFT_a584_doorRemoteUnlatchedRear m9 : 47|1@1+ (1,0) [0|0] "" Vector__XXX
 SG_ VCLEFT_a045_Task100msError m0 : 48|1@1+ (1,0) [0|0] "" Vector__XXX
 SG_ VCLEFT_a105_TAS_MIA m1 : 48|1@1+ (1,0) [0|0] "" Vector__XXX
 SG_ VCLEFT_a165_windowFactoryTest2 m2 : 48|1@1+ (1,0) [0|0] "" Vector__XXX
 SG_ VCLEFT_a225_seatEncStallBack m3 : 48|1@1+ (1,0) [0|0] "" Vector__XXX
 SG_ VCLEFT_a285_blowerChipComms m4 : 48|1@1+ (1,0) [0|0] "" Vector__XXX
 SG_ VCLEFT_a345_chargePortPowerCycling m5 : 48|1@1+ (1,0) [0|0] "" Vector__XXX
 SG_ VCLEFT_a525_LVBatterySWMisconfiguration m8 : 48|1@1+ (1,0) [0|0] "" Vector__XXX
 SG_ VCLEFT_a585_doorRemoteUnlatchFailedFront m9 : 48|1@1+ (1,0) [0|0] "" Vector__XXX
 SG_ VCLEFT_a046_Task1000msError m0 : 49|1@1+ (1,0) [0|0] "" Vector__XXX
 SG_ VCLEFT_a106_PCS_MIA m1 : 49|1@1+ (1,0) [0|0] "" Vector__XXX
 SG_ VCLEFT_a166_windowDebug m2 : 49|1@1+ (1,0) [0|0] "" Vector__XXX
 SG_ VCLEFT_a226_seatEncStallTilt m3 : 49|1@1+ (1,0) [0|0] "" Vector__XXX
 SG_ VCLEFT_a286_windowSpeedInvalidF m4 : 49|1@1+ (1,0) [0|0] "" Vector__XXX
 SG_ VCLEFT_a346_eFuseMgmtVbatFused2 m5 : 49|1@1+ (1,0) [0|0] "" Vector__XXX
 SG_ VCLEFT_a526_pcbaOverTemperature m8 : 49|1@1+ (1,0) [0|0] "" Vector__XXX
 SG_ VCLEFT_a586_doorRemoteUnlatchFailedRear m9 : 49|1@1+ (1,0) [0|0] "" Vector__XXX
 SG_ VCLEFT_a107_BMS_MIA m1 : 50|1@1+ (1,0) [0|0] "" Vector__XXX
 SG_ VCLEFT_a167_windowDebugPinchF m2 : 50|1@1+ (1,0) [0|0] "" Vector__XXX
 SG_ VCLEFT_a227_seatEncStallLift m3 : 50|1@1+ (1,0) [0|0] "" Vector__XXX
 SG_ VCLEFT_a287_windowSpeedInvalidR m4 : 50|1@1+ (1,0) [0|0] "" Vector__XXX
 SG_ VCLEFT_a347_nonContMonitorClearedDBG m5 : 50|1@1+ (1,0) [0|0] "" Vector__XXX
 SG_ VCLEFT_a527_continuousFeedUnexpectedVoltage m8 : 50|1@1+ (1,0) [0|0] "" Vector__XXX
 SG_ VCLEFT_a108_DIF_MIA m1 : 51|1@1+ (1,0) [0|0] "" Vector__XXX
 SG_ VCLEFT_a168_windowDebugPinchR m2 : 51|1@1+ (1,0) [0|0] "" Vector__XXX
 SG_ VCLEFT_a228_seatEncOverTrack m3 : 51|1@1+ (1,0) [0|0] "" Vector__XXX
 SG_ VCLEFT_a288_handlePWMPeriodF m4 : 51|1@1+ (1,0) [0|0] "" Vector__XXX
 SG_ VCLEFT_a348_CPSleepOvercurrent m5 : 51|1@1+ (1,0) [0|0] "" Vector__XXX
 SG_ VCLEFT_a528_unableToRunStuckOnTest m8 : 51|1@1+ (1,0) [0|0] "" Vector__XXX
 SG_ VCLEFT_a109_RCM_MIA m1 : 52|1@1+ (1,0) [0|0] "" Vector__XXX
 SG_ VCLEFT_a169_windowCurrentPeakF m2 : 52|1@1+ (1,0) [0|0] "" Vector__XXX
 SG_ VCLEFT_a229_seatEncOverBack m3 : 52|1@1+ (1,0) [0|0] "" Vector__XXX
 SG_ VCLEFT_a289_handlePWMPeriodR m4 : 52|1@1+ (1,0) [0|0] "" Vector__XXX
 SG_ VCLEFT_a349_CPSleepUndervoltage m5 : 52|1@1+ (1,0) [0|0] "" Vector__XXX
 SG_ VCLEFT_a110_GTW_MIA m1 : 53|1@1+ (1,0) [0|0] "" Vector__XXX
 SG_ VCLEFT_a170_windowCurrentPeakR m2 : 53|1@1+ (1,0) [0|0] "" Vector__XXX
 SG_ VCLEFT_a230_seatEncOverTilt m3 : 53|1@1+ (1,0) [0|0] "" Vector__XXX
 SG_ VCLEFT_a290_occupancyFaultedFront m4 : 53|1@1+ (1,0) [0|0] "" Vector__XXX
 SG_ VCLEFT_a350_ensOutOfRange m5 : 53|1@1+ (1,0) [0|0] "" Vector__XXX
 SG_ VCLEFT_a111_EPBR_MIA m1 : 54|1@1+ (1,0) [0|0] "" Vector__XXX
 SG_ VCLEFT_a231_seatEncOverLift m3 : 54|1@1+ (1,0) [0|0] "" Vector__XXX
 SG_ VCLEFT_a291_buckleFaultedFront m4 : 54|1@1+ (1,0) [0|0] "" Vector__XXX
 SG_ VCLEFT_a351_debugLiftgateCurrentSpike m5 : 54|1@1+ (1,0) [0|0] "" Vector__XXX
 SG_ VCLEFT_a112_EPBL_MIA m1 : 55|1@1+ (1,0) [0|0] "" Vector__XXX
 SG_ VCLEFT_a172_SPI_MIA m2 : 55|1@1+ (1,0) [0|0] "" Vector__XXX
 SG_ VCLEFT_a232_seatCurrUnderTrack m3 : 55|1@1+ (1,0) [0|0] "" Vector__XXX
 SG_ VCLEFT_a292_occupancyFaultedRearL m4 : 55|1@1+ (1,0) [0|0] "" Vector__XXX
 SG_ VCLEFT_a352_liftgateClosingLatchEntryFailed m5 : 55|1@1+ (1,0) [0|0] "" Vector__XXX
 SG_ VCLEFT_a113_UI_MIA m1 : 56|1@1+ (1,0) [0|0] "" Vector__XXX
 SG_ VCLEFT_a173_windowBtnDoorOpen m2 : 56|1@1+ (1,0) [0|0] "" Vector__XXX
 SG_ VCLEFT_a233_seatCurrUnderBack m3 : 56|1@1+ (1,0) [0|0] "" Vector__XXX
 SG_ VCLEFT_a293_occupancyFaultedRearC m4 : 56|1@1+ (1,0) [0|0] "" Vector__XXX
 SG_ VCLEFT_a353_eFuseMgmtSteeringColumn m5 : 56|1@1+ (1,0) [0|0] "" Vector__XXX
 SG_ VCLEFT_a114_ESP_MIA m1 : 57|1@1+ (1,0) [0|0] "" Vector__XXX
 SG_ VCLEFT_a234_seatCurrUnderTilt m3 : 57|1@1+ (1,0) [0|0] "" Vector__XXX
 SG_ VCLEFT_a294_occupancyFaultedRearR m4 : 57|1@1+ (1,0) [0|0] "" Vector__XXX
 SG_ VCLEFT_a354_eFuseMgmtLiftGate m5 : 57|1@1+ (1,0) [0|0] "" Vector__XXX
 SG_ VCLEFT_a115_VCSEC_MIA m1 : 58|1@1+ (1,0) [0|0] "" Vector__XXX
 SG_ VCLEFT_a175_windowSealDefectFront m2 : 58|1@1+ (1,0) [0|0] "" Vector__XXX
 SG_ VCLEFT_a235_seatCurrUnderLift m3 : 58|1@1+ (1,0) [0|0] "" Vector__XXX
 SG_ VCLEFT_a295_buckleFaultedRearL m4 : 58|1@1+ (1,0) [0|0] "" Vector__XXX
 SG_ VCLEFT_a355_liftgateUnexpectedStop m5 : 58|1@1+ (1,0) [0|0] "" Vector__XXX
 SG_ VCLEFT_a116_VCRIGHT_MIA m1 : 59|1@1+ (1,0) [0|0] "" Vector__XXX
 SG_ VCLEFT_a176_windowSealDefectRear m2 : 59|1@1+ (1,0) [0|0] "" Vector__XXX
 SG_ VCLEFT_a236_lumbarOverPresA m3 : 59|1@1+ (1,0) [0|0] "" Vector__XXX
 SG_ VCLEFT_a296_buckleFaultedRearC m4 : 59|1@1+ (1,0) [0|0] "" Vector__XXX
 SG_ VCLEFT_a356_liftgateFactoryTest m5 : 59|1@1+ (1,0) [0|0] "" Vector__XXX
 SG_ VCLEFT_a536_trunkFoldFlatSwitchFault m8 : 59|1@1+ (1,0) [0|0] "" Vector__XXX
 SG_ VCLEFT_a057_HVP_MIA m0 : 60|1@1+ (1,0) [0|0] "" Vector__XXX
 SG_ VCLEFT_a117_VCLEFT_MIA m1 : 60|1@1+ (1,0) [0|0] "" Vector__XXX
 SG_ VCLEFT_a237_lumbarOverPresB m3 : 60|1@1+ (1,0) [0|0] "" Vector__XXX
 SG_ VCLEFT_a297_seatBelowMinPumpTmp m4 : 60|1@1+ (1,0) [0|0] "" Vector__XXX
 SG_ VCLEFT_a357_liftgateUncalibrated m5 : 60|1@1+ (1,0) [0|0] "" Vector__XXX
 SG_ VCLEFT_a058_inputRHighSyncDebug m0 : 61|1@1+ (1,0) [0|0] "" Vector__XXX
 SG_ VCLEFT_a118_VCFRONT_MIA m1 : 61|1@1+ (1,0) [0|0] "" Vector__XXX
 SG_ VCLEFT_a238_lumbarValveMIA m3 : 61|1@1+ (1,0) [0|0] "" Vector__XXX
 SG_ VCLEFT_a358_debugLiftgateCurrentDropout m5 : 61|1@1+ (1,0) [0|0] "" Vector__XXX
 SG_ VCLEFT_a478_BPillarCameraHeaterFault m7 : 61|1@1+ (1,0) [0|0] "" Vector__XXX
 SG_ VCLEFT_a059_inputResistanceHigh m0 : 62|1@1+ (1,0) [0|0] "" Vector__XXX
 SG_ VCLEFT_a119_SCCM_MIA m1 : 62|1@1+ (1,0) [0|0] "" Vector__XXX
 SG_ VCLEFT_a239_seatHeatIFront m3 : 62|1@1+ (1,0) [0|0] "" Vector__XXX
 SG_ VCLEFT_a299_swcMIA m4 : 62|1@1+ (1,0) [0|0] "" Vector__XXX
 SG_ VCLEFT_a359_liftgateLatchExitNoPositionChange m5 : 62|1@1+ (1,0) [0|0] "" Vector__XXX
 SG_ VCLEFT_a599_LVBatteryTypeUnsupported m9 : 62|1@1+ (1,0) [0|0] "" Vector__XXX
 SG_ VCLEFT_a060_engineeringBuild m0 : 63|1@1+ (1,0) [0|0] "" Vector__XXX
 SG_ VCLEFT_a120_DI_DRIVE_MIA m1 : 63|1@1+ (1,0) [0|0] "" Vector__XXX
 SG_ VCLEFT_a180_frontDoorLatchRehome m2 : 63|1@1+ (1,0) [0|0] "" Vector__XXX
 SG_ VCLEFT_a240_seatHeatShortFront m3 : 63|1@1+ (1,0) [0|0] "" Vector__XXX
 SG_ VCLEFT_a300_swcUnderVoltage m4 : 63|1@1+ (1,0) [0|0] "" Vector__XXX
 SG_ VCLEFT_a360_detectedStationaryWhileMoving m5 : 63|1@1+ (1,0) [0|0] "" Vector__XXX
 SG_ VCLEFT_a480_vnf1048Fault m7 : 63|1@1+ (1,0) [0|0] "" Vector__XXX

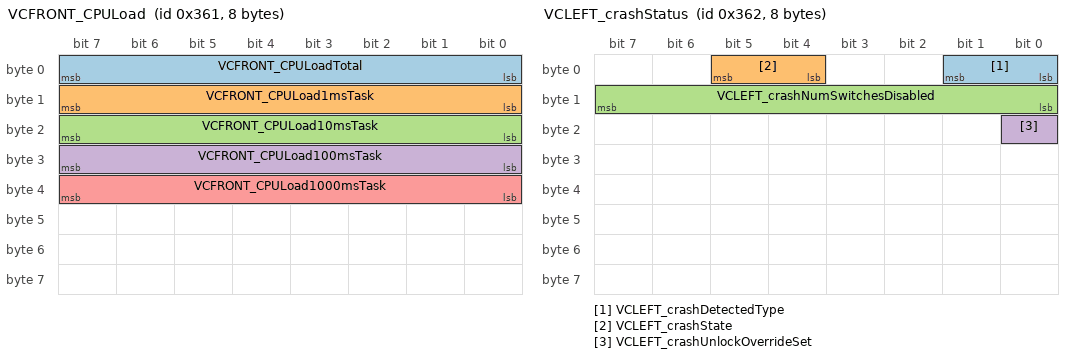
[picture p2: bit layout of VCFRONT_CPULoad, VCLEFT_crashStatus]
BO_ 865 VCFRONT_CPULoad: 8 Vector__XXX
 SG_ VCFRONT_CPULoadTotal : 0|8@1+ (1,0) [0|0] "" Vector__XXX
 SG_ VCFRONT_CPULoad1msTask : 8|8@1+ (1,0) [0|0] "" Vector__XXX
 SG_ VCFRONT_CPULoad10msTask : 16|8@1+ (1,0) [0|0] "" Vector__XXX
 SG_ VCFRONT_CPULoad100msTask : 24|8@1+ (1,0) [0|0] "" Vector__XXX
 SG_ VCFRONT_CPULoad1000msTask : 32|8@1+ (1,0) [0|0] "" Vector__XXX

BO_ 866 VCLEFT_crashStatus: 8 Vector__XXX
 SG_ VCLEFT_crashDetectedType : 0|2@1+ (1,0) [0|0] "" Vector__XXX
 SG_ VCLEFT_crashState : 4|2@1+ (1,0) [0|0] "" Vector__XXX
 SG_ VCLEFT_crashNumSwitchesDisabled : 8|8@1+ (1,0) [0|0] "" Vector__XXX
 SG_ VCLEFT_crashUnlockOverrideSet : 16|1@1+ (1,0) [0|0] "" Vector__XXX

BO_ 867 CMP_info: 8 Vector__XXX
 SG_ CMP_infoIndex M : 0|8@1+ (1,0) [0|0] "" Vector__XXX
 SG_ CMP_infoBootUdsProtoVersion m20 : 8|8@1+ (1,0) [0|0] "" Vector__XXX
 SG_ CMP_infoBuildType m10 : 8|8@1+ (1,0) [0|0] "" Vector__XXX
 SG_ CMP_infoPlatformType m13 : 8|8@1+ (1,0) [0|0] "" Vector__XXX
 SG_ CMP_infoBuildConfigId m10 : 16|16@1+ (1,0) [0|0] "" Vector__XXX
 SG_ CMP_infoPcbaId m11 : 16|8@1+ (1,0) [0|0] "" Vector__XXX
 SG_ CMP_infoAssemblyId m11 : 24|8@1+ (1,0) [0|0] "" Vector__XXX
 SG_ CMP_infoAppCrc m13 : 32|32@1+ (1,0) [0|0] "" Vector__XXX
 SG_ CMP_infoBootCrc m20 : 32|32@1+ (1,0) [0|0] "" Vector__XXX
 SG_ CMP_infoHardwareId m10 : 32|16@1+ (1,0) [0|0] "" Vector__XXX
 SG_ CMP_infoUsageId m11 : 32|16@1+ (1,0) [0|0] "" Vector__XXX
 SG_ CMP_infoComponentId m10 : 48|16@1+ (1,0) [0|0] "" Vector__XXX
 SG_ CMP_infoSubUsageId m11 : 48|16@1+ (1,0) [0|0] "" Vector__XXX

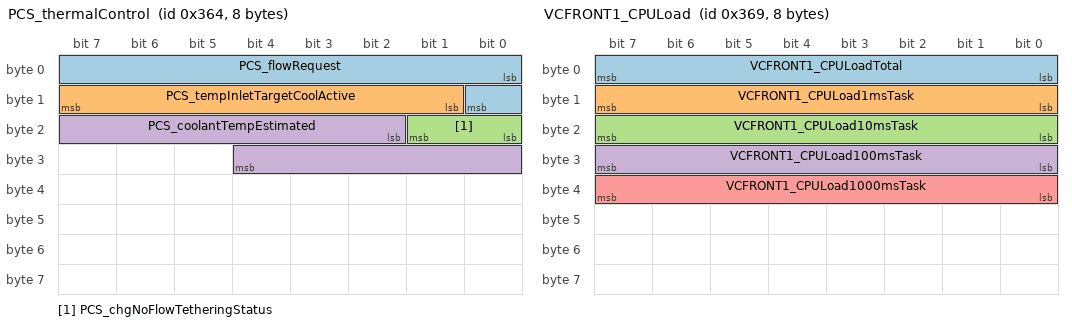
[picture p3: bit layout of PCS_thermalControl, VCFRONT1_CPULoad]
BO_ 868 PCS_thermalControl: 8 Vector__XXX
 SG_ PCS_flowRequest : 0|9@1+ (0.1,0) [0|0] "" Vector__XXX
 SG_ PCS_tempInletTargetCoolActive : 9|7@1+ (1,0) [0|0] "" Vector__XXX
 SG_ PCS_chgNoFlowTetheringStatus : 16|2@1+ (1,0) [0|0] "" Vector__XXX
 SG_ PCS_coolantTempEstimated : 18|11@1- (0.1,40) [0|0] "" Vector__XXX

BO_ 869 SCS_alertMatrix1: 8 Vector__XXX
 SG_ SCS_a001_hwDSPfault : 0|1@1+ (1,0) [0|0] "" Vector__XXX
 SG_ SCS_a002_hwIbatOC : 1|1@1+ (1,0) [0|0] "" Vector__XXX
 SG_ SCS_a003_hwCordOT : 2|1@1+ (1,0) [0|0] "" Vector__XXX
 SG_ SCS_a004_hwVbusOV : 3|1@1+ (1,0) [0|0] "" Vector__XXX
 SG_ SCS_a005_hwHVIL : 4|1@1+ (1,0) [0|0] "" Vector__XXX
 SG_ SCS_a006_hwWeld_V1 : 5|1@1+ (1,0) [0|0] "" Vector__XXX
 SG_ SCS_a007_hwWeld_V2 : 6|1@1+ (1,0) [0|0] "" Vector__XXX
 SG_ SCS_a008_hwIllegalCntrShoot : 7|1@1+ (1,0) [0|0] "" Vector__XXX
 SG_ SCS_a009_hwOpen_V1 : 8|1@1+ (1,0) [0|0] "" Vector__XXX
 SG_ SCS_a010_hwOpen_V2 : 9|1@1+ (1,0) [0|0] "" Vector__XXX
 SG_ SCS_a011_hwIllegalCntrCmdV1 : 10|1@1+ (1,0) [0|0] "" Vector__XXX
 SG_ SCS_a012_hwIllegalCntrCmdV2 : 11|1@1+ (1,0) [0|0] "" Vector__XXX
 SG_ SCS_a013_cordTempHiFoldBk : 12|1@1+ (1,0) [0|0] "" Vector__XXX
 SG_ SCS_a014_coolantTempHiFoldBk : 13|1@1+ (1,0) [0|0] "" Vector__XXX
 SG_ SCS_a015_cpldRationality : 14|1@1+ (1,0) [0|0] "" Vector__XXX
 SG_ SCS_a016_unusedHW16 : 15|1@1+ (1,0) [0|0] "" Vector__XXX
 SG_ SCS_a017_unusedHW17 : 16|1@1+ (1,0) [0|0] "" Vector__XXX
 SG_ SCS_a018_unusedHW18 : 17|1@1+ (1,0) [0|0] "" Vector__XXX
 SG_ SCS_a019_unusedHW19 : 18|1@1+ (1,0) [0|0] "" Vector__XXX
 SG_ SCS_a020_unusedHW20 : 19|1@1+ (1,0) [0|0] "" Vector__XXX
 SG_ SCS_a021_unusedHW21 : 20|1@1+ (1,0) [0|0] "" Vector__XXX
 SG_ SCS_a024_emergencyShutdown : 23|1@1+ (1,0) [0|0] "" Vector__XXX
 SG_ SCS_a025_internalIsolationFault : 24|1@1+ (1,0) [0|0] "" Vector__XXX
 SG_ SCS_a026_internalIsolationLow : 25|1@1+ (1,0) [0|0] "" Vector__XXX
 SG_ SCS_a027_externalIsolationLow : 26|1@1+ (1,0) [0|0] "" Vector__XXX
 SG_ SCS_a028_isolationRationality : 27|1@1+ (1,0) [0|0] "" Vector__XXX
 SG_ SCS_a029_VbatOV : 28|1@1+ (1,0) [0|0] "" Vector__XXX
 SG_ SCS_a030_VbusOV : 29|1@1+ (1,0) [0|0] "" Vector__XXX
 SG_ SCS_a031_IbatOC : 30|1@1+ (1,0) [0|0] "" Vector__XXX
 SG_ SCS_a032_VBatRationality : 31|1@1+ (1,0) [0|0] "" Vector__XXX
 SG_ SCS_a033_VBusRationality : 32|1@1+ (1,0) [0|0] "" Vector__XXX
 SG_ SCS_a034_IBatRationality : 33|1@1+ (1,0) [0|0] "" Vector__XXX
 SG_ SCS_a035_unexpectedVbusBehavior : 34|1@1+ (1,0) [0|0] "" Vector__XXX
 SG_ SCS_a036_internalContactorWelded : 35|1@1+ (1,0) [0|0] "" Vector__XXX
 SG_ SCS_a037_outputContactorWelded : 36|1@1+ (1,0) [0|0] "" Vector__XXX
 SG_ SCS_a038_contactorFailedOpen : 37|1@1+ (1,0) [0|0] "" Vector__XXX
 SG_ SCS_a039_ibatRegulation : 38|1@1+ (1,0) [0|0] "" Vector__XXX
 SG_ SCS_a040_plus12VOutOfRange : 39|1@1+ (1,0) [0|0] "" Vector__XXX
 SG_ SCS_a041_minus12VOutOfRange : 40|1@1+ (1,0) [0|0] "" Vector__XXX
 SG_ SCS_a042_pilotOutOfRange : 41|1@1+ (1,0) [0|0] "" Vector__XXX
 SG_ SCS_a043_pilotRationality : 42|1@1+ (1,0) [0|0] "" Vector__XXX
 SG_ SCS_a044_proximityRationality : 43|1@1+ (1,0) [0|0] "" Vector__XXX
 SG_ SCS_a045_pcbaOT : 44|1@1+ (1,0) [0|0] "" Vector__XXX
 SG_ SCS_a046_coolantOT : 45|1@1+ (1,0) [0|0] "" Vector__XXX
 SG_ SCS_a047_cordOT : 46|1@1+ (1,0) [0|0] "" Vector__XXX
 SG_ SCS_a048_ambientOT : 47|1@1+ (1,0) [0|0] "" Vector__XXX
 SG_ SCS_a049_pcbaTempRationality : 48|1@1+ (1,0) [0|0] "" Vector__XXX
 SG_ SCS_a050_coolantTempRationality : 49|1@1+ (1,0) [0|0] "" Vector__XXX
 SG_ SCS_a051_cordTempRationality : 50|1@1+ (1,0) [0|0] "" Vector__XXX
 SG_ SCS_a052_ambientTempRationality : 51|1@1+ (1,0) [0|0] "" Vector__XXX
 SG_ SCS_a053_unexpectedThermalBehavi : 52|1@1+ (1,0) [0|0] "" Vector__XXX
 SG_ SCS_a054_pumpRegulation : 53|1@1+ (1,0) [0|0] "" Vector__XXX
 SG_ SCS_a055_coolantLevelLow : 54|1@1+ (1,0) [0|0] "" Vector__XXX
 SG_ SCS_a056_stateTransitionDenied : 55|1@1+ (1,0) [0|0] "" Vector__XXX
 SG_ SCS_a057_watchdogReset : 56|1@1+ (1,0) [0|0] "" Vector__XXX
 SG_ SCS_a058_adcRef : 57|1@1+ (1,0) [0|0] "" Vector__XXX
 SG_ SCS_a059_memoryError : 58|1@1+ (1,0) [0|0] "" Vector__XXX
 SG_ SCS_a060_swHVIL : 59|1@1+ (1,0) [0|0] "" Vector__XXX
 SG_ SCS_a061_postOutOfService : 60|1@1+ (1,0) [0|0] "" Vector__XXX
 SG_ SCS_a062_unused : 61|1@1+ (1,0) [0|0] "" Vector__XXX
 SG_ SCS_a063_canRationality : 62|1@1+ (1,0) [0|0] "" Vector__XXX
 SG_ SCS_a064_vehicleCommandTimeout : 63|1@1+ (1,0) [0|0] "" Vector__XXX

BO_ 870 CMPD_info: 8 Vector__XXX
 SG_ CMPD_infoIndex M : 0|8@1+ (1,0) [0|0] "" Vector__XXX
 SG_ CMPD_infoBootUdsProtoVersion m20 : 8|8@1+ (1,0) [0|0] "" Vector__XXX
 SG_ CMPD_infoBuildType m10 : 8|8@1+ (1,0) [0|0] "" Vector__XXX
 SG_ CMPD_infoPlatformType m13 : 8|8@1+ (1,0) [0|0] "" Vector__XXX
 SG_ CMPD_infoBuildConfigId m10 : 16|16@1+ (1,0) [0|0] "" Vector__XXX
 SG_ CMPD_infoPcbaId m11 : 16|8@1+ (1,0) [0|0] "" Vector__XXX
 SG_ CMPD_infoAssemblyId m11 : 24|8@1+ (1,0) [0|0] "" Vector__XXX
 SG_ CMPD_infoBootCrc m20 : 32|32@1+ (1,0) [0|0] "" Vector__XXX
 SG_ CMPD_infoHardwareId m10 : 32|16@1+ (1,0) [0|0] "" Vector__XXX
 SG_ CMPD_infoUsageId m11 : 32|16@1+ (1,0) [0|0] "" Vector__XXX
 SG_ CMPD_infoAppCrc m13 : 39|32@0+ (1,0) [0|0] "" Vector__XXX
 SG_ CMPD_infoComponentId m10 : 48|16@1+ (1,0) [0|0] "" Vector__XXX
 SG_ CMPD_infoSubUsageId m11 : 48|16@1+ (1,0) [0|0] "" Vector__XXX

BO_ 871 DI_alertMatrix1: 8 Vector__XXX
 SG_ DI_a001_frunkSpeedLimitActive : 0|1@1+ (1,0) [0|0] "" Vector__XXX
 SG_ DI_a002_parkButtonDuringStalkReq : 1|1@1+ (1,0) [0|0] "" Vector__XXX
 SG_ DI_a005_stalkPanicked : 4|1@1+ (1,0) [0|0] "" Vector__XXX
 SG_ DI_a010_unintendedReset : 9|1@1+ (1,0) [0|0] "" Vector__XXX
 SG_ DI_a012_accel5VSupply : 11|1@1+ (1,0) [0|0] "" Vector__XXX
 SG_ DI_a013_eccError : 12|1@1+ (1,0) [0|0] "" Vector__XXX
 SG_ DI_a015_immobilizer : 14|1@1+ (1,0) [0|0] "" Vector__XXX
 SG_ DI_a016_parkRequestByPM : 15|1@1+ (1,0) [0|0] "" Vector__XXX
 SG_ DI_a017_hwPedalMonitor : 16|1@1+ (1,0) [0|0] "" Vector__XXX
 SG_ DI_a018_hwLVSupplyUV : 17|1@1+ (1,0) [0|0] "" Vector__XXX
 SG_ DI_a019_hwAccelPedalPower : 18|1@1+ (1,0) [0|0] "" Vector__XXX
 SG_ DI_a021_packOvervoltage : 20|1@1+ (1,0) [0|0] "" Vector__XXX
 SG_ DI_a022_hw5vSupplyUV : 21|1@1+ (1,0) [0|0] "" Vector__XXX
 SG_ DI_a023_carNotParked : 22|1@1+ (1,0) [0|0] "" Vector__XXX
 SG_ DI_a024_holdNForNeutral : 23|1@1+ (1,0) [0|0] "" Vector__XXX
 SG_ DI_a025_regenBackfillUnavailable : 24|1@1+ (1,0) [0|0] "" Vector__XXX
 SG_ DI_a026_parkPressedWithHighAPedal : 25|1@1+ (1,0) [0|0] "" Vector__XXX
 SG_ DI_a027_steeringAngleOffsetService : 26|1@1+ (1,0) [0|0] "" Vector__XXX
 SG_ DI_a031_closureAccelerationLimit : 30|1@1+ (1,0) [0|0] "" Vector__XXX
 SG_ DI_a036_sysStandbyUnitLimitedWait : 35|1@1+ (1,0) [0|0] "" Vector__XXX
 SG_ DI_a040_difMIA : 39|1@1+ (1,0) [0|0] "" Vector__XXX
 SG_ DI_a041_driverBrakeApplyStuck : 40|1@1+ (1,0) [0|0] "" Vector__XXX
 SG_ DI_a042_pmfMIA : 41|1@1+ (1,0) [0|0] "" Vector__XXX
 SG_ DI_a043_pmrMIA : 42|1@1+ (1,0) [0|0] "" Vector__XXX
 SG_ DI_a048_ecuLogAvailable : 47|1@1+ (1,0) [0|0] "" Vector__XXX
 SG_ DI_a051_batteryOvercurrent : 50|1@1+ (1,0) [0|0] "" Vector__XXX
 SG_ DI_a052_dirMIA : 51|1@1+ (1,0) [0|0] "" Vector__XXX
 SG_ DI_a053_canDataBusC : 52|1@1+ (1,0) [0|0] "" Vector__XXX
 SG_ DI_a054_canOverrunBusC : 53|1@1+ (1,0) [0|0] "" Vector__XXX
 SG_ DI_a055_canHardwareBusC : 54|1@1+ (1,0) [0|0] "" Vector__XXX
 SG_ DI_a056_canDataBusD : 55|1@1+ (1,0) [0|0] "" Vector__XXX
 SG_ DI_a057_canOverrunBusD : 56|1@1+ (1,0) [0|0] "" Vector__XXX
 SG_ DI_a058_canHardwareBusD : 57|1@1+ (1,0) [0|0] "" Vector__XXX
 SG_ DI_a059_canDataBusE : 58|1@1+ (1,0) [0|0] "" Vector__XXX
 SG_ DI_a060_canOverrunBusE : 59|1@1+ (1,0) [0|0] "" Vector__XXX
 SG_ DI_a061_canHardwareBusE : 60|1@1+ (1,0) [0|0] "" Vector__XXX
 SG_ DI_a062_systemLimpMode : 61|1@1+ (1,0) [0|0] "" Vector__XXX
 SG_ DI_a063_systemGracefulPowerOff : 62|1@1+ (1,0) [0|0] "" Vector__XXX
 SG_ DI_a064_pmsrmUnitMiaWithHvDown : 63|1@1+ (1,0) [0|0] "" Vector__XXX

BO_ 872 DI_alertMatrix2: 8 Vector__XXX
 SG_ DI_a065_canHardwareBusB : 0|1@1+ (1,0) [0|0] "" Vector__XXX
 SG_ DI_a066_canDataBusB : 1|1@1+ (1,0) [0|0] "" Vector__XXX
 SG_ DI_a067_canOverrunBusB : 2|1@1+ (1,0) [0|0] "" Vector__XXX
 SG_ DI_a068_secondaryWheelSpeedIrrational : 3|1@1+ (1,0) [0|0] "" Vector__XXX
 SG_ DI_a070_udsTransactionInitiated : 5|1@1+ (1,0) [0|0] "" Vector__XXX
 SG_ DI_a076_lvSupplyOV : 11|1@1+ (1,0) [0|0] "" Vector__XXX
 SG_ DI_a077_lvSupplyUV : 12|1@1+ (1,0) [0|0] "" Vector__XXX
 SG_ DI_a078_adcRefLow : 13|1@1+ (1,0) [0|0] "" Vector__XXX
 SG_ DI_a079_adcRefHigh : 14|1@1+ (1,0) [0|0] "" Vector__XXX
 SG_ DI_a080_accelSynch : 15|1@1+ (1,0) [0|0] "" Vector__XXX
 SG_ DI_a081_accelTrack1 : 16|1@1+ (1,0) [0|0] "" Vector__XXX
 SG_ DI_a082_accelTrack2 : 17|1@1+ (1,0) [0|0] "" Vector__XXX
 SG_ DI_a083_brakePedalSensor : 18|1@1+ (1,0) [0|0] "" Vector__XXX
 SG_ DI_a084_eccTestData0 : 19|1@1+ (1,0) [0|0] "" Vector__XXX
 SG_ DI_a085_proximityInEnable : 20|1@1+ (1,0) [0|0] "" Vector__XXX
 SG_ DI_a087_gtwMIA : 22|1@1+ (1,0) [0|0] "" Vector__XXX
 SG_ DI_a088_uiMIA : 23|1@1+ (1,0) [0|0] "" Vector__XXX
 SG_ DI_a089_sccmMIA : 24|1@1+ (1,0) [0|0] "" Vector__XXX
 SG_ DI_a090_pmMIA : 25|1@1+ (1,0) [0|0] "" Vector__XXX
 SG_ DI_a091_espMIA : 26|1@1+ (1,0) [0|0] "" Vector__XXX
 SG_ DI_a092_bmsMIA : 27|1@1+ (1,0) [0|0] "" Vector__XXX
 SG_ DI_a093_canHardwareBusA : 28|1@1+ (1,0) [0|0] "" Vector__XXX
 SG_ DI_a094_canDataBusA : 29|1@1+ (1,0) [0|0] "" Vector__XXX
 SG_ DI_a095_canOverrunBusA : 30|1@1+ (1,0) [0|0] "" Vector__XXX
 SG_ DI_a096_memoryError : 31|1@1+ (1,0) [0|0] "" Vector__XXX
 SG_ DI_a097_eepromError : 32|1@1+ (1,0) [0|0] "" Vector__XXX
 SG_ DI_a098_eepromManagerError : 33|1@1+ (1,0) [0|0] "" Vector__XXX
 SG_ DI_a099_threadOverrun : 34|1@1+ (1,0) [0|0] "" Vector__XXX
 SG_ DI_a100_nvramError : 35|1@1+ (1,0) [0|0] "" Vector__XXX
 SG_ DI_a101_eccTestData1 : 36|1@1+ (1,0) [0|0] "" Vector__XXX
 SG_ DI_a104_proximityIrrational : 39|1@1+ (1,0) [0|0] "" Vector__XXX
 SG_ DI_a105_cpMIA : 40|1@1+ (1,0) [0|0] "" Vector__XXX
 SG_ DI_a108_appMIA : 43|1@1+ (1,0) [0|0] "" Vector__XXX
 SG_ DI_a110_brakeMIA : 45|1@1+ (1,0) [0|0] "" Vector__XXX
 SG_ DI_a112_accelTrack1Incons : 47|1@1+ (1,0) [0|0] "" Vector__XXX
 SG_ DI_a113_lowBrakeMCPressure : 48|1@1+ (1,0) [0|0] "" Vector__XXX
 SG_ DI_a118_diImmobilizedForFactoryFailsafe : 53|1@1+ (1,0) [0|0] "" Vector__XXX
 SG_ DI_a122_highStackUsage : 57|1@1+ (1,0) [0|0] "" Vector__XXX
 SG_ DI_a124_cruiseFault : 59|1@1+ (1,0) [0|0] "" Vector__XXX
 SG_ DI_a125_noBatteryPower : 60|1@1+ (1,0) [0|0] "" Vector__XXX

BO_ 873 VCFRONT1_CPULoad: 8 Vector__XXX
 SG_ VCFRONT1_CPULoadTotal : 0|8@1+ (1,0) [0|0] "" Vector__XXX
 SG_ VCFRONT1_CPULoad1msTask : 8|8@1+ (1,0) [0|0] "" Vector__XXX
 SG_ VCFRONT1_CPULoad10msTask : 16|8@1+ (1,0) [0|0] "" Vector__XXX
 SG_ VCFRONT1_CPULoad100msTask : 24|8@1+ (1,0) [0|0] "" Vector__XXX
 SG_ VCFRONT1_CPULoad1000msTask : 32|8@1+ (1,0) [0|0] "" Vector__XXX

BO_ 875 DI_alertMatrix3: 8 Vector__XXX
 SG_ DI_a129_epbNotApplied : 0|1@1+ (1,0) [0|0] "" Vector__XXX
 SG_ DI_a130_aebFault : 1|1@1+ (1,0) [0|0] "" Vector__XXX
 SG_ DI_a131_highSpeedWearLimit : 2|1@1+ (1,0) [0|0] "" Vector__XXX
 SG_ DI_a133_vehicleHoldTimedOut : 4|1@1+ (1,0) [0|0] "" Vector__XXX
 SG_ DI_a134_wheelSpeedIrrational : 5|1@1+ (1,0) [0|0] "" Vector__XXX
 SG_ DI_a135_vehicleHoldFault : 6|1@1+ (1,0) [0|0] "" Vector__XXX
 SG_ DI_a137_noCapableDriveUnits : 8|1@1+ (1,0) [0|0] "" Vector__XXX
 SG_ DI_a138_frontUnitDisabled : 9|1@1+ (1,0) [0|0] "" Vector__XXX
 SG_ DI_a139_rearUnitDisabled : 10|1@1+ (1,0) [0|0] "" Vector__XXX
 SG_ DI_a140_ptcMIA : 11|1@1+ (1,0) [0|0] "" Vector__XXX
 SG_ DI_a141_dasMIA : 12|1@1+ (1,0) [0|0] "" Vector__XXX
 SG_ DI_a142_potholeDetected : 13|1@1+ (1,0) [0|0] "" Vector__XXX
 SG_ DI_a143_mcuLimitActive : 14|1@1+ (1,0) [0|0] "" Vector__XXX
 SG_ DI_a144_configMismatch : 15|1@1+ (1,0) [0|0] "" Vector__XXX
 SG_ DI_a146_pbrkPanicEpbFault : 17|1@1+ (1,0) [0|0] "" Vector__XXX
 SG_ DI_a154_vdcRearSteering : 25|1@1+ (1,0) [0|0] "" Vector__XXX
 SG_ DI_a155_vcfrontMIA : 26|1@1+ (1,0) [0|0] "" Vector__XXX
 SG_ DI_a157_rcmMIA : 28|1@1+ (1,0) [0|0] "" Vector__XXX
 SG_ DI_a158_ibstMIA : 29|1@1+ (1,0) [0|0] "" Vector__XXX
 SG_ DI_a159_cruiseSelfCheck : 30|1@1+ (1,0) [0|0] "" Vector__XXX
 SG_ DI_a160_fastLearnComplete : 31|1@1+ (1,0) [0|0] "" Vector__XXX
 SG_ DI_a161_epas3pMIA : 32|1@1+ (1,0) [0|0] "" Vector__XXX
 SG_ DI_a162_shiftDenied : 33|1@1+ (1,0) [0|0] "" Vector__XXX
 SG_ DI_a163_shiftMotorSpeed : 34|1@1+ (1,0) [0|0] "" Vector__XXX
 SG_ DI_a164_brakeOverride : 35|1@1+ (1,0) [0|0] "" Vector__XXX
 SG_ DI_a165_cruiseCancelled : 36|1@1+ (1,0) [0|0] "" Vector__XXX
 SG_ DI_a166_driverLeft : 37|1@1+ (1,0) [0|0] "" Vector__XXX
 SG_ DI_a167_keyNotAuthenticated : 38|1@1+ (1,0) [0|0] "" Vector__XXX
 SG_ DI_a168_proximityDriveDenial : 39|1@1+ (1,0) [0|0] "" Vector__XXX
 SG_ DI_a169_regenOffOverride : 40|1@1+ (1,0) [0|0] "" Vector__XXX
 SG_ DI_a170_tireConfigUpdated : 41|1@1+ (1,0) [0|0] "" Vector__XXX
 SG_ DI_a171_driveRailNotRequested : 42|1@1+ (1,0) [0|0] "" Vector__XXX
 SG_ DI_a172_accelPressedInNP : 43|1@1+ (1,0) [0|0] "" Vector__XXX
 SG_ DI_a173_bothPedalsPressed : 44|1@1+ (1,0) [0|0] "" Vector__XXX
 SG_ DI_a174_notOkToStartDrive : 45|1@1+ (1,0) [0|0] "" Vector__XXX
 SG_ DI_a175_crsNotAvailable : 46|1@1+ (1,0) [0|0] "" Vector__XXX
 SG_ DI_a176_EBRreleased : 47|1@1+ (1,0) [0|0] "" Vector__XXX
 SG_ DI_a177_tireFitmentChanged : 48|1@1+ (1,0) [0|0] "" Vector__XXX
 SG_ DI_a178_steeringAngleOffsetFault : 49|1@1+ (1,0) [0|0] "" Vector__XXX
 SG_ DI_a179_steeringAngleOffsetWarning : 50|1@1+ (1,0) [0|0] "" Vector__XXX
 SG_ DI_a180_crsSeatbeltUnbuckled : 51|1@1+ (1,0) [0|0] "" Vector__XXX
 SG_ DI_a181_rearMotorMode : 52|1@1+ (1,0) [0|0] "" Vector__XXX
 SG_ DI_a182_frontMotorMode : 53|1@1+ (1,0) [0|0] "" Vector__XXX
 SG_ DI_a183_holdReleaseRqrd : 54|1@1+ (1,0) [0|0] "" Vector__XXX
 SG_ DI_a184_autoparkCanceled : 55|1@1+ (1,0) [0|0] "" Vector__XXX
 SG_ DI_a185_autoparkAborted : 56|1@1+ (1,0) [0|0] "" Vector__XXX
 SG_ DI_a186_brakeStand : 57|1@1+ (1,0) [0|0] "" Vector__XXX
 SG_ DI_a187_pedalMisapplication : 58|1@1+ (1,0) [0|0] "" Vector__XXX
 SG_ DI_a188_tireRotationRecommendedGhosted : 59|1@1+ (1,0) [0|0] "" Vector__XXX
 SG_ DI_a189_garageShiftWithPedal : 60|1@1+ (1,0) [0|0] "" Vector__XXX
 SG_ DI_a190_tireRotationRecommended : 61|1@1+ (1,0) [0|0] "" Vector__XXX
 SG_ DI_a191_brakeShiftReq : 62|1@1+ (1,0) [0|0] "" Vector__XXX
 SG_ DI_a192_invalidOdometer : 63|1@1+ (1,0) [0|0] "" Vector__XXX

BO_ 878 DI_alertMatrix4: 8 Vector__XXX
 SG_ DI_a193_vdcBrakeTorqueFr : 0|1@1+ (1,0) [0|0] "" Vector__XXX
 SG_ DI_a194_vdcBrakeTorqueRe : 1|1@1+ (1,0) [0|0] "" Vector__XXX
 SG_ DI_a195_vdcEspSlipFr : 2|1@1+ (1,0) [0|0] "" Vector__XXX
 SG_ DI_a196_vdcEspSlipRe : 3|1@1+ (1,0) [0|0] "" Vector__XXX
 SG_ DI_a197_vdcEspWheelSaturations : 4|1@1+ (1,0) [0|0] "" Vector__XXX
 SG_ DI_a198_vdcEspMCPressAndSteering : 5|1@1+ (1,0) [0|0] "" Vector__XXX
 SG_ DI_a199_vdcFaulted : 6|1@1+ (1,0) [0|0] "" Vector__XXX
 SG_ DI_a200_vdcModelBasedPlausibility : 7|1@1+ (1,0) [0|0] "" Vector__XXX
 SG_ DI_a201_decelTorqueLimited : 8|1@1+ (1,0) [0|0] "" Vector__XXX
 SG_ DI_a202_excessHeatUnavailable : 9|1@1+ (1,0) [0|0] "" Vector__XXX
 SG_ DI_a203_TCReducedByADD : 10|1@1+ (1,0) [0|0] "" Vector__XXX
 SG_ DI_a204_vdcRcmLongitudinal : 11|1@1+ (1,0) [0|0] "" Vector__XXX
 SG_ DI_a205_vdcRcmLateral : 12|1@1+ (1,0) [0|0] "" Vector__XXX
 SG_ DI_a206_vdcRcmVertical : 13|1@1+ (1,0) [0|0] "" Vector__XXX
 SG_ DI_a207_vdcPowertrainTorque_dif : 14|1@1+ (1,0) [0|0] "" Vector__XXX
 SG_ DI_a208_vdcPowertrainTorque_dir : 15|1@1+ (1,0) [0|0] "" Vector__XXX
 SG_ DI_a210_vdcOtherControllerStates : 17|1@1+ (1,0) [0|0] "" Vector__XXX
 SG_ DI_a211_vdcMotorSpeed_dif : 18|1@1+ (1,0) [0|0] "" Vector__XXX
 SG_ DI_a212_vdcWheelRotations : 19|1@1+ (1,0) [0|0] "" Vector__XXX
 SG_ DI_a213_lowMuProbabilityChange : 20|1@1+ (1,0) [0|0] "" Vector__XXX
 SG_ DI_a214_vdcWheelSpeedFr : 21|1@1+ (1,0) [0|0] "" Vector__XXX
 SG_ DI_a215_vdcWheelSpeedRe : 22|1@1+ (1,0) [0|0] "" Vector__XXX
 SG_ DI_a216_vdcMBPAlmostTripped : 23|1@1+ (1,0) [0|0] "" Vector__XXX
 SG_ DI_a217_vdcOutputIrrational : 24|1@1+ (1,0) [0|0] "" Vector__XXX
 SG_ DI_a218_vdcOSPreControlActive : 25|1@1+ (1,0) [0|0] "" Vector__XXX
 SG_ DI_a219_vdcOversteerdMzActive : 26|1@1+ (1,0) [0|0] "" Vector__XXX
 SG_ DI_a220_vdcUndersteerDecelActive : 27|1@1+ (1,0) [0|0] "" Vector__XXX
 SG_ DI_a221_vdcUndersteerdMzActive : 28|1@1+ (1,0) [0|0] "" Vector__XXX
 SG_ DI_a222_vdcDisabled : 29|1@1+ (1,0) [0|0] "" Vector__XXX
 SG_ DI_a223_tractionControlDisabled : 30|1@1+ (1,0) [0|0] "" Vector__XXX
 SG_ DI_a224_brakeOverTemp : 31|1@1+ (1,0) [0|0] "" Vector__XXX
 SG_ DI_a226_sysStartConditionNotMet : 33|1@1+ (1,0) [0|0] "" Vector__XXX
 SG_ DI_a227_contactorsNotClosed : 34|1@1+ (1,0) [0|0] "" Vector__XXX
 SG_ DI_a228_brakeTempEstUnavailable : 35|1@1+ (1,0) [0|0] "" Vector__XXX
 SG_ DI_a230_cmpMIA : 37|1@1+ (1,0) [0|0] "" Vector__XXX
 SG_ DI_a231_softSystemLimpMode : 38|1@1+ (1,0) [0|0] "" Vector__XXX
 SG_ DI_a232_velocityEstimatorDegraded : 39|1@1+ (1,0) [0|0] "" Vector__XXX
 SG_ DI_a233_frontWheelImpactDetected : 40|1@1+ (1,0) [0|0] "" Vector__XXX
 SG_ DI_a235_trackModeActive : 42|1@1+ (1,0) [0|0] "" Vector__XXX
 SG_ DI_a236_tasMIA : 43|1@1+ (1,0) [0|0] "" Vector__XXX
 SG_ DI_a237_undersideAbuse : 44|1@1+ (1,0) [0|0] "" Vector__XXX
 SG_ DI_a238_secondaryCollisionMitigationActive : 45|1@1+ (1,0) [0|0] "" Vector__XXX
 SG_ DI_a239_neutralRequestByPM : 46|1@1+ (1,0) [0|0] "" Vector__XXX
 SG_ DI_a240_torqueSplitStuck : 47|1@1+ (1,0) [0|0] "" Vector__XXX
 SG_ DI_a241_vdcMotorSpeed_dir : 48|1@1+ (1,0) [0|0] "" Vector__XXX
 SG_ DI_a242_vdcTrailerSwayDetected : 49|1@1+ (1,0) [0|0] "" Vector__XXX
 SG_ DI_a244_vseRLSMassMismatch : 51|1@1+ (1,0) [0|0] "" Vector__XXX
 SG_ DI_a245_opdReducedWithoutEbr : 52|1@1+ (1,0) [0|0] "" Vector__XXX
 SG_ DI_a246_opdUnavailable : 53|1@1+ (1,0) [0|0] "" Vector__XXX
 SG_ DI_a248_vdcPreControlHighDynamicActive : 55|1@1+ (1,0) [0|0] "" Vector__XXX
 SG_ DI_a249_spinDownLearningInProgress : 56|1@1+ (1,0) [0|0] "" Vector__XXX
 SG_ DI_a250_tasSpeedLimitActive : 57|1@1+ (1,0) [0|0] "" Vector__XXX
 SG_ DI_a251_diPowerOnStateMismatch : 58|1@1+ (1,0) [0|0] "" Vector__XXX
 SG_ DI_a253_accelSynchWarn : 60|1@1+ (1,0) [0|0] "" Vector__XXX
 SG_ DI_a254_vehicleStuckDetected : 61|1@1+ (1,0) [0|0] "" Vector__XXX

BO_ 880 SCS_alertMatrix2: 8 Vector__XXX
 SG_ SCS_a065_vBatRationalityStage1 : 0|1@1+ (1,0) [0|0] "" Vector__XXX
 SG_ SCS_a066_vBatRationalityStage2 : 1|1@1+ (1,0) [0|0] "" Vector__XXX
 SG_ SCS_a067_vBatRationalityStage3 : 2|1@1+ (1,0) [0|0] "" Vector__XXX
 SG_ SCS_a068_vBatRationalityStage4 : 3|1@1+ (1,0) [0|0] "" Vector__XXX
 SG_ SCS_a069_vStageRationalityV1 : 4|1@1+ (1,0) [0|0] "" Vector__XXX
 SG_ SCS_a070_vStageRationalityV2 : 5|1@1+ (1,0) [0|0] "" Vector__XXX
 SG_ SCS_a071_chargerMIA : 6|1@1+ (1,0) [0|0] "" Vector__XXX
 SG_ SCS_a072_gtwMIA : 7|1@1+ (1,0) [0|0] "" Vector__XXX
 SG_ SCS_a073_lccMIA : 8|1@1+ (1,0) [0|0] "" Vector__XXX
 SG_ SCS_a074_isoVDiffHi : 9|1@1+ (1,0) [0|0] "" Vector__XXX
 SG_ SCS_a075_unused75 : 10|1@1+ (1,0) [0|0] "" Vector__XXX
 SG_ SCS_a076_bmsMIA : 11|1@1+ (1,0) [0|0] "" Vector__XXX
 SG_ SCS_a077_unexpectedVbatBehavior : 12|1@1+ (1,0) [0|0] "" Vector__XXX
 SG_ SCS_a078_voltageMatchTimeout : 13|1@1+ (1,0) [0|0] "" Vector__XXX
 SG_ SCS_a079_unexpectedVbat : 14|1@1+ (1,0) [0|0] "" Vector__XXX
 SG_ SCS_a080_lccFaulted : 15|1@1+ (1,0) [0|0] "" Vector__XXX
 SG_ SCS_a081_rmsInputVoltageHigh : 16|1@1+ (1,0) [0|0] "" Vector__XXX
 SG_ SCS_a082_VbatUV : 17|1@1+ (1,0) [0|0] "" Vector__XXX
 SG_ SCS_a083_chargeCurrentLimited : 18|1@1+ (1,0) [0|0] "" Vector__XXX
 SG_ SCS_a084_unused84 : 19|1@1+ (1,0) [0|0] "" Vector__XXX
 SG_ SCS_a085_unused85 : 20|1@1+ (1,0) [0|0] "" Vector__XXX
 SG_ SCS_a086_lccResetDetected : 21|1@1+ (1,0) [0|0] "" Vector__XXX
 SG_ SCS_a087_posCordTempRationality : 22|1@1+ (1,0) [0|0] "" Vector__XXX
 SG_ SCS_a088_negCordTempRationality : 23|1@1+ (1,0) [0|0] "" Vector__XXX
 SG_ SCS_a089_posCordOT : 24|1@1+ (1,0) [0|0] "" Vector__XXX
 SG_ SCS_a090_negCordOT : 25|1@1+ (1,0) [0|0] "" Vector__XXX
 SG_ SCS_a091_voltageRiseDetection : 26|1@1+ (1,0) [0|0] "" Vector__XXX
 SG_ SCS_a092_cabEnableDeasserted : 27|1@1+ (1,0) [0|0] "" Vector__XXX
 SG_ SCS_a093_unused93 : 28|1@1+ (1,0) [0|0] "" Vector__XXX
 SG_ SCS_a094_unused94 : 29|1@1+ (1,0) [0|0] "" Vector__XXX
 SG_ SCS_a095_unused95 : 30|1@1+ (1,0) [0|0] "" Vector__XXX
 SG_ SCS_a096_unused96 : 31|1@1+ (1,0) [0|0] "" Vector__XXX
 SG_ SCS_a097_unused97 : 32|1@1+ (1,0) [0|0] "" Vector__XXX
 SG_ SCS_a098_unused98 : 33|1@1+ (1,0) [0|0] "" Vector__XXX
 SG_ SCS_a099_unused99 : 34|1@1+ (1,0) [0|0] "" Vector__XXX
 SG_ SCS_a100_unused100 : 35|1@1+ (1,0) [0|0] "" Vector__XXX
 SG_ SCS_a101_unused101 : 36|1@1+ (1,0) [0|0] "" Vector__XXX
 SG_ SCS_a102_unused102 : 37|1@1+ (1,0) [0|0] "" Vector__XXX
 SG_ SCS_a103_unused103 : 38|1@1+ (1,0) [0|0] "" Vector__XXX
 SG_ SCS_a104_unused104 : 39|1@1+ (1,0) [0|0] "" Vector__XXX
 SG_ SCS_a105_unused105 : 40|1@1+ (1,0) [0|0] "" Vector__XXX
 SG_ SCS_a106_unused106 : 41|1@1+ (1,0) [0|0] "" Vector__XXX
 SG_ SCS_a107_unused107 : 42|1@1+ (1,0) [0|0] "" Vector__XXX
 SG_ SCS_a108_unused108 : 43|1@1+ (1,0) [0|0] "" Vector__XXX
 SG_ SCS_a109_unused109 : 44|1@1+ (1,0) [0|0] "" Vector__XXX
 SG_ SCS_a110_unused110 : 45|1@1+ (1,0) [0|0] "" Vector__XXX
 SG_ SCS_a111_unused111 : 46|1@1+ (1,0) [0|0] "" Vector__XXX
 SG_ SCS_a112_unused112 : 47|1@1+ (1,0) [0|0] "" Vector__XXX
 SG_ SCS_a113_unused113 : 48|1@1+ (1,0) [0|0] "" Vector__XXX
 SG_ SCS_a114_unused114 : 49|1@1+ (1,0) [0|0] "" Vector__XXX
 SG_ SCS_a115_unused115 : 50|1@1+ (1,0) [0|0] "" Vector__XXX
 SG_ SCS_a116_unused116 : 51|1@1+ (1,0) [0|0] "" Vector__XXX
 SG_ SCS_a117_unused117 : 52|1@1+ (1,0) [0|0] "" Vector__XXX
 SG_ SCS_a118_unused118 : 53|1@1+ (1,0) [0|0] "" Vector__XXX
 SG_ SCS_a119_unused119 : 54|1@1+ (1,0) [0|0] "" Vector__XXX
 SG_ SCS_a120_unused120 : 55|1@1+ (1,0) [0|0] "" Vector__XXX
 SG_ SCS_a121_unused121 : 56|1@1+ (1,0) [0|0] "" Vector__XXX
 SG_ SCS_a122_unused122 : 57|1@1+ (1,0) [0|0] "" Vector__XXX
 SG_ SCS_a123_unused123 : 58|1@1+ (1,0) [0|0] "" Vector__XXX
 SG_ SCS_a124_unused124 : 59|1@1+ (1,0) [0|0] "" Vector__XXX
 SG_ SCS_a125_unused125 : 60|1@1+ (1,0) [0|0] "" Vector__XXX
 SG_ SCS_a126_unused126 : 61|1@1+ (1,0) [0|0] "" Vector__XXX
 SG_ SCS_a127_unused127 : 62|1@1+ (1,0) [0|0] "" Vector__XXX
 SG_ SCS_a128_unused128 : 63|1@1+ (1,0) [0|0] "" Vector__XXX

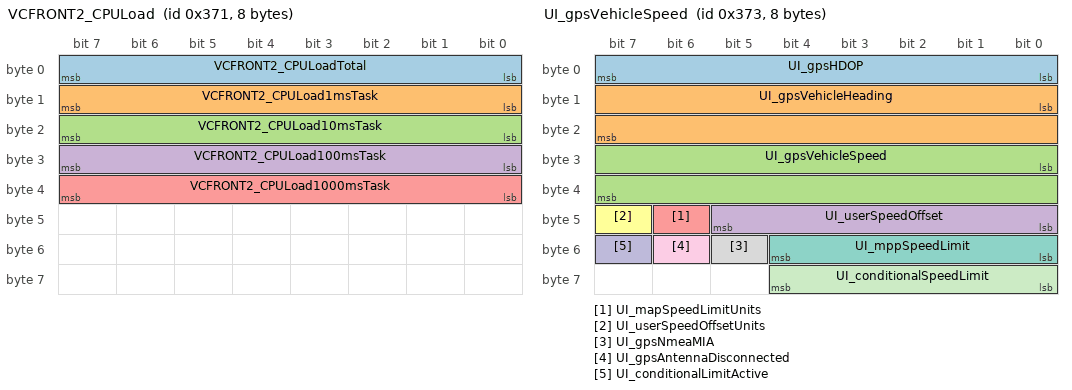
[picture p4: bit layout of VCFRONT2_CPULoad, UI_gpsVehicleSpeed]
BO_ 881 VCFRONT2_CPULoad: 8 Vector__XXX
 SG_ VCFRONT2_CPULoadTotal : 0|8@1+ (1,0) [0|0] "" Vector__XXX
 SG_ VCFRONT2_CPULoad1msTask : 8|8@1+ (1,0) [0|0] "" Vector__XXX
 SG_ VCFRONT2_CPULoad10msTask : 16|8@1+ (1,0) [0|0] "" Vector__XXX
 SG_ VCFRONT2_CPULoad100msTask : 24|8@1+ (1,0) [0|0] "" Vector__XXX
 SG_ VCFRONT2_CPULoad1000msTask : 32|8@1+ (1,0) [0|0] "" Vector__XXX

BO_ 882 BMS_log1: 8 Vector__XXX
 SG_ BMS_log1MuxId M : 0|8@1+ (1,0) [0|0] "" Vector__XXX
 SG_ BMS_1HzTask_cpuUsage m0 : 8|14@1+ (0.01,0) [0|0] "" Vector__XXX
 SG_ BMS_appIdleTask_cpuUsage m2 : 8|14@1+ (0.01,0) [0|0] "" Vector__XXX
 SG_ BMS_avgSleepCurrent m12 : 8|15@1- (0.2,0) [0|0] "" Vector__XXX
 SG_ BMS_balanceState m3 : 8|4@1+ (1,0) [0|0] "" Vector__XXX
 SG_ BMS_chgEndEvseChargeType m9 : 8|2@1+ (1,0) [0|0] "" Vector__XXX
 SG_ BMS_chgTerminationVMode m10 : 8|1@1+ (1,0) [0|0] "" Vector__XXX
 SG_ BMS_cpuLoad m1 : 8|14@1+ (0.01,0) [0|0] "" Vector__XXX
 SG_ BMS_dcChargeVoltageLimit m5 : 8|12@1+ (0.14650226075946277,0) [0|0] "" Vector__XXX
 SG_ BMS_energyMaxPredictedBrickTemp m13 : 8|8@1+ (1,-50) [0|0] "" Vector__XXX
 SG_ BMS_energyWalkMaxPackCurrent m14 : 8|16@1- (0.1,0) [0|0] "" Vector__XXX
 SG_ BMS_minModeledPackTemp m6 : 8|11@1+ (0.1,-50) [0|0] "" Vector__XXX
 SG_ BMS_modeledThermistorTemp1 m7 : 8|11@1+ (0.1,-50) [0|0] "" Vector__XXX
 SG_ BMS_modeledThermistorTemp6 m8 : 8|11@1+ (0.1,-50) [0|0] "" Vector__XXX
 SG_ BMS_packPower m11 : 8|16@1- (0.02,0) [0|0] "" Vector__XXX
 SG_ BMS_chgPhase m10 : 9|2@1+ (1,0) [0|0] "" Vector__XXX
 SG_ BMS_chgRequestTerminatedCount m9 : 10|4@1+ (1,0) [0|0] "" Vector__XXX
 SG_ BMS_hystRatio m10 : 11|10@1+ (0.001,0) [0|0] "" Vector__XXX
 SG_ BMS_vshTestNeeded m3 : 12|1@1+ (1,0) [0|0] "" Vector__XXX
 SG_ BMS_vshTestAllowed m3 : 13|1@1+ (1,0) [0|0] "" Vector__XXX
 SG_ BMS_vshFailure m3 : 14|1@1+ (1,0) [0|0] "" Vector__XXX
 SG_ BMS_fcCtrCleaningActiveNow m3 : 15|1@1+ (1,0) [0|0] "" Vector__XXX
 SG_ BMS_chgEndChargeState m9 : 16|4@1+ (1,0) [0|0] "" Vector__XXX
 SG_ BMS_energyTempGradientAtMaxTemp m13 : 16|9@1+ (0.1,0) [0|0] "" Vector__XXX
 SG_ BMS_pcsIsolatorEnabled m3 : 16|1@1+ (1,0) [0|0] "" Vector__XXX
 SG_ BMS_powerTransferStatus m4 : 16|4@1+ (1,0) [0|0] "" Vector__XXX
 SG_ BMS_pcsIsolatorSwitchGood m3 : 17|1@1+ (1,0) [0|0] "" Vector__XXX
 SG_ BMS_alphaState m3 : 18|3@1+ (1,0) [0|0] "" Vector__XXX
 SG_ BMS_maxModeledPackTemp m6 : 19|11@1+ (0.1,-50) [0|0] "" Vector__XXX
 SG_ BMS_modeledThermistorTemp2 m7 : 19|11@1+ (0.1,-50) [0|0] "" Vector__XXX
 SG_ BMS_modeledThermistorTemp7 m8 : 19|11@1+ (0.1,-50) [0|0] "" Vector__XXX
 SG_ BMS_chgEndBmsPowerTransferStatus m9 : 20|4@1+ (1,0) [0|0] "" Vector__XXX
 SG_ BMS_dcChargePowerLimit m5 : 20|12@1- (1,0) [0|0] "" Vector__XXX
 SG_ BMS_extDcPrechargeVoltageLimit m4 : 20|12@1+ (0.14650226075946277,0) [0|0] "" Vector__XXX
 SG_ BMS_hystRatioError m10 : 21|10@1+ (0.001,0) [0|0] "" Vector__XXX
 SG_ BMS_10HzTask_cpuUsage m0 : 22|14@1+ (0.01,0) [0|0] "" Vector__XXX
 SG_ BMS_cpuUsage_canRx m2 : 22|14@1+ (0.01,0) [0|0] "" Vector__XXX
 SG_ BMS_cpuUsage_vehTx m1 : 22|14@1+ (0.01,0) [0|0] "" Vector__XXX
 SG_ BMS_avgSleepPower m12 : 24|12@1+ (0.01,-40.95) [0|0] "" Vector__XXX
 SG_ BMS_chgEndCpPowerTransferStatus m9 : 24|3@1+ (1,0) [0|0] "" Vector__XXX
 SG_ BMS_energyWalkMaxVehiclePower m14 : 24|11@1- (1,500) [0|0] "" Vector__XXX
 SG_ BMS_feimState m3 : 24|4@1+ (1,0) [0|0] "" Vector__XXX
 SG_ BMS_maxOcvVsTempShift m11 : 24|13@1- (0.01,0) [0|0] "" Vector__XXX
 SG_ BMS_energyWalkMaxSoc m13 : 25|10@1+ (0.1,0) [0|0] "" Vector__XXX
 SG_ BMS_chgEndPcsPowerTransferStatus m9 : 27|2@1+ (1,0) [0|0] "" Vector__XXX
 SG_ BMS_bandoThmModelState m3 : 28|4@1+ (1,0) [0|0] "" Vector__XXX
 SG_ BMS_modeledThermistorTemp3 m7 : 30|11@1+ (0.1,-50) [0|0] "" Vector__XXX
 SG_ BMS_modeledThermistorTemp8 m8 : 30|11@1+ (0.1,-50) [0|0] "" Vector__XXX
 SG_ BMS_acRealPowerRequest m5 : 32|16@1- (0.002,0) [0|0] "" Vector__XXX
 SG_ BMS_avgModeledPackTemp m6 : 32|11@1+ (0.1,-50) [0|0] "" Vector__XXX
 SG_ BMS_chargeLimitReason_evseCurrentLimit m3 : 32|1@1+ (1,0) [0|0] "" Vector__XXX
 SG_ BMS_dcChargeCurrentRequest m4 : 32|14@1- (0.25,0) [0|0] "" Vector__XXX
 SG_ BMS_voltageRegState m10 : 32|2@1+ (1,0) [0|0] "" Vector__XXX
 SG_ BMS_chargeLimitReason_evseDeratingActive m3 : 33|1@1+ (1,0) [0|0] "" Vector__XXX
 SG_ BMS_chargeLimitReason_evsePowerLimit m3 : 34|1@1+ (1,0) [0|0] "" Vector__XXX
 SG_ BMS_chargeLimitReason_rampUpComplete m3 : 35|1@1+ (1,0) [0|0] "" Vector__XXX
 SG_ BMS_energyWalkMinSoc m13 : 35|10@1+ (0.1,0) [0|0] "" Vector__XXX
 SG_ BMS_gridFormCpState m14 : 35|4@1+ (1,0) [0|0] "" Vector__XXX
 SG_ BMS_100HzTask_cpuUsage m0 : 36|14@1+ (0.01,0) [0|0] "" Vector__XXX
 SG_ BMS_appNvramTask_cpuUsage m2 : 36|14@1+ (0.01,0) [0|0] "" Vector__XXX
 SG_ BMS_chargeLimitReason_socHigh m3 : 36|1@1+ (1,0) [0|0] "" Vector__XXX
 SG_ BMS_chgEndCpShutdownRequest m9 : 36|2@1+ (1,0) [0|0] "" Vector__XXX
 SG_ BMS_cpuUsage_hvsTx m1 : 36|14@1+ (0.01,0) [0|0] "" Vector__XXX
 SG_ BMS_chargeLimitReason_shadow m3 : 37|3@1+ (1,0) [0|0] "" Vector__XXX
 SG_ BMS_chgEndPcsShutdownRequest m9 : 38|2@1+ (1,0) [0|0] "" Vector__XXX
 SG_ BMS_battTempPct m14 : 40|8@1+ (0.4,0) [0|0] "" Vector__XXX
 SG_ BMS_chargeLimitReason_vehicleLimit m3 : 40|1@1+ (1,0) [0|0] "" Vector__XXX
 SG_ BMS_chgEndBatteryChargeRequest m9 : 40|1@1+ (1,0) [0|0] "" Vector__XXX
 SG_ BMS_estimatedEvsePower m10 : 40|16@1- (0.02,0) [0|0] "" Vector__XXX
 SG_ BMS_socMaxBrickId m11 : 40|8@1+ (1,1) [0|0] "" Vector__XXX
 SG_ BMS_chgEndDcEvseCompatible m9 : 41|1@1+ (1,0) [0|0] "" Vector__XXX
 SG_ BMS_modeledThermistorTemp4 m7 : 41|11@1+ (0.1,-50) [0|0] "" Vector__XXX
 SG_ BMS_modeledThermistorTemp9 m8 : 41|11@1+ (0.1,-50) [0|0] "" Vector__XXX
 SG_ BMS_chgEndDisableUnderFailure m9 : 42|1@1+ (1,0) [0|0] "" Vector__XXX
 SG_ BMS_modeledCoolantOutletTemp m6 : 43|11@1+ (0.1,-50) [0|0] "" Vector__XXX
 SG_ BMS_modeledMissingCellMaxTemp m9 : 43|11@1+ (0.1,-50) [0|0] "" Vector__XXX
 SG_ BMS_chargeEnergyWalkState m13 : 45|2@1+ (1,0) [0|0] "" Vector__XXX
 SG_ BMS_dcChargeCurrentLimit m4 : 46|13@1- (0.5,0) [0|0] "" Vector__XXX
 SG_ BMS_maxExtIsoFcLinkV m5 : 48|13@1+ (0.13429373702844585,0) [0|0] "" Vector__XXX
 SG_ BMS_packVoltage m13 : 48|16@1+ (0.01,0) [0|0] "" Vector__XXX
 SG_ BMS_socMinBrickId m11 : 48|8@1+ (1,1) [0|0] "" Vector__XXX
 SG_ BMS_1kHzTask_cpuUsage m0 : 50|14@1+ (0.01,0) [0|0] "" Vector__XXX
 SG_ BMS_cpuLoadRaw m2 : 50|14@1+ (0.01,0) [0|0] "" Vector__XXX
 SG_ BMS_cpuUsage_hviTx m1 : 50|14@1+ (0.01,0) [0|0] "" Vector__XXX
 SG_ BMS_modeledThermistorTemp10 m8 : 52|11@1+ (0.1,-50) [0|0] "" Vector__XXX
 SG_ BMS_modeledThermistorTemp5 m7 : 52|11@1+ (0.1,-50) [0|0] "" Vector__XXX
 SG_ BMS_maxModuleTempGradient m6 : 54|9@1+ (0.1,0) [0|0] "" Vector__XXX
 SG_ BMS_logChargeStatus m9 : 56|3@1+ (1,0) [0|0] "" Vector__XXX
 SG_ BMS_rippleHeatPowerDissipation m11 : 56|8@1+ (0.05,0) [0|0] "" Vector__XXX
 SG_ BMS_voltageRegulationBrickVTarget m10 : 56|8@1+ (0.01,2.5) [0|0] "" Vector__XXX
 SG_ BMS_chgEndShutdownReason m9 : 59|4@1+ (1,0) [0|0] "" Vector__XXX
 SG_ BMS_dcDischargeEnabled m4 : 59|1@1+ (1,0) [0|0] "" Vector__XXX
 SG_ BMS_rippleChargeRetryCount m4 : 60|3@1+ (1,0) [0|0] "" Vector__XXX

BO_ 883 UI_gpsVehicleSpeed: 8 Vector__XXX
 SG_ UI_gpsHDOP : 0|8@1+ (0.1,0) [0|0] "" Vector__XXX
 SG_ UI_gpsVehicleHeading : 8|16@1+ (0.0078125,0) [0|0] "" Vector__XXX
 SG_ UI_gpsVehicleSpeed : 24|16@1+ (0.00390625,0) [0|0] "" Vector__XXX
 SG_ UI_userSpeedOffset : 40|6@1+ (1,-30) [0|0] "" Vector__XXX
 SG_ UI_mapSpeedLimitUnits : 46|1@1+ (1,0) [0|0] "" Vector__XXX
 SG_ UI_userSpeedOffsetUnits : 47|1@1+ (1,0) [0|0] "" Vector__XXX
 SG_ UI_mppSpeedLimit : 48|5@1+ (5,0) [0|0] "" Vector__XXX
 SG_ UI_gpsNmeaMIA : 53|1@1+ (1,0) [0|0] "" Vector__XXX
 SG_ UI_gpsAntennaDisconnected : 54|1@1+ (1,0) [0|0] "" Vector__XXX
 SG_ UI_conditionalLimitActive : 55|1@1+ (1,0) [0|0] "" Vector__XXX
 SG_ UI_conditionalSpeedLimit : 56|5@1+ (5,0) [0|0] "" Vector__XXX

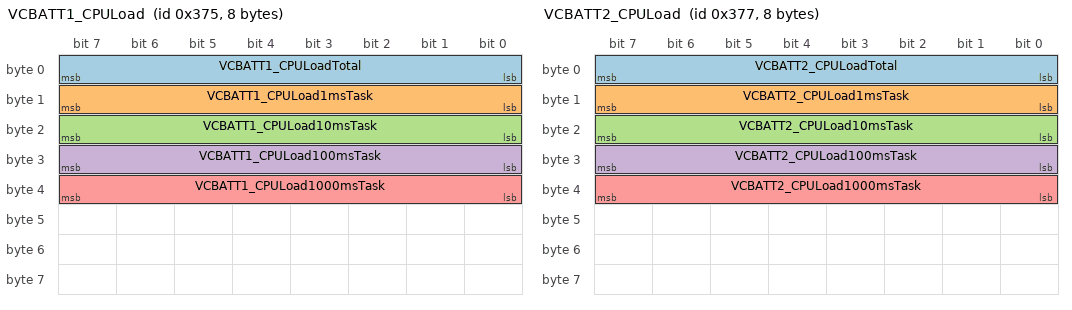
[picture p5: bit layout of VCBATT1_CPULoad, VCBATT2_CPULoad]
BO_ 885 VCBATT1_CPULoad: 8 Vector__XXX
 SG_ VCBATT1_CPULoadTotal : 0|8@1+ (1,0) [0|0] "" Vector__XXX
 SG_ VCBATT1_CPULoad1msTask : 8|8@1+ (1,0) [0|0] "" Vector__XXX
 SG_ VCBATT1_CPULoad10msTask : 16|8@1+ (1,0) [0|0] "" Vector__XXX
 SG_ VCBATT1_CPULoad100msTask : 24|8@1+ (1,0) [0|0] "" Vector__XXX
 SG_ VCBATT1_CPULoad1000msTask : 32|8@1+ (1,0) [0|0] "" Vector__XXX

BO_ 886 DIF_temperature: 8 Vector__XXX
 SG_ DIF_tempIndex M : 0|3@1+ (1,0) [0|0] "" Vector__XXX
 SG_ DIF_currentWeibullMiles m3 : 3|16@1+ (8,0) [0|0] "" Vector__XXX
 SG_ DIF_inverterTQF m0 : 3|2@1+ (1,0) [0|0] "" Vector__XXX
 SG_ DIF_fluidInTemp m2 : 8|8@1+ (1,-40) [0|0] "" Vector__XXX
 SG_ DIF_heatsink1Temp m1 : 8|8@1+ (1,-40) [0|0] "" Vector__XXX
 SG_ DIF_initialBurnInVehicleOdometer m4 : 8|32@1+ (0.001,0) [0|0] "" Vector__XXX
 SG_ DIF_pcbT m0 : 8|8@1+ (1,-40) [0|0] "" Vector__XXX
 SG_ DIF_heatsink2Temp m1 : 16|8@1+ (1,-40) [0|0] "" Vector__XXX
 SG_ DIF_inverterT m0 : 16|8@1+ (1,-40) [0|0] "" Vector__XXX
 SG_ DIF_normalFetBurnIn m2 : 16|16@1+ (0.00763,0) [0|0] "" Vector__XXX
 SG_ DIF_endOfServiceWeibullMiles m3 : 19|16@1+ (8,0) [0|0] "" Vector__XXX
 SG_ DIF_heatsink3Temp m1 : 24|8@1+ (1,-40) [0|0] "" Vector__XXX
 SG_ DIF_statorT m0 : 24|8@1+ (1,-40) [0|0] "" Vector__XXX
 SG_ DIF_additionalFetBurnIn m2 : 32|16@1+ (0.00763,0) [0|0] "" Vector__XXX
 SG_ DIF_dcCapT m0 : 32|8@1+ (1,-40) [0|0] "" Vector__XXX
 SG_ DIF_pcbTemp2 m1 : 32|8@1+ (1,-40) [0|0] "" Vector__XXX
 SG_ DIF_burnInDamageRatio m3 : 35|9@1+ (0.01,0) [0|0] "" Vector__XXX
 SG_ DIF_heatsinkT m0 : 40|8@1+ (1,-40) [0|0] "" Vector__XXX
 SG_ DIF_inverterHS2Est m4 : 40|8@1+ (1,-40) [0|0] "" Vector__XXX
 SG_ DIF_junctionTemp m1 : 40|8@1+ (1,-40) [0|0] "" Vector__XXX
 SG_ DIF_inverterSensorEst m3 : 44|8@1+ (1,-40) [0|0] "" Vector__XXX
 SG_ DIF_TPak1Temp m1 : 48|8@1+ (1,-40) [0|0] "" Vector__XXX
 SG_ DIF_inverterInletEst m4 : 48|8@1+ (1,-40) [0|0] "" Vector__XXX
 SG_ DIF_inverterTpct m0 : 48|8@1+ (0.4,0) [0|0] "" Vector__XXX
 SG_ DIF_inverterHS1Est m3 : 52|8@1+ (1,-40) [0|0] "" Vector__XXX
 SG_ DIF_TPak2Temp m1 : 56|8@1+ (1,-40) [0|0] "" Vector__XXX
 SG_ DIF_statorHousingTemp m4 : 56|8@1+ (1,-40) [0|0] "" Vector__XXX
 SG_ DIF_statorTpct m0 : 56|8@1+ (0.4,0) [0|0] "" Vector__XXX

BO_ 887 VCBATT2_CPULoad: 8 Vector__XXX
 SG_ VCBATT2_CPULoadTotal : 0|8@1+ (1,0) [0|0] "" Vector__XXX
 SG_ VCBATT2_CPULoad1msTask : 8|8@1+ (1,0) [0|0] "" Vector__XXX
 SG_ VCBATT2_CPULoad10msTask : 16|8@1+ (1,0) [0|0] "" Vector__XXX
 SG_ VCBATT2_CPULoad100msTask : 24|8@1+ (1,0) [0|0] "" Vector__XXX
 SG_ VCBATT2_CPULoad1000msTask : 32|8@1+ (1,0) [0|0] "" Vector__XXX

BO_ 889 VCSEC_BLERadioStatus: 8 Vector__XXX
 SG_ VCSEC_BLERadioStatusIndex M : 0|4@1+ (1,0) [0|0] "" Vector__XXX
 SG_ VCSEC_BLEDevicePacketCounter : 6|7@1+ (1,0) [0|0] "" Vector__XXX
 SG_ VCSEC_BLEAdvCounterC m7 : 13|16@1+ (1,0) [0|0] "" Vector__XXX
 SG_ VCSEC_BLEAdvStatusC m3 : 13|3@1+ (1,0) [0|0] "" Vector__XXX
 SG_ VCSEC_BLECPULoadC m3 : 16|7@1+ (1,0) [0|0] "" Vector__XXX
 SG_ VCSEC_BLECPULoadL m2 : 16|7@1+ (1,0) [0|0] "" Vector__XXX
 SG_ VCSEC_BLECPULoadRe m1 : 16|7@1+ (1,0) [0|0] "" Vector__XXX
 SG_ VCSEC_BLECPULoadRi m0 : 16|7@1+ (1,0) [0|0] "" Vector__XXX
 SG_ VCSEC_BLETimesScheduledL m6 : 16|8@1+ (1,0) [0|0] "" Vector__XXX
 SG_ VCSEC_BLETimesScheduledRe m5 : 16|8@1+ (1,0) [0|0] "" Vector__XXX
 SG_ VCSEC_BLETimesScheduledRi m4 : 16|8@1+ (1,0) [0|0] "" Vector__XXX
 SG_ VCSEC_totalEndpointNacksC m11 : 16|16@1+ (1,0) [0|0] "" Vector__XXX
 SG_ VCSEC_totalEndpointNacksL m10 : 16|16@1+ (1,0) [0|0] "" Vector__XXX
 SG_ VCSEC_totalEndpointNacksR m8 : 16|16@1+ (1,0) [0|0] "" Vector__XXX
 SG_ VCSEC_totalEndpointNacksRe m9 : 16|16@1+ (1,0) [0|0] "" Vector__XXX
 SG_ VCSEC_BLEHeapSizeC m3 : 24|14@1+ (1,0) [0|0] "" Vector__XXX
 SG_ VCSEC_BLEHeapSizeL m2 : 24|14@1+ (1,0) [0|0] "" Vector__XXX
 SG_ VCSEC_BLEHeapSizeRe m1 : 24|14@1+ (1,0) [0|0] "" Vector__XXX
 SG_ VCSEC_BLEHeapSizeRi m0 : 24|14@1+ (1,0) [0|0] "" Vector__XXX
 SG_ VCSEC_BLEPacketsReceivedL m6 : 24|8@1+ (1,0) [0|0] "" Vector__XXX
 SG_ VCSEC_BLEPacketsReceivedRe m5 : 24|8@1+ (1,0) [0|0] "" Vector__XXX
 SG_ VCSEC_BLEPacketsReceivedRi m4 : 24|8@1+ (1,0) [0|0] "" Vector__XXX
 SG_ VCSEC_BLERSSITrackingPercentC0 m7 : 32|4@1+ (8,0) [0|0] "" Vector__XXX
 SG_ VCSEC_BLEScheduleErrorsL m6 : 32|2@1+ (1,0) [0|0] "" Vector__XXX
 SG_ VCSEC_BLEScheduleErrorsRe m5 : 32|2@1+ (1,0) [0|0] "" Vector__XXX
 SG_ VCSEC_BLEScheduleErrorsRi m4 : 32|2@1+ (1,0) [0|0] "" Vector__XXX
 SG_ VCSEC_totalVCSECRetransmitsC m11 : 32|16@1+ (1,0) [0|0] "" Vector__XXX
 SG_ VCSEC_totalVCSECRetransmitsL m10 : 32|16@1+ (1,0) [0|0] "" Vector__XXX
 SG_ VCSEC_totalVCSECRetransmitsR m8 : 32|16@1+ (1,0) [0|0] "" Vector__XXX
 SG_ VCSEC_totalVCSECRetransmitsRe m9 : 32|16@1+ (1,0) [0|0] "" Vector__XXX
 SG_ VCSEC_BLEWhitelistEntriesL m6 : 34|4@1+ (1,0) [0|0] "" Vector__XXX
 SG_ VCSEC_BLEWhitelistEntriesRe m5 : 34|4@1+ (1,0) [0|0] "" Vector__XXX
 SG_ VCSEC_BLEWhitelistEntriesRi m4 : 34|4@1+ (1,0) [0|0] "" Vector__XXX
 SG_ VCSEC_BLERSSITrackingPercentC1 m7 : 36|4@1+ (8,0) [0|0] "" Vector__XXX
 SG_ VCSEC_BLENonWhitelistedScanEnabledL m6 : 38|1@1+ (1,0) [0|0] "" Vector__XXX
 SG_ VCSEC_BLENonWhitelistedScanEnabledRe m5 : 38|1@1+ (1,0) [0|0] "" Vector__XXX
 SG_ VCSEC_BLENonWhitelistedScanEnabledRi m4 : 38|1@1+ (1,0) [0|0] "" Vector__XXX
 SG_ VCSEC_connectionMonitorConnectionL0 m6 : 39|3@1+ (1,0) [0|0] "" Vector__XXX
 SG_ VCSEC_connectionMonitorConnectionRe0 m5 : 39|3@1+ (1,0) [0|0] "" Vector__XXX
 SG_ VCSEC_connectionMonitorConnectionRi0 m4 : 39|3@1+ (1,0) [0|0] "" Vector__XXX
 SG_ VCSEC_BLEHeapUsageC m3 : 40|7@1+ (1,0) [0|0] "" Vector__XXX
 SG_ VCSEC_BLEHeapUsageL m2 : 40|7@1+ (1,0) [0|0] "" Vector__XXX
 SG_ VCSEC_BLEHeapUsageRe m1 : 40|7@1+ (1,0) [0|0] "" Vector__XXX
 SG_ VCSEC_BLEHeapUsageRi m0 : 40|7@1+ (1,0) [0|0] "" Vector__XXX
 SG_ VCSEC_BLERSSITrackingPercentC2 m7 : 40|4@1+ (8,0) [0|0] "" Vector__XXX
 SG_ VCSEC_connectionMonitorConnectionL1 m6 : 42|3@1+ (1,0) [0|0] "" Vector__XXX
 SG_ VCSEC_connectionMonitorConnectionRe1 m5 : 42|3@1+ (1,0) [0|0] "" Vector__XXX
 SG_ VCSEC_connectionMonitorConnectionRi1 m4 : 42|3@1+ (1,0) [0|0] "" Vector__XXX
 SG_ VCSEC_BLENonWhitelistedScanEnabledC m7 : 44|1@1+ (1,0) [0|0] "" Vector__XXX
 SG_ VCSEC_BLEAdvPeriodC m7 : 45|11@1+ (1,0) [0|0] "" Vector__XXX
 SG_ VCSEC_connectionMonitorConnectionL2 m6 : 45|3@1+ (1,0) [0|0] "" Vector__XXX
 SG_ VCSEC_connectionMonitorConnectionRe2 m5 : 45|3@1+ (1,0) [0|0] "" Vector__XXX
 SG_ VCSEC_connectionMonitorConnectionRi2 m4 : 45|3@1+ (1,0) [0|0] "" Vector__XXX
 SG_ VCSEC_BLEHeapMaxUsageC m3 : 47|7@1+ (1,0) [0|0] "" Vector__XXX
 SG_ VCSEC_BLEHeapMaxUsageL m2 : 47|7@1+ (1,0) [0|0] "" Vector__XXX
 SG_ VCSEC_BLEHeapMaxUsageRe m1 : 47|7@1+ (1,0) [0|0] "" Vector__XXX
 SG_ VCSEC_BLEHeapMaxUsageRi m0 : 47|7@1+ (1,0) [0|0] "" Vector__XXX
 SG_ VCSEC_CMPeripheralMissingMatchL0 m6 : 48|8@1+ (1,0) [0|0] "" Vector__XXX
 SG_ VCSEC_CMPeripheralMissingMatchRe0 m5 : 48|8@1+ (1,0) [0|0] "" Vector__XXX
 SG_ VCSEC_CMPeripheralMissingMatchRi0 m4 : 48|8@1+ (1,0) [0|0] "" Vector__XXX
 SG_ VCSEC_queueSizeMaxC m11 : 48|8@1+ (1,0) [0|0] "" Vector__XXX
 SG_ VCSEC_queueSizeMaxL m10 : 48|8@1+ (1,0) [0|0] "" Vector__XXX
 SG_ VCSEC_queueSizeMaxR m8 : 48|8@1+ (1,0) [0|0] "" Vector__XXX
 SG_ VCSEC_queueSizeMaxRe m9 : 48|8@1+ (1,0) [0|0] "" Vector__XXX
 SG_ VCSEC_BLEGAPInitiatingConnectionC m7 : 56|1@1+ (1,0) [0|0] "" Vector__XXX
 SG_ VCSEC_CMPacketMatchL0 m6 : 56|8@1+ (1,0) [0|0] "" Vector__XXX
 SG_ VCSEC_CMPacketMatchRe0 m5 : 56|8@1+ (1,0) [0|0] "" Vector__XXX
 SG_ VCSEC_CMPacketMatchRi0 m4 : 56|8@1+ (1,0) [0|0] "" Vector__XXX
 SG_ VCSEC_queueLengthMaxC m11 : 56|8@1+ (1,0) [0|0] "" Vector__XXX
 SG_ VCSEC_queueLengthMaxL m10 : 56|8@1+ (1,0) [0|0] "" Vector__XXX
 SG_ VCSEC_queueLengthMaxR m8 : 56|8@1+ (1,0) [0|0] "" Vector__XXX
 SG_ VCSEC_queueLengthMaxRe m9 : 56|8@1+ (1,0) [0|0] "" Vector__XXX
 SG_ VCSEC_BLEGAPScanningC m7 : 57|1@1+ (1,0) [0|0] "" Vector__XXX
 SG_ VCSEC_BLEGAPAdvertisingC m7 : 58|1@1+ (1,0) [0|0] "" Vector__XXX

BO_ 890 VCSEC_ConnectionMonitor: 8 Vector__XXX
 SG_ VCSEC_BLEConnectionMonitorIndex M : 0|2@1+ (1,0) [0|0] "" Vector__XXX
 SG_ VCSEC_BLE0ConnInterval m3 : 2|10@1+ (1,0) [0|0] "" Vector__XXX
 SG_ VCSEC_BLERSSITrackingPercentL0 m2 : 4|4@1+ (8,0) [0|0] "" Vector__XXX
 SG_ VCSEC_BLERSSITrackingPercentR0 m0 : 4|4@1+ (8,0) [0|0] "" Vector__XXX
 SG_ VCSEC_BLERSSITrackingPercentRe0 m1 : 4|4@1+ (8,0) [0|0] "" Vector__XXX
 SG_ VCSEC_BLERSSITrackingPercentL1 m2 : 8|4@1+ (8,0) [0|0] "" Vector__XXX
 SG_ VCSEC_BLERSSITrackingPercentR1 m0 : 8|4@1+ (8,0) [0|0] "" Vector__XXX
 SG_ VCSEC_BLERSSITrackingPercentRe1 m1 : 8|4@1+ (8,0) [0|0] "" Vector__XXX
 SG_ VCSEC_BLE1ConnInterval m3 : 12|10@1+ (1,0) [0|0] "" Vector__XXX
 SG_ VCSEC_BLERSSITrackingPercentL2 m2 : 12|4@1+ (8,0) [0|0] "" Vector__XXX
 SG_ VCSEC_BLERSSITrackingPercentR2 m0 : 12|4@1+ (8,0) [0|0] "" Vector__XXX
 SG_ VCSEC_BLERSSITrackingPercentRe2 m1 : 12|4@1+ (8,0) [0|0] "" Vector__XXX
 SG_ VCSEC_CMEventNonEmptyPacketsL0 m2 : 16|8@1+ (1,0) [0|0] "" Vector__XXX
 SG_ VCSEC_CMEventNonEmptyPacketsR0 m1 : 16|8@1+ (1,0) [0|0] "" Vector__XXX
 SG_ VCSEC_CMEventNonEmptyPacketsRi0 m0 : 16|8@1+ (1,0) [0|0] "" Vector__XXX
 SG_ VCSEC_BLE2ConnInterval m3 : 22|10@1+ (1,0) [0|0] "" Vector__XXX
 SG_ VCSEC_CMEventSNNESNDeassertL0 m2 : 24|8@1+ (1,0) [0|0] "" Vector__XXX
 SG_ VCSEC_CMEventSNNESNDeassertR0 m1 : 24|8@1+ (1,0) [0|0] "" Vector__XXX
 SG_ VCSEC_CMEventSNNESNDeassertRi0 m0 : 24|8@1+ (1,0) [0|0] "" Vector__XXX
 SG_ VCSEC_CMEventNonMatchingPktCountL0 m2 : 32|8@1+ (1,0) [0|0] "" Vector__XXX
 SG_ VCSEC_CMEventNonMatchingPktCountR0 m1 : 32|8@1+ (1,0) [0|0] "" Vector__XXX
 SG_ VCSEC_CMEventNonMatchingPktCountRi0 m0 : 32|8@1+ (1,0) [0|0] "" Vector__XXX
 SG_ VCSEC_CMEventIncorrectChannelL0 m2 : 40|8@1+ (1,0) [0|0] "" Vector__XXX
 SG_ VCSEC_CMEventIncorrectChannelR0 m1 : 40|8@1+ (1,0) [0|0] "" Vector__XXX
 SG_ VCSEC_CMEventIncorrectChannelRi0 m0 : 40|8@1+ (1,0) [0|0] "" Vector__XXX
 SG_ VCSEC_CMEventOutsideWinL0 m2 : 48|8@1+ (1,0) [0|0] "" Vector__XXX
 SG_ VCSEC_CMEventOutsideWinR0 m1 : 48|8@1+ (1,0) [0|0] "" Vector__XXX
 SG_ VCSEC_CMEventOutsideWinRi0 m0 : 48|8@1+ (1,0) [0|0] "" Vector__XXX
 SG_ VCSEC_CMTimeSyncFailL0 m2 : 56|8@1+ (1,0) [0|0] "" Vector__XXX
 SG_ VCSEC_CMTimeSyncFailR0 m1 : 56|8@1+ (1,0) [0|0] "" Vector__XXX
 SG_ VCSEC_CMTimeSyncFailRi0 m0 : 56|8@1+ (1,0) [0|0] "" Vector__XXX

BO_ 893 CP_thermalStatus: 8 Vector__XXX
 SG_ CP_thermalStatusSelect M : 0|1@1+ (1,0) [0|0] "" Vector__XXX
 SG_ CP_dcPinTemperature m0 : 1|8@1+ (0.8039215686,-55) [0|0] "" Vector__XXX
 SG_ CP_pinTemperature1 m1 : 8|8@1+ (0.8039215686,-55) [0|0] "" Vector__XXX
 SG_ CP_dcPinTemperature2 m0 : 9|8@1+ (0.8039215686,-55) [0|0] "" Vector__XXX
 SG_ CP_pinTemperature2 m1 : 16|8@1+ (0.8039215686,-55) [0|0] "" Vector__XXX
 SG_ CP_acPinTemperature m0 : 17|8@1+ (0.8039215686,-55) [0|0] "" Vector__XXX
 SG_ CP_pinTemperature3 m1 : 24|8@1+ (0.8039215686,-55) [0|0] "" Vector__XXX
 SG_ CP_acPinTemperature2 m0 : 25|8@1+ (0.8039215686,-55) [0|0] "" Vector__XXX
 SG_ CP_pinTemperature4 m1 : 32|8@1+ (0.8039215686,-55) [0|0] "" Vector__XXX
 SG_ CP_pinTemp1Velocity m0 : 33|10@1- (0.15748,0) [0|0] "" Vector__XXX
 SG_ CP_pinTemp4Velocity m1 : 40|10@1- (0.15748,0) [0|0] "" Vector__XXX
 SG_ CP_pinTemp2Velocity m0 : 43|10@1- (0.15748,0) [0|0] "" Vector__XXX
 SG_ CP_pinTemp3Velocity m0 : 53|10@1- (0.15748,0) [0|0] "" Vector__XXX

BO_ 895 FC_alertMatrix3: 8 Vector__XXX
 SG_ FC_a129_CA_flyback_HW_OC : 0|1@1+ (1,0) [0|0] "" Vector__XXX
 SG_ FC_a130_CA_flyback_SW_OV : 1|1@1+ (1,0) [0|0] "" Vector__XXX
 SG_ FC_a131_CA_flyback_HW_OV : 2|1@1+ (1,0) [0|0] "" Vector__XXX
 SG_ FC_a132_CA_bmsMia : 3|1@1+ (1,0) [0|0] "" Vector__XXX
 SG_ FC_a133_CA_evseMia : 4|1@1+ (1,0) [0|0] "" Vector__XXX
 SG_ FC_a134_CA_vehTxBufOvf : 5|1@1+ (1,0) [0|0] "" Vector__XXX
 SG_ FC_a135_CA_vehRxBufOvf : 6|1@1+ (1,0) [0|0] "" Vector__XXX
 SG_ FC_a136_CA_evseTxBufOvf : 7|1@1+ (1,0) [0|0] "" Vector__XXX
 SG_ FC_a137_CA_evseRxBufOvf : 8|1@1+ (1,0) [0|0] "" Vector__XXX
 SG_ FC_a138_CA_hwProxTrip : 9|1@1+ (1,0) [0|0] "" Vector__XXX
 SG_ FC_a139_CA_ss2NotLow : 10|1@1+ (1,0) [0|0] "" Vector__XXX
 SG_ FC_a140_CA_bmsIncompatible : 11|1@1+ (1,0) [0|0] "" Vector__XXX
 SG_ FC_a141_CA_vehConn_OT : 12|1@1+ (1,0) [0|0] "" Vector__XXX
 SG_ FC_a142_CA_evseConn_OT : 13|1@1+ (1,0) [0|0] "" Vector__XXX
 SG_ FC_a143_CA_pcb_OT : 14|1@1+ (1,0) [0|0] "" Vector__XXX
 SG_ FC_a144_CA_flybackUnstable : 15|1@1+ (1,0) [0|0] "" Vector__XXX
 SG_ FC_a145_CA_flybackDataStale : 16|1@1+ (1,0) [0|0] "" Vector__XXX
 SG_ FC_a146_CA_flybackBusLoadHi : 17|1@1+ (1,0) [0|0] "" Vector__XXX
 SG_ FC_a147_CA_vehConn_UT : 18|1@1+ (1,0) [0|0] "" Vector__XXX
 SG_ FC_a148_CA_evseConn_UT : 19|1@1+ (1,0) [0|0] "" Vector__XXX
 SG_ FC_a149_CA_pcb_UT : 20|1@1+ (1,0) [0|0] "" Vector__XXX
 SG_ FC_a150_CA_vehToEvseDeltaHi : 21|1@1+ (1,0) [0|0] "" Vector__XXX
 SG_ FC_a151_CA_vehToEvseDeltaLo : 22|1@1+ (1,0) [0|0] "" Vector__XXX
 SG_ FC_a152_CA_vehToPcbDeltaHi : 23|1@1+ (1,0) [0|0] "" Vector__XXX
 SG_ FC_a153_CA_evseToPcbDeltaHi : 24|1@1+ (1,0) [0|0] "" Vector__XXX
 SG_ FC_a154_CA_vehToPcbDeltaLo : 25|1@1+ (1,0) [0|0] "" Vector__XXX
 SG_ FC_a155_CA_evseToPcbDeltaLo : 26|1@1+ (1,0) [0|0] "" Vector__XXX
 SG_ FC_a156_CA_flybackRunTimeout : 27|1@1+ (1,0) [0|0] "" Vector__XXX
 SG_ FC_a157_CA_unused : 28|1@1+ (1,0) [0|0] "" Vector__XXX
 SG_ FC_a158_CA_evseOverCurrent : 29|1@1+ (1,0) [0|0] "" Vector__XXX
 SG_ FC_a159_CA_wdtExpired : 30|1@1+ (1,0) [0|0] "" Vector__XXX
 SG_ FC_a160_CA_ss2Deasserted : 31|1@1+ (1,0) [0|0] "" Vector__XXX
 SG_ FC_a161_CA_vehTempHiFoldBk : 32|1@1+ (1,0) [0|0] "" Vector__XXX
 SG_ FC_a162_CA_evseTempHiFoldBk : 33|1@1+ (1,0) [0|0] "" Vector__XXX
 SG_ FC_a163_CA_pcbTempHiFoldBk : 34|1@1+ (1,0) [0|0] "" Vector__XXX
 SG_ FC_a164_CA_proxDisconnected : 35|1@1+ (1,0) [0|0] "" Vector__XXX
 SG_ FC_a165_CA_evseConnUnlocked : 36|1@1+ (1,0) [0|0] "" Vector__XXX
 SG_ FC_a166_CA_vehConnUnlocked : 37|1@1+ (1,0) [0|0] "" Vector__XXX
 SG_ FC_a167_CA_isoVoltageLow : 38|1@1+ (1,0) [0|0] "" Vector__XXX
 SG_ FC_a168_CA_proxTimeout : 39|1@1+ (1,0) [0|0] "" Vector__XXX
 SG_ FC_a169_CA_pilotAcceptTimeout : 40|1@1+ (1,0) [0|0] "" Vector__XXX
 SG_ FC_a170_CA_vehDataTimeout : 41|1@1+ (1,0) [0|0] "" Vector__XXX
 SG_ FC_a171_CA_vehConLockTimeout : 42|1@1+ (1,0) [0|0] "" Vector__XXX
 SG_ FC_a172_CA_ss2LowTimeout : 43|1@1+ (1,0) [0|0] "" Vector__XXX
 SG_ FC_a173_CA_evseDataTimeout : 44|1@1+ (1,0) [0|0] "" Vector__XXX
 SG_ FC_a174_CA_vehReadyTimeout : 45|1@1+ (1,0) [0|0] "" Vector__XXX
 SG_ FC_a175_CA_evseIsoTestTimeout : 46|1@1+ (1,0) [0|0] "" Vector__XXX
 SG_ FC_a176_CA_chargingBusTimeout : 47|1@1+ (1,0) [0|0] "" Vector__XXX
 SG_ FC_a177_CA_bmsCtrCloseTimeout : 48|1@1+ (1,0) [0|0] "" Vector__XXX
 SG_ FC_a178_CA_evseStartTimeout : 49|1@1+ (1,0) [0|0] "" Vector__XXX
 SG_ FC_a179_CA_startupProblem : 50|1@1+ (1,0) [0|0] "" Vector__XXX
 SG_ FC_a180_CA_chargingProblem : 51|1@1+ (1,0) [0|0] "" Vector__XXX
 SG_ FC_a181_CA_vRegBrownout : 52|1@1+ (1,0) [0|0] "" Vector__XXX
 SG_ FC_a182_CA_evseChrMalfunc : 53|1@1+ (1,0) [0|0] "" Vector__XXX
 SG_ FC_a183_CA_evseBatIncompat : 54|1@1+ (1,0) [0|0] "" Vector__XXX
 SG_ FC_a184_CA_evseBatMalfunc : 55|1@1+ (1,0) [0|0] "" Vector__XXX
 SG_ FC_a185_CA_vehReadyDeasserted : 56|1@1+ (1,0) [0|0] "" Vector__XXX
 SG_ FC_a186_CA_fcContOpenTimeout : 57|1@1+ (1,0) [0|0] "" Vector__XXX
 SG_ FC_a187_CA_evseConLockTimeout : 58|1@1+ (1,0) [0|0] "" Vector__XXX

BO_ 896 PM_alertMatrix2: 8 Vector__XXX
 SG_ PM_a066_pmfMIA : 1|1@1+ (1,0) [0|0] "" Vector__XXX
 SG_ PM_a067_pmrMIA : 2|1@1+ (1,0) [0|0] "" Vector__XXX
 SG_ PM_a080_exceptionPrefetchAbort : 15|1@1+ (1,0) [0|0] "" Vector__XXX
 SG_ PM_a081_exceptionDataAbort : 16|1@1+ (1,0) [0|0] "" Vector__XXX
 SG_ PM_a082_exceptionDataAbort2 : 17|1@1+ (1,0) [0|0] "" Vector__XXX
 SG_ PM_a083_ahbWriteError : 18|1@1+ (1,0) [0|0] "" Vector__XXX
 SG_ PM_a084_exceptionMpuFirewall : 19|1@1+ (1,0) [0|0] "" Vector__XXX
 SG_ PM_a086_exceptionUndefinedInstruction : 21|1@1+ (1,0) [0|0] "" Vector__XXX
 SG_ PM_a092_xtalOscillator : 27|1@1+ (1,0) [0|0] "" Vector__XXX
 SG_ PM_a093_accelPedalSupply : 28|1@1+ (1,0) [0|0] "" Vector__XXX
 SG_ PM_a095_ITPMSTimeoutGNSSConvergence : 30|1@1+ (1,0) [0|0] "" Vector__XXX
 SG_ PM_a096_ITPMSConvergedGNSSAbsRadiusTimes : 31|1@1+ (1,0) [0|0] "" Vector__XXX
 SG_ PM_a097_ITPMSRelativeCalibratedFactors : 32|1@1+ (1,0) [0|0] "" Vector__XXX
 SG_ PM_a098_ITPMSTriggerDebug : 33|1@1+ (1,0) [0|0] "" Vector__XXX
 SG_ PM_a099_ITPMSCalibrated : 34|1@1+ (1,0) [0|0] "" Vector__XXX
 SG_ PM_a100_diTraceInfo1 : 35|1@1+ (1,0) [0|0] "" Vector__XXX
 SG_ PM_a110_indirectTPMSPressureLossWarning : 45|1@1+ (1,0) [0|0] "" Vector__XXX
 SG_ PM_a111_unintendedResetCausedNeutral : 46|1@1+ (1,0) [0|0] "" Vector__XXX
 SG_ PM_a112_indirectTPMSPressureLossWarningHard : 47|1@1+ (1,0) [0|0] "" Vector__XXX
 SG_ PM_a113_btcMonitor : 48|1@1+ (1,0) [0|0] "" Vector__XXX
 SG_ PM_a115_indirectTPMSFaultedGhosted : 50|1@1+ (1,0) [0|0] "" Vector__XXX
 SG_ PM_a116_ITPMSBlowoutDetected : 51|1@1+ (1,0) [0|0] "" Vector__XXX
 SG_ PM_a117_ITPMSPermeabilityCalibrated : 52|1@1+ (1,0) [0|0] "" Vector__XXX
 SG_ PM_a120_indirectTPMSFaulted : 55|1@1+ (1,0) [0|0] "" Vector__XXX
 SG_ PM_a121_unintendedReset2 : 56|1@1+ (1,0) [0|0] "" Vector__XXX
 SG_ PM_a125_btcOutputIrrational : 60|1@1+ (1,0) [0|0] "" Vector__XXX

BO_ 897 VCFRONT_logging1Hz: 8 Vector__XXX
 SG_ VCFRONT_logging1HzIndex M : 0|5@1+ (1,0) [0|0] "" Vector__XXX
 SG_ VCFRONT_chillerExvCalibOffset m8 : 5|5@1- (8,0) [0|0] "" Vector__XXX
 SG_ VCFRONT_condenserPressureLimit m1 : 5|6@1+ (0.16,10) [0|0] "" Vector__XXX
 SG_ VCFRONT_coolantValveRecalReason m2 : 5|3@1+ (1,0) [0|0] "" Vector__XXX
 SG_ VCFRONT_espABSValveCurrent m20 : 5|4@1+ (0.1,0) [0|0] "" Vector__XXX
 SG_ VCFRONT_estPressureLiq m7 : 5|6@1+ (0.5,0) [0|0] "" Vector__XXX
 SG_ VCFRONT_exteriorQuietModeEnabled m6 : 5|1@1+ (1,0) [0|0] "" Vector__XXX
 SG_ VCFRONT_feedFwdMDotEvaporator m12 : 5|8@1+ (0.005,0) [0|0] "" Vector__XXX
 SG_ VCFRONT_frunkSwitch1Voltage m15 : 5|10@1+ (5,0) [0|0] "" Vector__XXX
 SG_ VCFRONT_homelinkRegionCode m3 : 5|4@1+ (1,0) [0|0] "" Vector__XXX
 SG_ VCFRONT_hpASBatteryHeatingAllowed m14 : 5|1@1+ (1,0) [0|0] "" Vector__XXX
 SG_ VCFRONT_hpChargeCableType m5 : 5|2@1+ (1,0) [0|0] "" Vector__XXX
 SG_ VCFRONT_hpForceScavenge m13 : 5|1@1+ (1,0) [0|0] "" Vector__XXX
 SG_ VCFRONT_leftFogLightCurrent m19 : 5|5@1+ (0.2,0) [0|0] "" Vector__XXX
 SG_ VCFRONT_louverPosReason m18 : 5|4@1+ (1,0) [0|0] "" Vector__XXX
 SG_ VCFRONT_modeTransitionID m0 : 5|6@1+ (1,0) [0|0] "" Vector__XXX
 SG_ VCFRONT_passiveSeriesRegOn m16 : 5|1@1+ (1,0) [0|0] "" Vector__XXX
 SG_ VCFRONT_radPassiveRejectEstimate m10 : 5|7@1+ (150,0) [0|0] "" Vector__XXX
 SG_ VCFRONT_superheatProtectionLimit m25 : 5|10@1+ (0.1,0) [0|0] "" Vector__XXX
 SG_ VCFRONT_tempSuperheatActFiltered m21 : 5|8@1- (0.25,26.5) [0|0] "" Vector__XXX
 SG_ VCFRONT_battOverStagUpperLimit m13 : 6|1@1+ (1,0) [0|0] "" Vector__XXX
 SG_ VCFRONT_exteriorQuietModeAllowed m6 : 6|1@1+ (1,0) [0|0] "" Vector__XXX
 SG_ VCFRONT_hpCOP1BatteryHeatingAllowed m14 : 6|1@1+ (1,0) [0|0] "" Vector__XXX
 SG_ VCFRONT_CCQdotFdFrwrdTarget m6 : 7|7@1+ (80,0) [0|0] "" Vector__XXX
 SG_ VCFRONT_battUnderStagUpperLimit m13 : 7|1@1+ (1,0) [0|0] "" Vector__XXX
 SG_ VCFRONT_hpCabinHeatScavengeOnly m14 : 7|1@1+ (1,0) [0|0] "" Vector__XXX
 SG_ VCFRONT_ambientColderThanBatt m13 : 8|1@1+ (1,0) [0|0] "" Vector__XXX
 SG_ VCFRONT_battDissipation m9 : 8|8@1+ (140,0) [0|0] "" Vector__XXX
 SG_ VCFRONT_chillerExvRange m4 : 8|8@1+ (7,0) [0|0] "" Vector__XXX
 SG_ VCFRONT_coolantValveCountRange m2 : 8|10@1+ (1,375) [0|0] "" Vector__XXX
 SG_ VCFRONT_debugWakeUp m22 : 8|32@1+ (1,0) [0|0] "" Vector__XXX
 SG_ VCFRONT_dischargePressureTarget m11 : 8|7@1+ (0.25,0) [0|0] "" Vector__XXX
 SG_ VCFRONT_hpCabinHeatAmbientSource m14 : 8|1@1+ (1,0) [0|0] "" Vector__XXX
 SG_ VCFRONT_hpColdStagnationLimit m17 : 8|7@1+ (1,-40) [0|0] "" Vector__XXX
 SG_ VCFRONT_hpDuctTargetLeft m26 : 8|7@1+ (1,0) [0|0] "" Vector__XXX
 SG_ VCFRONT_passiveDemandRadBypass m16 : 8|7@1+ (1,0) [0|0] "" Vector__XXX
 SG_ VCFRONT_subcoolActual m5 : 8|7@1- (0.4,15.2) [0|0] "" Vector__XXX
 SG_ VCFRONT_vcleftStaticBucketFill m23 : 8|5@1+ (40,0) [0|0] "" Vector__XXX
 SG_ VCFRONT_vcrightStaticBucketFill m24 : 8|5@1+ (40,0) [0|0] "" Vector__XXX
 SG_ VCFRONT_PCSCurrentFiltered m3 : 9|13@1- (0.1,0) [0|0] "" Vector__XXX
 SG_ VCFRONT_ambientSourcingAvailable m13 : 9|1@1+ (1,0) [0|0] "" Vector__XXX
 SG_ VCFRONT_difCurrent m20 : 9|7@1+ (0.05,0) [0|0] "" Vector__XXX
 SG_ VCFRONT_hpCabinHeatReheatScavenge m14 : 9|1@1+ (1,0) [0|0] "" Vector__XXX
 SG_ VCFRONT_hpEnergyFlowIndex m18 : 9|8@1+ (4,0) [0|0] "" Vector__XXX
 SG_ VCFRONT_evapExvCalibOffset m8 : 10|5@1- (8,0) [0|0] "" Vector__XXX
 SG_ VCFRONT_hpCabinHeatReheatAmbientSource m14 : 10|1@1+ (1,0) [0|0] "" Vector__XXX
 SG_ VCFRONT_hpMode m13 : 10|5@1+ (1,0) [0|0] "" Vector__XXX
 SG_ VCFRONT_rightFogLightCurrent m19 : 10|5@1+ (0.2,0) [0|0] "" Vector__XXX
 SG_ VCFRONT_estPressureSuct m7 : 11|7@1+ (0.125,0) [0|0] "" Vector__XXX
 SG_ VCFRONT_fanDemandCondenser m1 : 11|7@1+ (1,0) [0|0] "" Vector__XXX
 SG_ VCFRONT_hpCabinHeatBlend m14 : 11|1@1+ (1,0) [0|0] "" Vector__XXX
 SG_ VCFRONT_modeDesired m0 : 11|2@1+ (1,0) [0|0] "" Vector__XXX
 SG_ VCFRONT_hpCabinHeatCOP1 m14 : 12|1@1+ (1,0) [0|0] "" Vector__XXX
 SG_ VCFRONT_lccInletTempEstimate m10 : 12|8@1- (1,0) [0|0] "" Vector__XXX
 SG_ VCFRONT_hpCabinHeatBatteryHeatAmbSrc m12 : 13|1@1+ (1,0) [0|0] "" Vector__XXX
 SG_ VCFRONT_hpCabinHeatBatteryHeatReheatAmbSrc m14 : 13|1@1+ (1,0) [0|0] "" Vector__XXX
 SG_ VCFRONT_targetPTActiveCool m0 : 13|7@1+ (1,0) [0|0] "" Vector__XXX
 SG_ VCFRONT_tempRefrigDischarge m21 : 13|11@1+ (0.125,-40) [0|0] "" Vector__XXX
 SG_ VCFRONT_vcleftStaticBucketFill0 m23 : 13|5@1+ (40,0) [0|0] "" Vector__XXX
 SG_ VCFRONT_vcrightStaticBucketFill0 m24 : 13|5@1+ (40,0) [0|0] "" Vector__XXX
 SG_ VCFRONT_CCQdotFdbk m6 : 14|7@1- (80,0) [0|0] "" Vector__XXX
 SG_ VCFRONT_hpCabinHeatBatteryCoolReheat m14 : 14|1@1+ (1,0) [0|0] "" Vector__XXX
 SG_ VCFRONT_hpCabinHeatBatteryHeatCOP1 m12 : 14|1@1+ (1,0) [0|0] "" Vector__XXX
 SG_ VCFRONT_battLoopWorthCooling m13 : 15|1@1+ (1,0) [0|0] "" Vector__XXX
 SG_ VCFRONT_evapDisabledLowPsCutout m11 : 15|1@1+ (1,0) [0|0] "" Vector__XXX
 SG_ VCFRONT_feedFwdMDotCabinCondenser m12 : 15|8@1+ (0.005,0) [0|0] "" Vector__XXX
 SG_ VCFRONT_frunkSwitch2Voltage m15 : 15|10@1+ (5,0) [0|0] "" Vector__XXX
 SG_ VCFRONT_hpCabinCoolEvaporator m14 : 15|1@1+ (1,0) [0|0] "" Vector__XXX
 SG_ VCFRONT_recircExvCalibOffset m8 : 15|5@1- (8,0) [0|0] "" Vector__XXX
 SG_ VCFRONT_sideMarkersCurrent m19 : 15|5@1+ (0.2,0) [0|0] "" Vector__XXX
 SG_ VCFRONT_chillerDemandWatts m25 : 16|8@1+ (100,0) [0|0] "" Vector__XXX
 SG_ VCFRONT_diDissipation m9 : 16|8@1+ (80,0) [0|0] "" Vector__XXX
 SG_ VCFRONT_difDischargeCurrent m20 : 16|5@1+ (0.05,0) [0|0] "" Vector__XXX
 SG_ VCFRONT_evapExvRange m4 : 16|8@1+ (7,0) [0|0] "" Vector__XXX
 SG_ VCFRONT_hpCabinCoolEvaporatorReheat m14 : 16|1@1+ (1,0) [0|0] "" Vector__XXX
 SG_ VCFRONT_hpDuctTargetRight m26 : 16|7@1+ (1,0) [0|0] "" Vector__XXX
 SG_ VCFRONT_hpHotStagnationLimit m17 : 16|7@1+ (1,-40) [0|0] "" Vector__XXX
 SG_ VCFRONT_hpSubcoolTarget m5 : 16|5@1+ (1,0) [0|0] "" Vector__XXX
 SG_ VCFRONT_minFlowPDCont m11 : 16|8@1+ (0.5,0) [0|0] "" Vector__XXX
 SG_ VCFRONT_ptLoopWorthCooling m13 : 16|1@1+ (1,0) [0|0] "" Vector__XXX
 SG_ VCFRONT_targetLccActiveCoolCap m16 : 16|7@1+ (1,0) [0|0] "" Vector__XXX
 SG_ VCFRONT_estCompRefrigMassflow m13 : 17|6@1+ (4,0) [0|0] "" Vector__XXX
 SG_ VCFRONT_hpBatteryHeatAmbientSource m14 : 17|1@1+ (1,0) [0|0] "" Vector__XXX
 SG_ VCFRONT_hpEnergyFlowIndexFiltered m18 : 17|8@1+ (4,0) [0|0] "" Vector__XXX
 SG_ VCFRONT_coolantValveAngleDrift m2 : 18|10@1+ (0.25,-127) [0|0] "" Vector__XXX
 SG_ VCFRONT_estPressureDisch m7 : 18|7@1+ (0.25,0) [0|0] "" Vector__XXX
 SG_ VCFRONT_fanDemandRadiator m1 : 18|7@1+ (1,0) [0|0] "" Vector__XXX
 SG_ VCFRONT_hpBatteryHeatCOP1 m14 : 18|1@1+ (1,0) [0|0] "" Vector__XXX
 SG_ VCFRONT_vcleftStaticBucketFill1 m23 : 18|5@1+ (40,0) [0|0] "" Vector__XXX
 SG_ VCFRONT_vcrightStaticBucketFill1 m24 : 18|5@1+ (40,0) [0|0] "" Vector__XXX
 SG_ VCFRONT_hpBatteryCool m14 : 19|1@1+ (1,0) [0|0] "" Vector__XXX
 SG_ VCFRONT_chillerInletTempEstimate m10 : 20|8@1- (1,0) [0|0] "" Vector__XXX
 SG_ VCFRONT_hpBatteryCoolCabinCondenserCD m14 : 20|1@1+ (1,0) [0|0] "" Vector__XXX
 SG_ VCFRONT_lccExvCalibOffset m8 : 20|5@1- (8,0) [0|0] "" Vector__XXX
 SG_ VCFRONT_leftSideRepeaterCurrent m19 : 20|8@1+ (0.062,0) [0|0] "" Vector__XXX
 SG_ VCFRONT_targetPtOptionalActiveCool m0 : 20|7@1+ (1,0) [0|0] "" Vector__XXX
 SG_ VCFRONT_CCQdotActual m6 : 21|7@1+ (80,0) [0|0] "" Vector__XXX
 SG_ VCFRONT_CMPDischargeSuperheat m5 : 21|5@1- (1,6) [0|0] "" Vector__XXX
 SG_ VCFRONT_frontOilPumpCurrent m20 : 21|9@1+ (0.047,0) [0|0] "" Vector__XXX
 SG_ VCFRONT_hpBatteryCoolCabinCondenserHD m14 : 21|1@1+ (1,0) [0|0] "" Vector__XXX
 SG_ VCFRONT_hpBatteryCoolCabinReheat m14 : 22|1@1+ (1,0) [0|0] "" Vector__XXX
 SG_ VCFRONT_radInletTempEstimate m3 : 22|8@1- (1,0) [0|0] "" Vector__XXX
 SG_ VCFRONT_feedBackEvapTempController m12 : 23|7@1+ (0.01,-0.5) [0|0] "" Vector__XXX
 SG_ VCFRONT_hpBatteryCoolEvaporator m14 : 23|1@1+ (1,0) [0|0] "" Vector__XXX
 SG_ VCFRONT_hpCompFlowIndex m17 : 23|8@1+ (1,30) [0|0] "" Vector__XXX
 SG_ VCFRONT_pressureRefrigDischEst m13 : 23|5@1+ (1,0) [0|0] "" Vector__XXX
 SG_ VCFRONT_targetLccActiveCoolEff m16 : 23|7@1+ (1,0) [0|0] "" Vector__XXX
 SG_ VCFRONT_vcleftStaticBucketFill2 m23 : 23|5@1+ (40,0) [0|0] "" Vector__XXX
 SG_ VCFRONT_vcrightStaticBucketFill2 m24 : 23|5@1+ (40,0) [0|0] "" Vector__XXX
 SG_ VCFRONT_PDischargeControllerOutput m11 : 24|8@1+ (0.5,0) [0|0] "" Vector__XXX
 SG_ VCFRONT_chillerPassiveCoolPower m9 : 24|8@1- (60,7560) [0|0] "" Vector__XXX
 SG_ VCFRONT_nominalTevapHWLimit m25 : 24|7@1+ (0.5,0) [0|0] "" Vector__XXX
 SG_ VCFRONT_pumpBatteryRPMTarget m21 : 24|8@1+ (30,0) [0|0] "" Vector__XXX
 SG_ VCFRONT_recircExvRange m4 : 24|8@1+ (7,0) [0|0] "" Vector__XXX
 SG_ VCFRONT_suctionSuperheatEstTsSNA m14 : 24|4@1+ (2,0) [0|0] "" Vector__XXX
 SG_ VCFRONT_ccLeftExvCalibOffset m8 : 25|5@1- (8,0) [0|0] "" Vector__XXX
 SG_ VCFRONT_ductLeftAtSS m18 : 25|1@1+ (1,0) [0|0] "" Vector__XXX
 SG_ VCFRONT_estTempLiq m7 : 25|8@1- (0.8,68.8) [0|0] "" Vector__XXX
 SG_ VCFRONT_frunkSensorWindowActive m15 : 25|1@1+ (1,0) [0|0] "" Vector__XXX
 SG_ VCFRONT_tempRefrigSuction m1 : 25|8@1+ (0.5,-40) [0|0] "" Vector__XXX
 SG_ VCFRONT_correctedLowSideTemperature m15 : 26|8@1- (0.7874015748031497,10.236220472440946) [0|0] "" Vector__XXX
 SG_ VCFRONT_ductRightAtSS m18 : 26|1@1+ (1,0) [0|0] "" Vector__XXX
 SG_ VCFRONT_hpCOP m5 : 26|6@1+ (0.1,0) [0|0] "" Vector__XXX
 SG_ VCFRONT_minCompressorRPMAllowed m18 : 27|7@1+ (90,0) [0|0] "" Vector__XXX
 SG_ VCFRONT_targetPTPassive m0 : 27|7@1+ (1,-20) [0|0] "" Vector__XXX
 SG_ VCFRONT_coolantValveRecalCount m2 : 28|16@1+ (1,0) [0|0] "" Vector__XXX
 SG_ VCFRONT_evapFdFrwrdTarget m6 : 28|7@1+ (80,0) [0|0] "" Vector__XXX
 SG_ VCFRONT_feedFwdFanDemand m10 : 28|7@1+ (1,0) [0|0] "" Vector__XXX
 SG_ VCFRONT_rightSideRepeaterCurrent m19 : 28|8@1+ (0.062,0) [0|0] "" Vector__XXX
 SG_ VCFRONT_tempRefrigDischargeEst m13 : 28|6@1+ (1.5,46) [0|0] "" Vector__XXX
 SG_ VCFRONT_tempRefrigSuctionEst m14 : 28|6@1- (1.2,7.2) [0|0] "" Vector__XXX
 SG_ VCFRONT_vcleftStaticBucketFill3 m23 : 28|5@1+ (40,0) [0|0] "" Vector__XXX
 SG_ VCFRONT_vcrightStaticBucketFill3 m24 : 28|5@1+ (40,0) [0|0] "" Vector__XXX
 SG_ VCFRONT_ccRightExvCalibOffset m8 : 30|5@1- (8,0) [0|0] "" Vector__XXX
 SG_ VCFRONT_coolantValveCurrent m20 : 30|6@1+ (0.5,0) [0|0] "" Vector__XXX
 SG_ VCFRONT_coolantValveDailyAngleTravel m16 : 30|7@1+ (60,0) [0|0] "" Vector__XXX
 SG_ VCFRONT_feedBackDuctTempController m12 : 30|8@1+ (0.01,-1) [0|0] "" Vector__XXX
 SG_ VCFRONT_radiatorSteamDetectionState m3 : 30|3@1+ (1,0) [0|0] "" Vector__XXX
 SG_ VCFRONT_battCoolEvapEnableDelay m25 : 31|1@1+ (1,0) [0|0] "" Vector__XXX
 SG_ VCFRONT_hpCompFlowIndexFiltered m17 : 31|8@1+ (1,30) [0|0] "" Vector__XXX
 SG_ VCFRONT_ambientTempState m25 : 32|2@1+ (1,0) [0|0] "" Vector__XXX
 SG_ VCFRONT_lccExvRange m4 : 32|8@1+ (7,0) [0|0] "" Vector__XXX
 SG_ VCFRONT_lccPassiveHeatPower m9 : 32|8@1+ (60,0) [0|0] "" Vector__XXX
 SG_ VCFRONT_lowSideWattsLift m5 : 32|7@1+ (60,0) [0|0] "" Vector__XXX
 SG_ VCFRONT_pumpPowertrainRPMTarget m21 : 32|8@1+ (30,0) [0|0] "" Vector__XXX
 SG_ VCFRONT_suctionPressureTarget m11 : 32|6@1+ (0.15,0) [0|0] "" Vector__XXX
 SG_ VCFRONT_estTempSuct m7 : 33|6@1- (1,2) [0|0] "" Vector__XXX
 SG_ VCFRONT_hcmlSelectedBinningMethod m3 : 33|2@1+ (1,0) [0|0] "" Vector__XXX
 SG_ VCFRONT_pumpBatteryFETTemp m1 : 33|8@1+ (1,-40) [0|0] "" Vector__XXX
 SG_ VCFRONT_vcleftDynamicBucketFill m23 : 33|5@1+ (40,0) [0|0] "" Vector__XXX
 SG_ VCFRONT_vcrightDynamicBucketFill m24 : 33|5@1+ (40,0) [0|0] "" Vector__XXX
 SG_ VCFRONT_ambientTempUnlatchReason m25 : 34|3@1+ (1,0) [0|0] "" Vector__XXX
 SG_ VCFRONT_ccRefrigerantMassFlow m18 : 34|6@1+ (4,0) [0|0] "" Vector__XXX
 SG_ VCFRONT_estCompPower m13 : 34|9@1+ (20,0) [0|0] "" Vector__XXX
 SG_ VCFRONT_hpBattOverTempHvacDisable m14 : 34|1@1+ (1,0) [0|0] "" Vector__XXX
 SG_ VCFRONT_mdotAirRadiator m15 : 34|7@1+ (0.031496062992125984,0) [0|0] "" Vector__XXX
 SG_ VCFRONT_targetBatActiveCool m0 : 34|7@1+ (1,0) [0|0] "" Vector__XXX
 SG_ VCFRONT_chillerEXVControlState m8 : 35|3@1+ (1,0) [0|0] "" Vector__XXX
 SG_ VCFRONT_evapFdbk m6 : 35|7@1- (100,-3300) [0|0] "" Vector__XXX
 SG_ VCFRONT_feedFwdPumpDemand m10 : 35|7@1+ (1,0) [0|0] "" Vector__XXX
 SG_ VCFRONT_hcmrSelectedBinningMethod m3 : 35|2@1+ (1,0) [0|0] "" Vector__XXX
 SG_ VCFRONT_hpDiagLouverCalib m14 : 35|1@1+ (1,0) [0|0] "" Vector__XXX
 SG_ VCFRONT_frunkLEDCurrent m19 : 36|4@1+ (0.01,0) [0|0] "" Vector__XXX
 SG_ VCFRONT_hpDiagHighSideNotNominal m14 : 36|1@1+ (1,0) [0|0] "" Vector__XXX
 SG_ VCFRONT_windshieldWiperCurrent m20 : 36|6@1+ (1,0) [0|0] "" Vector__XXX
 SG_ VCFRONT_coolantPurgeMinutesRun m3 : 37|6@1+ (1,0) [0|0] "" Vector__XXX
 SG_ VCFRONT_dischargePressureLimit m16 : 37|7@1+ (0.25,0) [0|0] "" Vector__XXX
 SG_ VCFRONT_hpForceModeRadClear m14 : 37|1@1+ (1,0) [0|0] "" Vector__XXX
 SG_ VCFRONT_ambientSourcingDisabled m11 : 38|1@1+ (1,0) [0|0] "" Vector__XXX
 SG_ VCFRONT_estPressureDischargeSat m14 : 38|7@1+ (0.25,0) [0|0] "" Vector__XXX
 SG_ VCFRONT_evapEXVControlState m8 : 38|3@1+ (1,0) [0|0] "" Vector__XXX
 SG_ VCFRONT_isSolenoidAllowed m12 : 38|1@1+ (1,0) [0|0] "" Vector__XXX
 SG_ VCFRONT_vcleftDynamicBucketFill0 m23 : 38|5@1+ (40,0) [0|0] "" Vector__XXX
 SG_ VCFRONT_vcrightDynamicBucketFill0 m24 : 38|5@1+ (40,0) [0|0] "" Vector__XXX
 SG_ VCFRONT_chillerLiftDisabledLowPs m11 : 39|1@1+ (1,0) [0|0] "" Vector__XXX
 SG_ VCFRONT_estTempDisch m7 : 39|7@1- (1.5,75) [0|0] "" Vector__XXX
 SG_ VCFRONT_maxChillerCoolingPower m12 : 39|8@1+ (100,0) [0|0] "" Vector__XXX
 SG_ VCFRONT_subcoolEstTlSNA m17 : 39|6@1- (2,0) [0|0] "" Vector__XXX
 SG_ VCFRONT_tempSuperheatActual m5 : 39|10@1+ (0.1,-20) [0|0] "" Vector__XXX
 SG_ VCFRONT_PSuctionControllerOutput m11 : 40|8@1+ (0.5,0) [0|0] "" Vector__XXX
 SG_ VCFRONT_ccLeftExvRange m4 : 40|8@1+ (7,0) [0|0] "" Vector__XXX
 SG_ VCFRONT_compressorSuctionVaporQuality m25 : 40|5@1+ (0.01,0.7) [0|0] "" Vector__XXX
 SG_ VCFRONT_coolantFlowChillerTarget m21 : 40|8@1+ (0.161,0) [0|0] "" Vector__XXX
 SG_ VCFRONT_fanCurrentIndex m22 : 40|7@1+ (1,0) [0|0] "" Vector__XXX
 SG_ VCFRONT_highSideDpResidual m18 : 40|7@1- (0.1,0) [0|0] "" Vector__XXX
 SG_ VCFRONT_homelinkCurrent m19 : 40|5@1+ (0.01,0) [0|0] "" Vector__XXX
 SG_ VCFRONT_maxAllowedEvapPowerInSeries m9 : 40|8@1+ (40,0) [0|0] "" Vector__XXX
 SG_ VCFRONT_chillerCOP1ResidualLoad m15 : 41|7@1+ (78.74015748031496,0) [0|0] "" Vector__XXX
 SG_ VCFRONT_pumpPowertrainFETTemp m1 : 41|8@1+ (1,-40) [0|0] "" Vector__XXX
 SG_ VCFRONT_recircEXVControlState m8 : 41|3@1+ (1,0) [0|0] "" Vector__XXX
 SG_ VCFRONT_targetBatOptionalActiveCool m0 : 41|7@1+ (1,0) [0|0] "" Vector__XXX
 SG_ VCFRONT_DIQdotA m6 : 42|7@1+ (80,0) [0|0] "" Vector__XXX
 SG_ VCFRONT_radActiveRejectEstimate m10 : 42|7@1+ (150,0) [0|0] "" Vector__XXX
 SG_ VCFRONT_windshldFluidPumpCurrent m20 : 42|6@1+ (0.5,0) [0|0] "" Vector__XXX
 SG_ VCFRONT_coolantLevelVoltage m3 : 43|9@1+ (0.01,0) [0|0] "" Vector__XXX
 SG_ VCFRONT_hpCompPowerIndex m13 : 43|7@1+ (1,0) [0|0] "" Vector__XXX
 SG_ VCFRONT_vcleftDynamicBucketFill1 m23 : 43|5@1+ (40,0) [0|0] "" Vector__XXX
 SG_ VCFRONT_vcrightDynamicBucketFill1 m24 : 43|5@1+ (40,0) [0|0] "" Vector__XXX
 SG_ VCFRONT_coolantValveWindupEst m2 : 44|6@1+ (2,0) [0|0] "" Vector__XXX
 SG_ VCFRONT_lccEXVControlState m8 : 44|3@1+ (1,0) [0|0] "" Vector__XXX
 SG_ VCFRONT_radMovementBlockActive m16 : 44|1@1+ (1,0) [0|0] "" Vector__XXX
 SG_ VCFRONT_radBypassMoveReason m16 : 45|4@1+ (1,0) [0|0] "" Vector__XXX
 SG_ VCFRONT_radarCurrent m19 : 45|5@1+ (0.5,0) [0|0] "" Vector__XXX
 SG_ VCFRONT_subcoolEstPlSNA m17 : 45|6@1- (2,0) [0|0] "" Vector__XXX
 SG_ VCFRONT_tempRefrigLiquid m14 : 45|11@1+ (0.125,-40) [0|0] "" Vector__XXX
 SG_ VCFRONT_estCompressorRpm m7 : 46|9@1+ (30,0) [0|0] "" Vector__XXX
 SG_ VCFRONT_abnormalHighSuctionSuperheat m18 : 47|1@1+ (1,0) [0|0] "" Vector__XXX
 SG_ VCFRONT_cclEXVControlState m8 : 47|3@1+ (1,0) [0|0] "" Vector__XXX
 SG_ VCFRONT_fanControlRadCanCool m12 : 47|1@1+ (1,0) [0|0] "" Vector__XXX
 SG_ VCFRONT_cabinHeatingCOP1MinActiveRefCharge m25 : 48|7@1+ (10,0) [0|0] "" Vector__XXX
 SG_ VCFRONT_ccRightExvRange m4 : 48|8@1+ (7,0) [0|0] "" Vector__XXX
 SG_ VCFRONT_coolantValveAngleTravel m18 : 48|10@1+ (5,0) [0|0] "" Vector__XXX
 SG_ VCFRONT_fanControlFeedfwdActive m12 : 48|1@1+ (1,0) [0|0] "" Vector__XXX
 SG_ VCFRONT_hpCompPowerIndexCorrected m22 : 48|7@1+ (1,0) [0|0] "" Vector__XXX
 SG_ VCFRONT_minAllowedChillerPowerInSeries m9 : 48|8@1+ (40,0) [0|0] "" Vector__XXX
 SG_ VCFRONT_minAllowedSuctionPressure m11 : 48|7@1+ (0.02,0) [0|0] "" Vector__XXX
 SG_ VCFRONT_radiatorFanRPMTarget m21 : 48|8@1+ (40,0) [0|0] "" Vector__XXX
 SG_ VCFRONT_targetBatPassive m0 : 48|7@1+ (1,-20) [0|0] "" Vector__XXX
 SG_ VCFRONT_upperGlassHeaterCurrent m20 : 48|9@1+ (0.05,0) [0|0] "" Vector__XXX
 SG_ VCFRONT_vcleftDynamicBucketFill2 m23 : 48|5@1+ (40,0) [0|0] "" Vector__XXX
 SG_ VCFRONT_vcrightDynamicBucketFill2 m24 : 48|5@1+ (40,0) [0|0] "" Vector__XXX
 SG_ VCFRONT_wiperCycles m15 : 48|16@1+ (100,0) [0|0] "" Vector__XXX
 SG_ VCFRONT_evapFdFrwrdTargetMinimum m6 : 49|7@1+ (80,0) [0|0] "" Vector__XXX
 SG_ VCFRONT_fanControlRadiatorUa m12 : 49|7@1+ (8,0) [0|0] "" Vector__XXX
 SG_ VCFRONT_hpBattHeatingPower m16 : 49|7@1+ (100,0) [0|0] "" Vector__XXX
 SG_ VCFRONT_radOptionalRejectEstimate m10 : 49|7@1+ (150,0) [0|0] "" Vector__XXX
 SG_ VCFRONT_radiatorFanFETTemp m1 : 49|8@1+ (1,-40) [0|0] "" Vector__XXX
 SG_ VCFRONT_tempSuperheatTarget m5 : 49|10@1+ (0.1,0) [0|0] "" Vector__XXX
 SG_ VCFRONT_ccrEXVControlState m8 : 50|3@1+ (1,0) [0|0] "" Vector__XXX
 SG_ VCFRONT_coolantValveRadBypass m2 : 50|7@1+ (1,0) [0|0] "" Vector__XXX
 SG_ VCFRONT_hpAtSteadyState m13 : 50|1@1+ (1,0) [0|0] "" Vector__XXX
 SG_ VCFRONT_shutOffValve1Current m19 : 50|6@1+ (0.2,0) [0|0] "" Vector__XXX
 SG_ VCFRONT_pressureRefrigSuctionEst m13 : 51|6@1+ (0.16,0) [0|0] "" Vector__XXX
 SG_ VCFRONT_tempRefrigLiquidEst m17 : 51|6@1+ (2,0) [0|0] "" Vector__XXX
 SG_ VCFRONT_estimatedChillerLoadCOP1 m3 : 52|8@1+ (39.21568627450981,0) [0|0] "" Vector__XXX
 SG_ VCFRONT_chillerExvCalibFailed m8 : 53|1@1+ (1,0) [0|0] "" Vector__XXX
 SG_ VCFRONT_vcleftDynamicBucketFill3 m23 : 53|5@1+ (40,0) [0|0] "" Vector__XXX
 SG_ VCFRONT_vcrightDynamicBucketFill3 m24 : 53|5@1+ (40,0) [0|0] "" Vector__XXX
 SG_ VCFRONT_evapExvCalibFailed m8 : 54|1@1+ (1,0) [0|0] "" Vector__XXX
 SG_ VCFRONT_estQLift m7 : 55|6@1+ (100,0) [0|0] "" Vector__XXX
 SG_ VCFRONT_recircExvCalibFailed m8 : 55|1@1+ (1,0) [0|0] "" Vector__XXX
 SG_ VCFRONT_targetBatActiveHeat m0 : 55|7@1+ (1,-40) [0|0] "" Vector__XXX
 SG_ VCFRONT_batteryDischArbState m21 : 56|3@1+ (1,0) [0|0] "" Vector__XXX
 SG_ VCFRONT_chillerCOP1CoolantFlowRate m10 : 56|8@1+ (0.00196078431372549,0) [0|0] "" Vector__XXX
 SG_ VCFRONT_chillerCOP1CoolantInlet m22 : 56|7@1- (1.2698412698412698,0) [0|0] "" Vector__XXX
 SG_ VCFRONT_fanControlRadiatorInletTemp m12 : 56|6@1- (1.8,36) [0|0] "" Vector__XXX
 SG_ VCFRONT_hpCompPowerIndexFiltered m9 : 56|7@1+ (1,0) [0|0] "" Vector__XXX
 SG_ VCFRONT_hvCompCurrent m19 : 56|8@1+ (0.1,0) [0|0] "" Vector__XXX
 SG_ VCFRONT_lccExvCalibFailed m8 : 56|1@1+ (1,0) [0|0] "" Vector__XXX
 SG_ VCFRONT_maxCompressorRPMAllowed m11 : 56|7@1+ (90,0) [0|0] "" Vector__XXX
 SG_ VCFRONT_passiveCoolingState m6 : 56|2@1+ (1,0) [0|0] "" Vector__XXX
 SG_ VCFRONT_tempCoolantRadOutletEst m4 : 56|7@1- (1,23) [0|0] "" Vector__XXX
 SG_ VCFRONT_tempCoolantRadOutletEstStatus m16 : 56|2@1+ (1,0) [0|0] "" Vector__XXX
 SG_ VCFRONT_totalBattHeatingPower m14 : 56|7@1+ (150,0) [0|0] "" Vector__XXX
 SG_ VCFRONT_ccLeftExvCalibFailed m8 : 57|1@1+ (1,0) [0|0] "" Vector__XXX
 SG_ VCFRONT_lowerGlassHeaterCurrent m20 : 57|7@1+ (0.2,0) [0|0] "" Vector__XXX
 SG_ VCFRONT_pressureRefrigLiquidEst m17 : 57|6@1+ (0.5,0) [0|0] "" Vector__XXX
 SG_ VCFRONT_radiatorFanRunReason m1 : 57|4@1+ (1,0) [0|0] "" Vector__XXX
 SG_ VCFRONT_suctionSuperheatEstPsSNA m13 : 57|4@1+ (2,0) [0|0] "" Vector__XXX
 SG_ VCFRONT_usingModeledPs m2 : 57|1@1+ (1,0) [0|0] "" Vector__XXX
 SG_ VCFRONT_ccRightExvCalibFailed m8 : 58|1@1+ (1,0) [0|0] "" Vector__XXX
 SG_ VCFRONT_chargeShuttleType m18 : 58|2@1+ (1,0) [0|0] "" Vector__XXX
 SG_ VCFRONT_targetBatActiveCoolSource m16 : 58|3@1+ (1,0) [0|0] "" Vector__XXX
 SG_ VCFRONT_totalLoadCoolingDominant m6 : 58|1@1+ (1,0) [0|0] "" Vector__XXX
 SG_ VCFRONT_usingModeledPd m2 : 58|1@1+ (1,0) [0|0] "" Vector__XXX
 SG_ VCFRONT_vcleftFastBlowCounter m23 : 58|3@1+ (1,0) [0|0] "" Vector__XXX
 SG_ VCFRONT_vcrightFastBlowCounter m24 : 58|3@1+ (1,0) [0|0] "" Vector__XXX
 SG_ VCFRONT_ambientTempSniffActive m8 : 59|1@1+ (1,0) [0|0] "" Vector__XXX
 SG_ VCFRONT_feedfwdLoadCoolingDominant m6 : 59|1@1+ (1,0) [0|0] "" Vector__XXX
 SG_ VCFRONT_preventReEntryTillNexthpResetCOP1 m21 : 59|1@1+ (1,0) [0|0] "" Vector__XXX
 SG_ VCFRONT_refrigerantHasBeenFilled m5 : 59|1@1+ (1,0) [0|0] "" Vector__XXX
 SG_ VCFRONT_usingModeledPl m2 : 59|1@1+ (1,0) [0|0] "" Vector__XXX
 SG_ VCFRONT_ambientTempPassiveSniffing m8 : 60|1@1+ (1,0) [0|0] "" Vector__XXX
 SG_ VCFRONT_chillerBattHeatingPowerAvailable m21 : 60|1@1+ (1,0) [0|0] "" Vector__XXX
 SG_ VCFRONT_dtcConfirmed m3 : 60|1@1+ (1,0) [0|0] "" Vector__XXX
 SG_ VCFRONT_hpRefrigTempSensorCheckCanFire m18 : 60|1@1+ (1,0) [0|0] "" Vector__XXX
 SG_ VCFRONT_modelLoadCoolingDominant m6 : 60|1@1+ (1,0) [0|0] "" Vector__XXX
 SG_ VCFRONT_refCommissionStatus m5 : 60|2@1+ (1,0) [0|0] "" Vector__XXX
 SG_ VCFRONT_usingModeledTs m2 : 60|1@1+ (1,0) [0|0] "" Vector__XXX
 SG_ VCFRONT_ambientTempRadSampling m8 : 61|1@1+ (1,0) [0|0] "" Vector__XXX
 SG_ VCFRONT_autopilotAirPurgeRoutineState m3 : 61|3@1+ (1,0) [0|0] "" Vector__XXX
 SG_ VCFRONT_coolantValveModeWrong m1 : 61|1@1+ (1,0) [0|0] "" Vector__XXX
 SG_ VCFRONT_cycleModelConverged m7 : 61|1@1+ (1,0) [0|0] "" Vector__XXX
 SG_ VCFRONT_hpPotentialLowRefrig m6 : 61|1@1+ (1,0) [0|0] "" Vector__XXX
 SG_ VCFRONT_hpRefrigPressureSensorCheckCanFire m18 : 61|1@1+ (1,0) [0|0] "" Vector__XXX
 SG_ VCFRONT_isExpectedQChillerVeryHighCOP1 m21 : 61|1@1+ (1,0) [0|0] "" Vector__XXX
 SG_ VCFRONT_pdModelGrosslyOff m13 : 61|1@1+ (1,0) [0|0] "" Vector__XXX
 SG_ VCFRONT_targetPTActiveCoolSource m16 : 61|3@1+ (1,0) [0|0] "" Vector__XXX
 SG_ VCFRONT_usingModeledTd m2 : 61|1@1+ (1,0) [0|0] "" Vector__XXX
 SG_ VCFRONT_vcleftFastBlowCounter0 m23 : 61|3@1+ (1,0) [0|0] "" Vector__XXX
 SG_ VCFRONT_vcrightFastBlowCounter0 m24 : 61|3@1+ (1,0) [0|0] "" Vector__XXX
 SG_ VCFRONT_LCCPurgeActive m5 : 62|1@1+ (1,0) [0|0] "" Vector__XXX
 SG_ VCFRONT_ambientTempSpeedSampling m8 : 62|1@1+ (1,0) [0|0] "" Vector__XXX
 SG_ VCFRONT_autopilotAirPurgeRoutineCounter m21 : 62|2@1+ (1,0) [0|0] "" Vector__XXX
 SG_ VCFRONT_compStandbyCoastDownMode m7 : 62|1@1+ (1,0) [0|0] "" Vector__XXX
 SG_ VCFRONT_coolantTempBasedMode m1 : 62|2@1+ (1,0) [0|0] "" Vector__XXX
 SG_ VCFRONT_hpRefrigerantPurgeState m6 : 62|2@1+ (1,0) [0|0] "" Vector__XXX
 SG_ VCFRONT_psModelGrosslyOff m13 : 62|1@1+ (1,0) [0|0] "" Vector__XXX
 SG_ VCFRONT_usingModeledTl m2 : 62|1@1+ (1,0) [0|0] "" Vector__XXX
 SG_ VCFRONT_battAboveMaxCoolantTemp m13 : 63|1@1+ (1,0) [0|0] "" Vector__XXX
 SG_ VCFRONT_cmpIsentropicCheckPassed m17 : 63|1@1+ (1,0) [0|0] "" Vector__XXX
 SG_ VCFRONT_compStandbyOTA m9 : 63|1@1+ (1,0) [0|0] "" Vector__XXX
 SG_ VCFRONT_compStandbyShowroomMode m7 : 63|1@1+ (1,0) [0|0] "" Vector__XXX
 SG_ VCFRONT_hpPotentialFrozenRadiator m14 : 63|1@1+ (1,0) [0|0] "" Vector__XXX

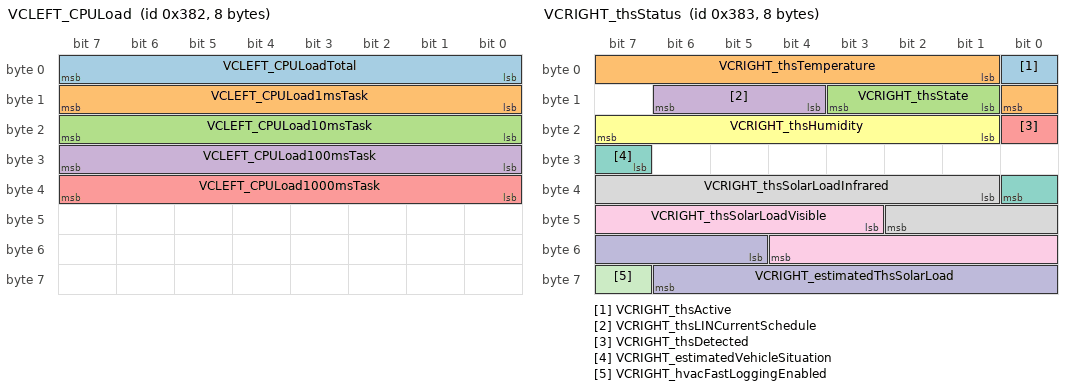
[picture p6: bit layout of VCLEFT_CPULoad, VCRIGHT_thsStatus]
BO_ 898 VCLEFT_CPULoad: 8 Vector__XXX
 SG_ VCLEFT_CPULoadTotal : 0|8@1+ (1,0) [0|0] "" Vector__XXX
 SG_ VCLEFT_CPULoad1msTask : 8|8@1+ (1,0) [0|0] "" Vector__XXX
 SG_ VCLEFT_CPULoad10msTask : 16|8@1+ (1,0) [0|0] "" Vector__XXX
 SG_ VCLEFT_CPULoad100msTask : 24|8@1+ (1,0) [0|0] "" Vector__XXX
 SG_ VCLEFT_CPULoad1000msTask : 32|8@1+ (1,0) [0|0] "" Vector__XXX

BO_ 899 VCRIGHT_thsStatus: 8 Vector__XXX
 SG_ VCRIGHT_thsActive : 0|1@1+ (1,0) [0|0] "" Vector__XXX
 SG_ VCRIGHT_thsTemperature : 1|8@1+ (1,-40) [0|0] "" Vector__XXX
 SG_ VCRIGHT_thsState : 9|3@1+ (1,0) [0|0] "" Vector__XXX
 SG_ VCRIGHT_thsLINCurrentSchedule : 12|3@1+ (1,0) [0|0] "" Vector__XXX
 SG_ VCRIGHT_thsDetected : 16|1@1+ (1,0) [0|0] "" Vector__XXX
 SG_ VCRIGHT_thsHumidity : 17|7@1+ (1,0) [0|0] "" Vector__XXX
 SG_ VCRIGHT_estimatedVehicleSituation : 31|2@1+ (1,0) [0|0] "" Vector__XXX
 SG_ VCRIGHT_thsSolarLoadInfrared : 33|10@1+ (2,0) [0|0] "" Vector__XXX
 SG_ VCRIGHT_thsSolarLoadVisible : 43|10@1+ (2,0) [0|0] "" Vector__XXX
 SG_ VCRIGHT_estimatedThsSolarLoad : 53|10@1+ (1,0) [0|0] "" Vector__XXX
 SG_ VCRIGHT_hvacFastLoggingEnabled : 63|1@1+ (1,0) [0|0] "" Vector__XXX

BO_ 900 PM_alertMatrix1: 8 Vector__XXX
 SG_ PM_a001_absoluteTorque : 0|1@1+ (1,0) [0|0] "" Vector__XXX
 SG_ PM_a002_excessiveAccelTorque : 1|1@1+ (1,0) [0|0] "" Vector__XXX
 SG_ PM_a003_excessiveReversalTorque : 2|1@1+ (1,0) [0|0] "" Vector__XXX
 SG_ PM_a004_excessiveDecelTorque : 3|1@1+ (1,0) [0|0] "" Vector__XXX
 SG_ PM_a005_torqueInNeutralOrPark : 4|1@1+ (1,0) [0|0] "" Vector__XXX
 SG_ PM_a006_inconsistentDIGear : 5|1@1+ (1,0) [0|0] "" Vector__XXX
 SG_ PM_a007_ibstMIA : 6|1@1+ (1,0) [0|0] "" Vector__XXX
 SG_ PM_a008_memoryError : 7|1@1+ (1,0) [0|0] "" Vector__XXX
 SG_ PM_a009_espMIA : 8|1@1+ (1,0) [0|0] "" Vector__XXX
 SG_ PM_a010_diMIA : 9|1@1+ (1,0) [0|0] "" Vector__XXX
 SG_ PM_a012_canDataBusA : 11|1@1+ (1,0) [0|0] "" Vector__XXX
 SG_ PM_a013_canHardwareBusA : 12|1@1+ (1,0) [0|0] "" Vector__XXX
 SG_ PM_a014_accelPedalError : 13|1@1+ (1,0) [0|0] "" Vector__XXX
 SG_ PM_a015_shifterMIA : 14|1@1+ (1,0) [0|0] "" Vector__XXX
 SG_ PM_a017_brakeMIA : 16|1@1+ (1,0) [0|0] "" Vector__XXX
 SG_ PM_a019_vehicleSpeedQFDiagnostic : 18|1@1+ (1,0) [0|0] "" Vector__XXX
 SG_ PM_a021_difMIA : 20|1@1+ (1,0) [0|0] "" Vector__XXX
 SG_ PM_a022_dirMIA : 21|1@1+ (1,0) [0|0] "" Vector__XXX
 SG_ PM_a023_cruiseInhibit : 22|1@1+ (1,0) [0|0] "" Vector__XXX
 SG_ PM_a024_brakeIrrational : 23|1@1+ (1,0) [0|0] "" Vector__XXX
 SG_ PM_a025_unintendedReset : 24|1@1+ (1,0) [0|0] "" Vector__XXX
 SG_ PM_a026_diHeartBeatMIA : 25|1@1+ (1,0) [0|0] "" Vector__XXX
 SG_ PM_a028_torqueCmdError : 27|1@1+ (1,0) [0|0] "" Vector__XXX
 SG_ PM_a029_cruiseRollback : 28|1@1+ (1,0) [0|0] "" Vector__XXX
 SG_ PM_a030_inconsistentAebState : 29|1@1+ (1,0) [0|0] "" Vector__XXX
 SG_ PM_a031_highStackUsage : 30|1@1+ (1,0) [0|0] "" Vector__XXX
 SG_ PM_a032_registerConfigError : 31|1@1+ (1,0) [0|0] "" Vector__XXX
 SG_ PM_a033_appMIA : 32|1@1+ (1,0) [0|0] "" Vector__XXX
 SG_ PM_a034_trqCrossCheck : 33|1@1+ (1,0) [0|0] "" Vector__XXX
 SG_ PM_a035_udsTransactionInitiated : 34|1@1+ (1,0) [0|0] "" Vector__XXX
 SG_ PM_a036_preWatchdog : 35|1@1+ (1,0) [0|0] "" Vector__XXX
 SG_ PM_a038_inconsistentTorqueSign : 37|1@1+ (1,0) [0|0] "" Vector__XXX
 SG_ PM_a039_disMIA : 38|1@1+ (1,0) [0|0] "" Vector__XXX
 SG_ PM_a040_alignmentDriftDetected : 39|1@1+ (1,0) [0|0] "" Vector__XXX
 SG_ PM_a041_dasMIA : 40|1@1+ (1,0) [0|0] "" Vector__XXX
 SG_ PM_a042_gtwMIA : 41|1@1+ (1,0) [0|0] "" Vector__XXX
 SG_ PM_a043_inconsistentConfig : 42|1@1+ (1,0) [0|0] "" Vector__XXX
 SG_ PM_a044_ebrIntervention : 43|1@1+ (1,0) [0|0] "" Vector__XXX
 SG_ PM_a045_regenBackfillIntervention : 44|1@1+ (1,0) [0|0] "" Vector__XXX
 SG_ PM_a046_inconsVehicleHoldState : 45|1@1+ (1,0) [0|0] "" Vector__XXX
 SG_ PM_a047_inconsAutoparkState : 46|1@1+ (1,0) [0|0] "" Vector__XXX
 SG_ PM_a048_stabilityControlInhibit : 47|1@1+ (1,0) [0|0] "" Vector__XXX
 SG_ PM_a049_stbCtrlInWrongDir : 48|1@1+ (1,0) [0|0] "" Vector__XXX
 SG_ PM_a050_excessiveStbCtrlTrq : 49|1@1+ (1,0) [0|0] "" Vector__XXX
 SG_ PM_a051_unintDecelStbCtrl : 50|1@1+ (1,0) [0|0] "" Vector__XXX
 SG_ PM_a052_stbCtrlDrvrDecelCflct : 51|1@1+ (1,0) [0|0] "" Vector__XXX
 SG_ PM_a053_vcfrontMIA : 52|1@1+ (1,0) [0|0] "" Vector__XXX
 SG_ PM_a054_uiMIA : 53|1@1+ (1,0) [0|0] "" Vector__XXX
 SG_ PM_a055_accelPedalSyncWarn : 54|1@1+ (1,0) [0|0] "" Vector__XXX
 SG_ PM_a056_canHardwareBusB : 55|1@1+ (1,0) [0|0] "" Vector__XXX
 SG_ PM_a057_canDataBusB : 56|1@1+ (1,0) [0|0] "" Vector__XXX
 SG_ PM_a058_cmpMIA : 57|1@1+ (1,0) [0|0] "" Vector__XXX
 SG_ PM_a059_ptcMIA : 58|1@1+ (1,0) [0|0] "" Vector__XXX
 SG_ PM_a060_onePedalDrivingInhibit : 59|1@1+ (1,0) [0|0] "" Vector__XXX
 SG_ PM_a061_DIPMVersionMismatch : 60|1@1+ (1,0) [0|0] "" Vector__XXX
 SG_ PM_a062_eccError : 61|1@1+ (1,0) [0|0] "" Vector__XXX
 SG_ PM_a063_torqueCommandInhibit : 62|1@1+ (1,0) [0|0] "" Vector__XXX
 SG_ PM_a064_torqueIntervention : 63|1@1+ (1,0) [0|0] "" Vector__XXX

BO_ 902 PMR_alertMatrix1: 8 Vector__XXX
 SG_ PMR_a001_absoluteTorque : 0|1@1+ (1,0) [0|0] "" Vector__XXX
 SG_ PMR_a002_excessiveAccelTorque : 1|1@1+ (1,0) [0|0] "" Vector__XXX
 SG_ PMR_a003_excessiveReversalTorque : 2|1@1+ (1,0) [0|0] "" Vector__XXX
 SG_ PMR_a004_excessiveDecelTorque : 3|1@1+ (1,0) [0|0] "" Vector__XXX
 SG_ PMR_a005_torqueInNeutralOrPark : 4|1@1+ (1,0) [0|0] "" Vector__XXX
 SG_ PMR_a008_memoryError : 7|1@1+ (1,0) [0|0] "" Vector__XXX
 SG_ PMR_a010_diMIA : 9|1@1+ (1,0) [0|0] "" Vector__XXX
 SG_ PMR_a011_phaseCurrentIrrational : 10|1@1+ (1,0) [0|0] "" Vector__XXX
 SG_ PMR_a012_canDataBusA : 11|1@1+ (1,0) [0|0] "" Vector__XXX
 SG_ PMR_a013_canHardwareBusA : 12|1@1+ (1,0) [0|0] "" Vector__XXX
 SG_ PMR_a017_brakeMIA : 16|1@1+ (1,0) [0|0] "" Vector__XXX
 SG_ PMR_a018_encoderIrrational : 17|1@1+ (1,0) [0|0] "" Vector__XXX
 SG_ PMR_a019_statorTempIrrational : 18|1@1+ (1,0) [0|0] "" Vector__XXX
 SG_ PMR_a025_unintendedReset : 24|1@1+ (1,0) [0|0] "" Vector__XXX
 SG_ PMR_a026_diHeartBeatMIA : 25|1@1+ (1,0) [0|0] "" Vector__XXX
 SG_ PMR_a027_torqueEstimationOutOfBounds : 26|1@1+ (1,0) [0|0] "" Vector__XXX
 SG_ PMR_a028_torqueCmdError : 27|1@1+ (1,0) [0|0] "" Vector__XXX
 SG_ PMR_a031_highStackUsage : 30|1@1+ (1,0) [0|0] "" Vector__XXX
 SG_ PMR_a032_registerConfigError : 31|1@1+ (1,0) [0|0] "" Vector__XXX
 SG_ PMR_a033_selfTest : 32|1@1+ (1,0) [0|0] "" Vector__XXX
 SG_ PMR_a034_trqCrossCheck : 33|1@1+ (1,0) [0|0] "" Vector__XXX
 SG_ PMR_a035_udsTransactionInitiated : 34|1@1+ (1,0) [0|0] "" Vector__XXX
 SG_ PMR_a036_preWatchdog : 35|1@1+ (1,0) [0|0] "" Vector__XXX
 SG_ PMR_a037_hvpMIA : 36|1@1+ (1,0) [0|0] "" Vector__XXX
 SG_ PMR_a039_disMIA : 38|1@1+ (1,0) [0|0] "" Vector__XXX
 SG_ PMR_a040_pmMIA : 39|1@1+ (1,0) [0|0] "" Vector__XXX
 SG_ PMR_a042_gtwMIA : 41|1@1+ (1,0) [0|0] "" Vector__XXX
 SG_ PMR_a045_motorMovementDetected : 44|1@1+ (1,0) [0|0] "" Vector__XXX
 SG_ PMR_a053_vcfrontMIA : 52|1@1+ (1,0) [0|0] "" Vector__XXX
 SG_ PMR_a054_uiMIA : 53|1@1+ (1,0) [0|0] "" Vector__XXX
 SG_ PMR_a055_resolver : 54|1@1+ (1,0) [0|0] "" Vector__XXX
 SG_ PMR_a056_canHardwareBusB : 55|1@1+ (1,0) [0|0] "" Vector__XXX
 SG_ PMR_a057_canDataBusB : 56|1@1+ (1,0) [0|0] "" Vector__XXX
 SG_ PMR_a061_DIPMVersionMismatch : 60|1@1+ (1,0) [0|0] "" Vector__XXX
 SG_ PMR_a062_eccError : 61|1@1+ (1,0) [0|0] "" Vector__XXX
 SG_ PMR_a064_torqueIntervention : 63|1@1+ (1,0) [0|0] "" Vector__XXX

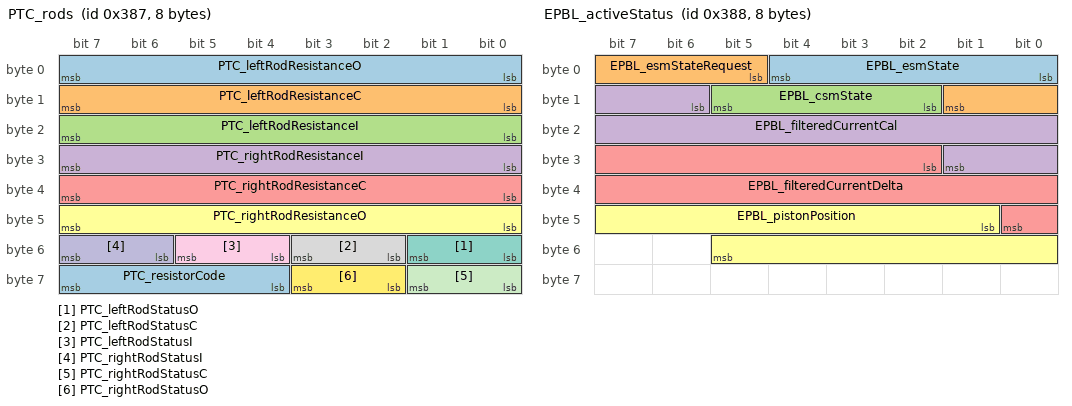
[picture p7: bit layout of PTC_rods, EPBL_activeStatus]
BO_ 903 PTC_rods: 8 Vector__XXX
 SG_ PTC_leftRodResistanceO : 0|8@1+ (2,0) [0|0] "" Vector__XXX
 SG_ PTC_leftRodResistanceC : 8|8@1+ (2,0) [0|0] "" Vector__XXX
 SG_ PTC_leftRodResistanceI : 16|8@1+ (2,0) [0|0] "" Vector__XXX
 SG_ PTC_rightRodResistanceI : 24|8@1+ (2,0) [0|0] "" Vector__XXX
 SG_ PTC_rightRodResistanceC : 32|8@1+ (2,0) [0|0] "" Vector__XXX
 SG_ PTC_rightRodResistanceO : 40|8@1+ (2,0) [0|0] "" Vector__XXX
 SG_ PTC_leftRodStatusO : 48|2@1+ (1,0) [0|0] "" Vector__XXX
 SG_ PTC_leftRodStatusC : 50|2@1+ (1,0) [0|0] "" Vector__XXX
 SG_ PTC_leftRodStatusI : 52|2@1+ (1,0) [0|0] "" Vector__XXX
 SG_ PTC_rightRodStatusI : 54|2@1+ (1,0) [0|0] "" Vector__XXX
 SG_ PTC_rightRodStatusC : 56|2@1+ (1,0) [0|0] "" Vector__XXX
 SG_ PTC_rightRodStatusO : 58|2@1+ (1,0) [0|0] "" Vector__XXX
 SG_ PTC_resistorCode : 60|4@1+ (1,0) [0|0] "" Vector__XXX

BO_ 904 EPBL_activeStatus: 8 Vector__XXX
 SG_ EPBL_esmState : 0|5@1+ (1,0) [0|0] "" Vector__XXX
 SG_ EPBL_esmStateRequest : 5|5@1+ (1,0) [0|0] "" Vector__XXX
 SG_ EPBL_csmState : 10|4@1+ (1,0) [0|0] "" Vector__XXX
 SG_ EPBL_filteredCurrentCal : 14|12@1+ (0.01,0) [0|0] "" Vector__XXX
 SG_ EPBL_filteredCurrentDelta : 26|15@1- (0.01,0) [0|0] "" Vector__XXX
 SG_ EPBL_pistonPosition : 41|13@1- (9.768009768009769,0) [0|0] "" Vector__XXX

BO_ 906 VCSEC_NFCCurrentCardUID: 8 Vector__XXX
 SG_ VCSEC_NFCReaderIndexUID M : 0|2@1+ (1,0) [0|0] "" Vector__XXX
 SG_ VCSEC_BPillarNFCCardUIDL m0 : 8|56@1+ (1,0) [0|0] "" Vector__XXX
 SG_ VCSEC_BPillarNFCCardUIDR m1 : 8|56@1+ (1,0) [0|0] "" Vector__XXX
 SG_ VCSEC_CenterNFCCardUID m3 : 8|56@1+ (1,0) [0|0] "" Vector__XXX

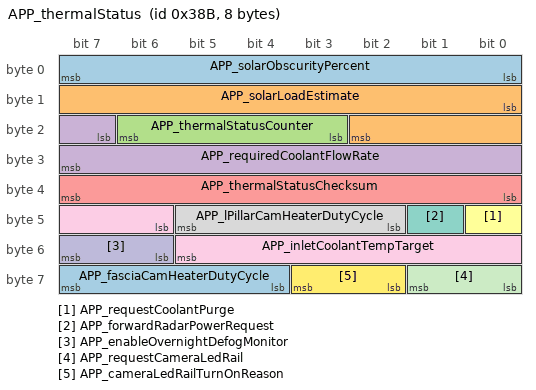
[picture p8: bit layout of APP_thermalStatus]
BO_ 907 APP_thermalStatus: 8 Vector__XXX
 SG_ APP_solarObscurityPercent : 0|8@1+ (0.5,-25) [0|0] "" Vector__XXX
 SG_ APP_solarLoadEstimate : 8|11@1+ (1,0) [0|0] "" Vector__XXX
 SG_ APP_thermalStatusCounter : 19|4@1+ (1,0) [0|0] "" Vector__XXX
 SG_ APP_requiredCoolantFlowRate : 23|9@1+ (0.1,0) [0|0] "" Vector__XXX
 SG_ APP_thermalStatusChecksum : 32|8@1+ (1,0) [0|0] "" Vector__XXX
 SG_ APP_requestCoolantPurge : 40|1@1+ (1,0) [0|0] "" Vector__XXX
 SG_ APP_forwardRadarPowerRequest : 41|1@1+ (1,0) [0|0] "" Vector__XXX
 SG_ APP_lPillarCamHeaterDutyCycle : 42|4@1+ (0.06666666666666667,0) [0|0] "" Vector__XXX
 SG_ APP_inletCoolantTempTarget : 46|8@1+ (0.5,0) [0|0] "" Vector__XXX
 SG_ APP_enableOvernightDefogMonitor : 54|2@1+ (1,0) [0|0] "" Vector__XXX
 SG_ APP_requestCameraLedRail : 56|2@1+ (1,0) [0|0] "" Vector__XXX
 SG_ APP_cameraLedRailTurnOnReason : 58|2@1+ (1,0) [0|0] "" Vector__XXX
 SG_ APP_fasciaCamHeaterDutyCycle : 60|4@1+ (0.06666666666666667,0) [0|0] "" Vector__XXX

BO_ 909 APP_VC_infoMessage: 8 Vector__XXX
 SG_ APP_inTunnel : 0|2@1+ (1,0) [0|0] "" Vector__XXX
 SG_ APP_windshieldHeaterOnReason : 2|3@1+ (1,0) [0|0] "" Vector__XXX
 SG_ APP_selfieCameraBlocked : 6|2@1+ (1,0) [0|0] "" Vector__XXX
 SG_ APP_selfieCameraLUX : 8|8@1+ (1,0) [0|0] "" Vector__XXX
 SG_ APP_sceneTagClearlyRaining : 16|2@1+ (1,0) [0|0] "" Vector__XXX
 SG_ APP_sceneTagFog : 18|2@1+ (1,0) [0|0] "" Vector__XXX
 SG_ APP_sceneTagFullyBlocked : 20|2@1+ (1,0) [0|0] "" Vector__XXX
 SG_ APP_sceneTagIndoors : 22|2@1+ (1,0) [0|0] "" Vector__XXX
 SG_ APP_sceneTagLensFlare : 24|2@1+ (1,0) [0|0] "" Vector__XXX
 SG_ APP_sceneTagRaining : 26|2@1+ (1,0) [0|0] "" Vector__XXX
 SG_ APP_sceneTagSevereWeather : 28|2@1+ (1,0) [0|0] "" Vector__XXX
 SG_ APP_sceneTagSnowing : 30|2@1+ (1,0) [0|0] "" Vector__XXX
 SG_ APP_sceneTagSnowyRoad : 32|2@1+ (1,0) [0|0] "" Vector__XXX
 SG_ APP_sceneTagSunGlare : 34|2@1+ (1,0) [0|0] "" Vector__XXX
 SG_ APP_sceneTagTunnel : 36|2@1+ (1,0) [0|0] "" Vector__XXX
 SG_ APP_sceneTagWetRoad : 38|2@1+ (1,0) [0|0] "" Vector__XXX
 SG_ APP_fisheyeInPathVisibility : 40|3@1+ (1,0) [0|0] "" Vector__XXX
 SG_ APP_fisheyeOverallVisibility : 43|3@1+ (1,0) [0|0] "" Vector__XXX
 SG_ APP_mainInPathVisibility : 46|3@1+ (1,0) [0|0] "" Vector__XXX
 SG_ APP_mainOverallVisibility : 49|3@1+ (1,0) [0|0] "" Vector__XXX
 SG_ APP_narrowInPathVisibility : 52|3@1+ (1,0) [0|0] "" Vector__XXX
 SG_ APP_narrowOverallVisibility : 55|3@1+ (1,0) [0|0] "" Vector__XXX
 SG_ APP_frontCamOcclusionType : 58|3@1+ (1,0) [0|0] "" Vector__XXX
